VERSION "HNNBNNNYNNNNNNNNNNNNNNNNNNNNNNNNNNNNNNNNNN/4/%%%/4/'%**4NNN///"

NS_ :

BS_:

BU_: Aero_LB AFS_MLB Airbag_B8 BCM1_B8 Gateway_B8 Getriebe_AL551_651_B8 Getriebe_AL551_Q5_Hybrid Getriebe_SL_LB Lift_MLB_LB LWR_MLB Magnetic_Ride_LB Motor_MLB_AU48_AU416_Diesel Motor_MLB_B8_Q5_Otto Motor_MLB_Q5_Hybrid Niveau_LB Airbag_D4 BMS_Hybrid Daempfer_MLB EPB_MLB ESP Gateway Getriebe_AL551_951_D4_C7 Getriebe_AL551_Hybrid_D4_C7 Getriebe_DL382_MLB Getriebe_DL501_MLB Getriebe_VL381_MLB LEH_Hybrid LWS_D4 Motor2_MLB_D4_C7 Motor_MLB_AU64_AU57_Diesel Motor_MLB_BY_Otto Motor_MLB_C7_PHEV Motor_MLB_D4_C7_Hybrid Motor_MLB_D4_C7_Otto QSP SAK SAK2 SCR_MLB SCU

BO_ 2617042433 CCP_Soundaktor_DTO_01: 8 SAK
 SG_ CCP_Soundaktor_DTO_01_Data : 0|64@1+ (1,0) [0|1.84467440737096E+019] "" Vector__XXX

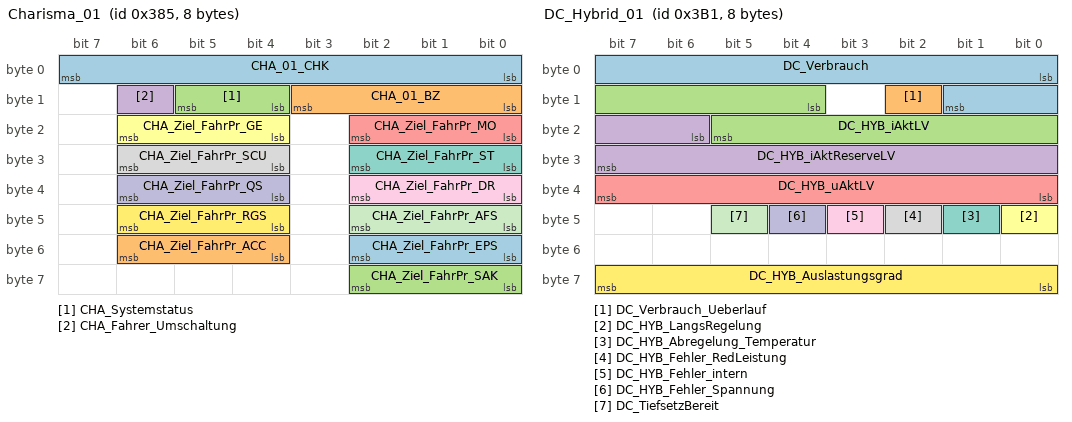
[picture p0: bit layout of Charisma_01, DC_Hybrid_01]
BO_ 901 Charisma_01: 8 Gateway
 SG_ CHA_01_CHK : 0|8@1+ (1,0) [0|255] ""  Daempfer_MLB,Getriebe_AL551_951_D4_C7,Getriebe_AL551_Hybrid_D4_C7,Getriebe_DL382_MLB,Getriebe_DL501_MLB,Getriebe_VL381_MLB,Motor_MLB_AU64_AU57_Diesel,Motor_MLB_BY_Otto,Motor_MLB_C7_PHEV,Motor_MLB_D4_C7_Hybrid,Motor_MLB_D4_C7_Otto,SCU
 SG_ CHA_01_BZ : 8|4@1+ (1,0) [0|15] "" Vector__XXX
 SG_ CHA_Systemstatus : 12|2@1+ (1,0) [0|3] ""  Daempfer_MLB,Getriebe_AL551_951_D4_C7,Getriebe_AL551_Hybrid_D4_C7,Getriebe_DL382_MLB,Getriebe_DL501_MLB,Getriebe_VL381_MLB,Motor_MLB_AU64_AU57_Diesel,Motor_MLB_BY_Otto,Motor_MLB_C7_PHEV,Motor_MLB_D4_C7_Hybrid,Motor_MLB_D4_C7_Otto,SAK,SAK2,SCU
 SG_ CHA_Fahrer_Umschaltung : 14|1@1+ (1,0) [0|1] "" Vector__XXX
 SG_ CHA_Ziel_FahrPr_MO : 16|3@1+ (1,0) [0|7] ""  Motor_MLB_AU64_AU57_Diesel,Motor_MLB_BY_Otto,Motor_MLB_C7_PHEV,Motor_MLB_D4_C7_Hybrid,Motor_MLB_D4_C7_Otto
 SG_ CHA_Ziel_FahrPr_GE : 20|3@1+ (1,0) [0|7] ""  Getriebe_AL551_951_D4_C7,Getriebe_AL551_Hybrid_D4_C7,Getriebe_DL382_MLB,Getriebe_DL501_MLB,Getriebe_VL381_MLB
 SG_ CHA_Ziel_FahrPr_ST : 24|3@1+ (1,0) [0|7] "" Vector__XXX
 SG_ CHA_Ziel_FahrPr_SCU : 28|3@1+ (1,0) [0|7] ""  SCU
 SG_ CHA_Ziel_FahrPr_DR : 32|3@1+ (1,0) [0|7] ""  Daempfer_MLB
 SG_ CHA_Ziel_FahrPr_QS : 36|3@1+ (1,0) [0|7] "" Vector__XXX
 SG_ CHA_Ziel_FahrPr_AFS : 40|3@1+ (1,0) [0|7] "" Vector__XXX
 SG_ CHA_Ziel_FahrPr_RGS : 44|3@1+ (1,0) [0|7] "" Vector__XXX
 SG_ CHA_Ziel_FahrPr_EPS : 48|3@1+ (1,0) [0|7] "" Vector__XXX
 SG_ CHA_Ziel_FahrPr_ACC : 52|3@1+ (1,0) [0|7] "" Vector__XXX
 SG_ CHA_Ziel_FahrPr_SAK : 56|3@1+ (1,0) [0|7] ""  Motor_MLB_AU64_AU57_Diesel,Motor_MLB_BY_Otto,Motor_MLB_C7_PHEV,Motor_MLB_D4_C7_Hybrid,Motor_MLB_D4_C7_Otto,SAK,SAK2

BO_ 918 Daempfer_01_FR: 8 Daempfer_MLB
 SG_ Daempfer_01_CHK : 0|8@1+ (1,0) [0|255] ""  Gateway
 SG_ Daempfer_01_BZ : 8|4@1+ (1,0) [0|15] ""  Gateway
 SG_ DR_Systemstatus : 12|3@1+ (1,0) [0|7] ""  Gateway
 SG_ LF_Texte : 15|2@1+ (1,0) [0|3] ""  Gateway
 SG_ DR_Taster : 17|1@1+ (1,0) [0|1] ""  Gateway
 SG_ DR_Gelbe_Warnlampe : 18|2@1+ (1,0) [0|3] ""  Gateway
 SG_ DR_Daempferreg_Texte : 20|4@1+ (1,0) [0|15] ""  Gateway
 SG_ DR_Charisma_FahrPr : 24|3@1+ (1,0) [0|7] ""  Gateway
 SG_ DR_Charisma_Status : 27|2@1+ (1,0) [0|3] ""  Gateway
 SG_ DR_Charisma_Umschaltung : 29|2@1+ (1,0) [0|3] ""  Gateway
 SG_ DR_Fahrzeugart : 32|4@1+ (1,0) [0|15] ""  Gateway
 SG_ LF_Warnung_Prio1 : 36|2@1+ (1,0) [0|3] ""  Gateway
 SG_ LF_Warnung_Prio2 : 38|2@1+ (1,0) [0|3] ""  Gateway
 SG_ DR_DynAGL_Warnlampe : 40|1@1+ (1,0) [0|1] ""  Gateway
 SG_ DR_Rote_Warnlampe : 41|2@1+ (1,0) [0|3] ""  Gateway
 SG_ NI_Status : 43|3@1+ (1,0) [0|7] ""  Gateway
 SG_ NR_Niveaufunktion_aktiv : 46|2@1+ (1,0) [0|3] ""  Gateway
 SG_ DR_KD_Fehler : 63|1@1+ (1,0) [0|1] ""  Gateway

BO_ 945 DC_Hybrid_01: 8 LEH_Hybrid
 SG_ DC_Verbrauch : 0|10@1+ (1,0) [0|1023] "Unit_WattSecond" Vector__XXX
 SG_ DC_Verbrauch_Ueberlauf : 10|1@1+ (1,0) [0|1] "" Vector__XXX
 SG_ DC_HYB_iAktLV : 12|10@1+ (1,-511) [-511|510] "Unit_Amper"  Gateway
 SG_ DC_HYB_iAktReserveLV : 22|10@1+ (1,-511) [-511|510] "Unit_Amper"  Gateway
 SG_ DC_HYB_uAktLV : 32|8@1+ (0.1,0) [0|25.3] "Unit_Volt"  Gateway
 SG_ DC_HYB_LangsRegelung : 40|1@1+ (1,0) [0|1] ""  Gateway
 SG_ DC_HYB_Abregelung_Temperatur : 41|1@1+ (1,0) [0|1] ""  Gateway
 SG_ DC_HYB_Fehler_RedLeistung : 42|1@1+ (1,0) [0|1] ""  Gateway
 SG_ DC_HYB_Fehler_intern : 43|1@1+ (1,0) [0|1] ""  Gateway
 SG_ DC_HYB_Fehler_Spannung : 44|1@1+ (1,0) [0|1] ""  Gateway
 SG_ DC_TiefsetzBereit : 45|1@1+ (1,0) [0|1] "" Vector__XXX
 SG_ DC_HYB_Auslastungsgrad : 56|8@1+ (0.4,0) [0|100] "Unit_PerCent" Vector__XXX

BO_ 2617027072 DEV_Airbag_01: 4 Airbag_D4
 SG_ DEV_Airbag_01 : 0|32@1+ (1,0) [0|4294967295] "" Vector__XXX

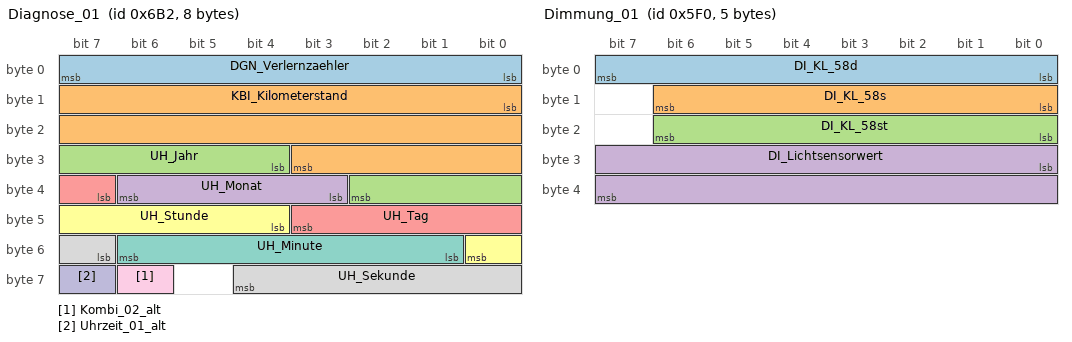
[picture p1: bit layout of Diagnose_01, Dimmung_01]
BO_ 1714 Diagnose_01: 8 Gateway
 SG_ DGN_Verlernzaehler : 0|8@1+ (1,0) [0|254] ""  Airbag_D4,BMS_Hybrid,Daempfer_MLB,EPB_MLB,Getriebe_AL551_951_D4_C7,Getriebe_AL551_Hybrid_D4_C7,LEH_Hybrid,SAK,SAK2,SCR_MLB,SCU
 SG_ KBI_Kilometerstand : 8|20@1+ (1,0) [0|1048573] "Unit_KiloMeter"  Airbag_D4,BMS_Hybrid,Daempfer_MLB,EPB_MLB,Getriebe_AL551_951_D4_C7,Getriebe_AL551_Hybrid_D4_C7,Getriebe_DL382_MLB,Getriebe_DL501_MLB,Getriebe_VL381_MLB,LEH_Hybrid,Motor_MLB_AU64_AU57_Diesel,Motor_MLB_BY_Otto,Motor_MLB_C7_PHEV,Motor_MLB_D4_C7_Hybrid,Motor_MLB_D4_C7_Otto,SAK,SAK2,SCR_MLB,SCU
 SG_ UH_Jahr : 28|7@1+ (1,2000) [2000|2127] "Unit_Year"  Airbag_D4,BMS_Hybrid,Daempfer_MLB,EPB_MLB,Getriebe_AL551_951_D4_C7,Getriebe_AL551_Hybrid_D4_C7,Getriebe_DL382_MLB,Getriebe_DL501_MLB,Getriebe_VL381_MLB,LEH_Hybrid,Motor_MLB_AU64_AU57_Diesel,Motor_MLB_BY_Otto,Motor_MLB_C7_PHEV,Motor_MLB_D4_C7_Hybrid,Motor_MLB_D4_C7_Otto,SAK,SAK2,SCR_MLB,SCU
 SG_ UH_Monat : 35|4@1+ (1,0) [1|12] "Unit_Month"  Airbag_D4,BMS_Hybrid,Daempfer_MLB,EPB_MLB,Getriebe_AL551_951_D4_C7,Getriebe_AL551_Hybrid_D4_C7,Getriebe_DL382_MLB,Getriebe_DL501_MLB,Getriebe_VL381_MLB,LEH_Hybrid,Motor_MLB_AU64_AU57_Diesel,Motor_MLB_BY_Otto,Motor_MLB_C7_PHEV,Motor_MLB_D4_C7_Hybrid,Motor_MLB_D4_C7_Otto,SAK,SAK2,SCR_MLB,SCU
 SG_ UH_Tag : 39|5@1+ (1,0) [1|31] "Unit_Day"  Airbag_D4,BMS_Hybrid,Daempfer_MLB,EPB_MLB,Getriebe_AL551_951_D4_C7,Getriebe_AL551_Hybrid_D4_C7,Getriebe_DL382_MLB,Getriebe_DL501_MLB,Getriebe_VL381_MLB,LEH_Hybrid,Motor_MLB_AU64_AU57_Diesel,Motor_MLB_BY_Otto,Motor_MLB_C7_PHEV,Motor_MLB_D4_C7_Hybrid,Motor_MLB_D4_C7_Otto,SAK,SAK2,SCR_MLB,SCU
 SG_ UH_Stunde : 44|5@1+ (1,0) [0|23] "Unit_Hours"  Airbag_D4,BMS_Hybrid,Daempfer_MLB,EPB_MLB,Getriebe_AL551_951_D4_C7,Getriebe_AL551_Hybrid_D4_C7,Getriebe_DL382_MLB,Getriebe_DL501_MLB,Getriebe_VL381_MLB,LEH_Hybrid,Motor_MLB_AU64_AU57_Diesel,Motor_MLB_BY_Otto,Motor_MLB_C7_PHEV,Motor_MLB_D4_C7_Hybrid,Motor_MLB_D4_C7_Otto,SAK,SAK2,SCR_MLB,SCU
 SG_ UH_Minute : 49|6@1+ (1,0) [0|59] "Unit_Minut"  Airbag_D4,BMS_Hybrid,Daempfer_MLB,EPB_MLB,Getriebe_AL551_951_D4_C7,Getriebe_AL551_Hybrid_D4_C7,Getriebe_DL382_MLB,Getriebe_DL501_MLB,Getriebe_VL381_MLB,LEH_Hybrid,Motor_MLB_AU64_AU57_Diesel,Motor_MLB_BY_Otto,Motor_MLB_C7_PHEV,Motor_MLB_D4_C7_Hybrid,Motor_MLB_D4_C7_Otto,SAK,SAK2,SCR_MLB,SCU
 SG_ UH_Sekunde : 55|6@1+ (1,0) [0|59] "Unit_Secon"  Airbag_D4,BMS_Hybrid,Daempfer_MLB,EPB_MLB,Getriebe_AL551_951_D4_C7,Getriebe_AL551_Hybrid_D4_C7,Getriebe_DL382_MLB,Getriebe_DL501_MLB,Getriebe_VL381_MLB,LEH_Hybrid,Motor_MLB_AU64_AU57_Diesel,Motor_MLB_BY_Otto,Motor_MLB_C7_PHEV,Motor_MLB_D4_C7_Hybrid,Motor_MLB_D4_C7_Otto,SAK,SAK2,SCR_MLB,SCU
 SG_ Kombi_02_alt : 62|1@1+ (1,0) [0|1] ""  Airbag_D4,BMS_Hybrid,EPB_MLB,Getriebe_AL551_951_D4_C7,Getriebe_AL551_Hybrid_D4_C7,Getriebe_DL382_MLB,Getriebe_DL501_MLB,Getriebe_VL381_MLB,LEH_Hybrid,SCR_MLB
 SG_ Uhrzeit_01_alt : 63|1@1+ (1,0) [0|1] ""  Airbag_D4,BMS_Hybrid,EPB_MLB,Getriebe_AL551_951_D4_C7,Getriebe_AL551_Hybrid_D4_C7,Getriebe_DL382_MLB,Getriebe_DL501_MLB,Getriebe_VL381_MLB,LEH_Hybrid,SCR_MLB

BO_ 1520 Dimmung_01: 5 Gateway
 SG_ DI_KL_58d : 0|8@1+ (1,0) [0|253] ""  Airbag_D4,EPB_MLB,Getriebe_AL551_951_D4_C7,Getriebe_AL551_Hybrid_D4_C7
 SG_ DI_KL_58s : 8|7@1+ (1,0) [0|100] "Unit_PerCent"  Getriebe_AL551_951_D4_C7,Getriebe_AL551_Hybrid_D4_C7
 SG_ DI_KL_58st : 16|7@1+ (1,0) [0|100] "Unit_PerCent"  Getriebe_AL551_951_D4_C7,Getriebe_AL551_Hybrid_D4_C7
 SG_ DI_Lichtsensorwert : 24|16@1+ (1,0) [0|65535] ""  Airbag_D4,Getriebe_AL551_951_D4_C7,Getriebe_AL551_Hybrid_D4_C7

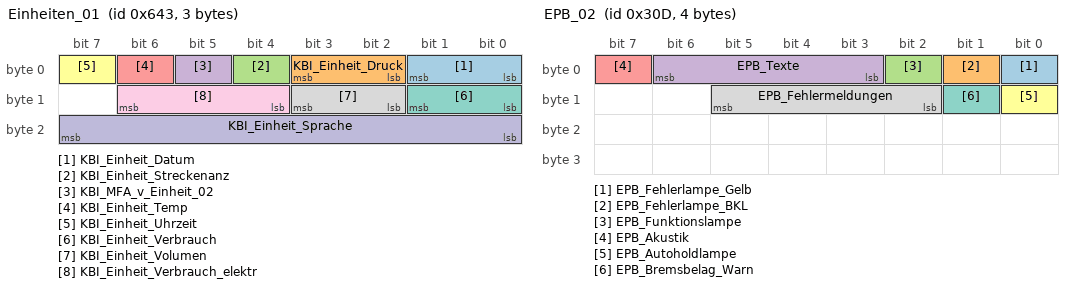
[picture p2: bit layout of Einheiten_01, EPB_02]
BO_ 1603 Einheiten_01: 3 Gateway
 SG_ KBI_Einheit_Datum : 0|2@1+ (1,0) [0|3] "" Vector__XXX
 SG_ KBI_Einheit_Druck : 2|2@1+ (1,0) [0|3] "" Vector__XXX
 SG_ KBI_Einheit_Streckenanz : 4|1@1+ (1,0) [0|1] ""  Motor_MLB_AU64_AU57_Diesel
 SG_ KBI_MFA_v_Einheit_02 : 5|1@1+ (1,0) [0|1] "" Vector__XXX
 SG_ KBI_Einheit_Temp : 6|1@1+ (1,0) [0|1] "" Vector__XXX
 SG_ KBI_Einheit_Uhrzeit : 7|1@1+ (1,0) [0|1] "" Vector__XXX
 SG_ KBI_Einheit_Verbrauch : 8|2@1+ (1,0) [0|3] "" Vector__XXX
 SG_ KBI_Einheit_Volumen : 10|2@1+ (1,0) [0|3] "" Vector__XXX
 SG_ KBI_Einheit_Verbrauch_elektr : 12|3@1+ (1,0) [0|7] "" Vector__XXX
 SG_ KBI_Einheit_Sprache : 16|8@1+ (1,0) [0|255] "" Vector__XXX

BO_ 1627 EM_Hybrid_01: 8 LEH_Hybrid
 SG_ EM_HYB_KD_Fehler : 15|1@1+ (1,0) [0|1] ""  Gateway

BO_ 260 EPB_01: 8 EPB_MLB
 SG_ EPB_01_CHK : 0|8@1+ (1,0) [0|255] ""  Gateway,Motor_MLB_AU64_AU57_Diesel,Motor_MLB_BY_Otto,Motor_MLB_C7_PHEV,Motor_MLB_D4_C7_Hybrid,Motor_MLB_D4_C7_Otto
 SG_ EPB_01_BZ : 8|4@1+ (1,0) [0|15] ""  Gateway,Motor_MLB_AU64_AU57_Diesel,Motor_MLB_BY_Otto,Motor_MLB_C7_PHEV,Motor_MLB_D4_C7_Hybrid,Motor_MLB_D4_C7_Otto
 SG_ EPB_QBit_Laengsbeschleunigung : 12|1@1+ (1,0) [0|1] ""  Gateway,Getriebe_AL551_951_D4_C7,Getriebe_AL551_Hybrid_D4_C7
 SG_ EPB_QBit_Pedalweg_Kuppl : 13|1@1+ (1,0) [0|1] ""  Gateway,Motor_MLB_AU64_AU57_Diesel,Motor_MLB_BY_Otto,Motor_MLB_C7_PHEV,Motor_MLB_D4_C7_Hybrid,Motor_MLB_D4_C7_Otto
 SG_ EPB_BCM2_Motor_Wakeup : 14|1@1+ (1,0) [0|1] ""  Gateway
 SG_ EPB_Freig_Verzoeg_Anf : 15|1@1+ (1,0) [0|1] ""  Gateway,Getriebe_AL551_951_D4_C7,Getriebe_AL551_Hybrid_D4_C7,Motor_MLB_AU64_AU57_Diesel,Motor_MLB_BY_Otto,Motor_MLB_C7_PHEV,Motor_MLB_D4_C7_Hybrid,Motor_MLB_D4_C7_Otto
 SG_ EPB_Verzoeg_Anf : 16|8@1+ (0.048,-7.968) [-7.968|4.224] "Unit_MeterPerSeconSquar"  Gateway
 SG_ EPB_Laengsbeschleunigung : 24|8@1+ (1,-128) [-128|126] "Unit_PerCentOfForceOfGravi"  Gateway,Getriebe_AL551_951_D4_C7,Getriebe_AL551_Hybrid_D4_C7
 SG_ EPB_Pedalweg_Kuppl : 32|8@1+ (0.4,0) [8|92] "Unit_PerCent"  Gateway,Motor_MLB_AU64_AU57_Diesel,Motor_MLB_BY_Otto,Motor_MLB_C7_PHEV,Motor_MLB_D4_C7_Hybrid,Motor_MLB_D4_C7_Otto
 SG_ HMS_Konsistenz_HVLM : 40|1@1+ (1,0) [0|1] ""  Gateway
 SG_ HMS_Systemstatus : 41|4@1+ (1,0) [0|15] ""  Gateway
 SG_ EPB_Anfahrwunsch_erkannt : 48|1@1+ (1,0) [0|1] ""  Gateway
 SG_ EPB_DAA_Randbed_erf : 49|1@1+ (1,0) [0|1] ""  Gateway
 SG_ EPB_Fehlerstatus : 50|2@1+ (1,0) [0|3] ""  Gateway
 SG_ EPB_Schalterposition : 52|2@1+ (1,0) [0|3] ""  Gateway,Getriebe_AL551_951_D4_C7,Getriebe_AL551_Hybrid_D4_C7,Motor_MLB_AU64_AU57_Diesel,Motor_MLB_BY_Otto,Motor_MLB_C7_PHEV,Motor_MLB_D4_C7_Hybrid,Motor_MLB_D4_C7_Otto
 SG_ EPB_QBit_Schalterpos : 54|1@1+ (1,0) [0|1] ""  Gateway,Getriebe_AL551_951_D4_C7,Getriebe_AL551_Hybrid_D4_C7,Motor_MLB_AU64_AU57_Diesel,Motor_MLB_BY_Otto,Motor_MLB_C7_PHEV,Motor_MLB_D4_C7_Hybrid,Motor_MLB_D4_C7_Otto
 SG_ EPB_Konsistenz_ACC : 55|1@1+ (1,0) [0|1] ""  Gateway
 SG_ EPB_Spannkraft : 56|5@1+ (1,0) [0|29] "Unit_KiloNewto"  Gateway,Getriebe_AL551_951_D4_C7,Getriebe_AL551_Hybrid_D4_C7,Getriebe_DL382_MLB,Getriebe_DL501_MLB,Getriebe_VL381_MLB
 SG_ EPB_Status : 61|2@1+ (1,0) [0|3] ""  Gateway,Getriebe_AL551_951_D4_C7,Getriebe_AL551_Hybrid_D4_C7,Getriebe_DL382_MLB,Getriebe_DL501_MLB,Motor_MLB_AU64_AU57_Diesel,Motor_MLB_BY_Otto,Motor_MLB_C7_PHEV,Motor_MLB_D4_C7_Hybrid,Motor_MLB_D4_C7_Otto
 SG_ EPB_KD_Fehler : 63|1@1+ (1,0) [0|1] ""  Gateway

BO_ 781 EPB_02: 4 EPB_MLB
 SG_ EPB_Fehlerlampe_Gelb : 0|1@1+ (1,0) [0|1] ""  Gateway
 SG_ EPB_Fehlerlampe_BKL : 1|1@1+ (1,0) [0|1] ""  Gateway
 SG_ EPB_Funktionslampe : 2|1@1+ (1,0) [0|1] ""  Gateway
 SG_ EPB_Texte : 3|4@1+ (1,0) [0|15] ""  Gateway
 SG_ EPB_Akustik : 7|1@1+ (1,0) [0|1] ""  Gateway
 SG_ EPB_Autoholdlampe : 8|1@1+ (1,0) [0|1] ""  Gateway
 SG_ EPB_Bremsbelag_Warn : 9|1@1+ (1,0) [0|1] ""  Gateway
 SG_ EPB_Fehlermeldungen : 10|4@1+ (1,0) [0|15] ""  Gateway

BO_ 256 ESP_01: 8 Gateway
 SG_ ESP_01_CHK : 0|8@1+ (1,0) [0|255] ""  Airbag_D4,BMS_Hybrid,EPB_MLB,Getriebe_AL551_951_D4_C7,Getriebe_AL551_Hybrid_D4_C7,Getriebe_DL382_MLB,Getriebe_DL501_MLB,Getriebe_VL381_MLB,LEH_Hybrid,Motor_MLB_AU64_AU57_Diesel,Motor_MLB_BY_Otto,Motor_MLB_C7_PHEV,Motor_MLB_D4_C7_Hybrid,Motor_MLB_D4_C7_Otto
 SG_ ESP_01_BZ : 8|4@1+ (1,0) [0|15] ""  Airbag_D4,BMS_Hybrid,EPB_MLB,Getriebe_AL551_951_D4_C7,Getriebe_AL551_Hybrid_D4_C7,Getriebe_DL382_MLB,Getriebe_DL501_MLB,Getriebe_VL381_MLB,LEH_Hybrid,Motor_MLB_AU64_AU57_Diesel,Motor_MLB_BY_Otto,Motor_MLB_C7_PHEV,Motor_MLB_D4_C7_Hybrid,Motor_MLB_D4_C7_Otto
 SG_ ASR_Moment_langsam : 12|10@1+ (1,0) [0|1021] ""  Airbag_D4,Getriebe_AL551_951_D4_C7,Getriebe_AL551_Hybrid_D4_C7,Getriebe_DL382_MLB,Getriebe_DL501_MLB,Motor_MLB_AU64_AU57_Diesel,Motor_MLB_BY_Otto,Motor_MLB_C7_PHEV,Motor_MLB_D4_C7_Hybrid,Motor_MLB_D4_C7_Otto
 SG_ ASR_MSR_Moment_schnell : 22|10@1+ (1,0) [0|1021] ""  Airbag_D4,Getriebe_AL551_951_D4_C7,Getriebe_AL551_Hybrid_D4_C7,Getriebe_DL382_MLB,Getriebe_DL501_MLB,Motor_MLB_AU64_AU57_Diesel,Motor_MLB_BY_Otto,Motor_MLB_C7_PHEV,Motor_MLB_D4_C7_Hybrid,Motor_MLB_D4_C7_Otto
 SG_ ESP_v_Signal : 32|16@1+ (0.01,0) [0|655.32] "Unit_KiloMeterPerHour"  Airbag_D4,BMS_Hybrid,Getriebe_AL551_951_D4_C7,Getriebe_AL551_Hybrid_D4_C7,Getriebe_DL382_MLB,Getriebe_DL501_MLB,Getriebe_VL381_MLB,LEH_Hybrid,Motor_MLB_AU64_AU57_Diesel,Motor_MLB_BY_Otto,Motor_MLB_C7_PHEV,Motor_MLB_D4_C7_Hybrid,Motor_MLB_D4_C7_Otto,SAK,SAK2,SCR_MLB
 SG_ ASR_Tastung_passiv : 48|1@1+ (1,0) [0|1] ""  Airbag_D4,Getriebe_AL551_951_D4_C7,Getriebe_AL551_Hybrid_D4_C7,Getriebe_DL382_MLB,Getriebe_DL501_MLB,Getriebe_VL381_MLB,Motor_MLB_AU64_AU57_Diesel,Motor_MLB_BY_Otto,Motor_MLB_C7_PHEV,Motor_MLB_D4_C7_Hybrid,Motor_MLB_D4_C7_Otto
 SG_ ESP_Tastung_passiv : 49|1@1+ (1,0) [0|1] ""  Airbag_D4,Getriebe_AL551_951_D4_C7,Getriebe_AL551_Hybrid_D4_C7,Getriebe_DL382_MLB,Getriebe_DL501_MLB,Getriebe_VL381_MLB,Motor_MLB_AU64_AU57_Diesel,Motor_MLB_BY_Otto,Motor_MLB_C7_PHEV,Motor_MLB_D4_C7_Hybrid,Motor_MLB_D4_C7_Otto
 SG_ ESP_Systemstatus : 50|1@1+ (1,0) [0|1] ""  Airbag_D4,Getriebe_DL382_MLB,Getriebe_DL501_MLB,Motor_MLB_AU64_AU57_Diesel,Motor_MLB_BY_Otto,Motor_MLB_C7_PHEV,Motor_MLB_D4_C7_Hybrid,Motor_MLB_D4_C7_Otto
 SG_ ASR_Schalteingriff : 51|2@1+ (1,0) [0|3] ""  Airbag_D4,Getriebe_AL551_951_D4_C7,Getriebe_AL551_Hybrid_D4_C7,Getriebe_DL382_MLB,Getriebe_DL501_MLB,Getriebe_VL381_MLB
 SG_ OBD_Schlechtweg : 53|1@1+ (1,0) [0|1] ""  Motor_MLB_BY_Otto,Motor_MLB_C7_PHEV,Motor_MLB_D4_C7_Hybrid,Motor_MLB_D4_C7_Otto
 SG_ OBD_QBit_Schlechtweg : 54|1@1+ (1,0) [0|1] ""  Motor_MLB_BY_Otto,Motor_MLB_C7_PHEV,Motor_MLB_D4_C7_Hybrid,Motor_MLB_D4_C7_Otto
 SG_ ESP_QBit_v_Signal : 55|1@1+ (1,0) [0|1] ""  Airbag_D4,Getriebe_AL551_951_D4_C7,Getriebe_AL551_Hybrid_D4_C7,Getriebe_DL382_MLB,Getriebe_DL501_MLB,Getriebe_VL381_MLB,LEH_Hybrid,Motor_MLB_AU64_AU57_Diesel,Motor_MLB_BY_Otto,Motor_MLB_C7_PHEV,Motor_MLB_D4_C7_Hybrid,Motor_MLB_D4_C7_Otto
 SG_ ABS_Bremsung : 56|1@1+ (1,0) [0|1] ""  Airbag_D4,EPB_MLB,Getriebe_AL551_951_D4_C7,Getriebe_AL551_Hybrid_D4_C7,Getriebe_DL382_MLB,Getriebe_DL501_MLB,Getriebe_VL381_MLB,Motor_MLB_AU64_AU57_Diesel,Motor_MLB_BY_Otto,Motor_MLB_C7_PHEV,Motor_MLB_D4_C7_Hybrid,Motor_MLB_D4_C7_Otto
 SG_ ASR_Anf : 57|1@1+ (1,0) [0|1] ""  Airbag_D4,Getriebe_AL551_951_D4_C7,Getriebe_AL551_Hybrid_D4_C7,Getriebe_DL382_MLB,Getriebe_DL501_MLB,Getriebe_VL381_MLB,Motor_MLB_AU64_AU57_Diesel,Motor_MLB_BY_Otto,Motor_MLB_C7_PHEV,Motor_MLB_D4_C7_Hybrid,Motor_MLB_D4_C7_Otto
 SG_ MSR_Anf : 58|1@1+ (1,0) [0|1] ""  Airbag_D4,Getriebe_DL382_MLB,Getriebe_DL501_MLB,Getriebe_VL381_MLB,Motor_MLB_AU64_AU57_Diesel,Motor_MLB_BY_Otto,Motor_MLB_C7_PHEV,Motor_MLB_D4_C7_Hybrid,Motor_MLB_D4_C7_Otto
 SG_ EBV_Eingriff : 59|1@1+ (1,0) [0|1] ""  Airbag_D4,Getriebe_AL551_951_D4_C7,Getriebe_AL551_Hybrid_D4_C7,Getriebe_DL382_MLB,Getriebe_DL501_MLB,Motor_MLB_AU64_AU57_Diesel,Motor_MLB_BY_Otto,Motor_MLB_C7_PHEV,Motor_MLB_D4_C7_Hybrid,Motor_MLB_D4_C7_Otto
 SG_ EDS_Eingriff : 60|1@1+ (1,0) [0|1] ""  Airbag_D4,Getriebe_AL551_951_D4_C7,Getriebe_AL551_Hybrid_D4_C7,Getriebe_DL382_MLB,Getriebe_DL501_MLB,Getriebe_VL381_MLB,Motor_MLB_AU64_AU57_Diesel,Motor_MLB_BY_Otto,Motor_MLB_C7_PHEV,Motor_MLB_D4_C7_Hybrid,Motor_MLB_D4_C7_Otto
 SG_ ESP_Eingriff : 61|1@1+ (1,0) [0|1] ""  Airbag_D4,Getriebe_AL551_951_D4_C7,Getriebe_AL551_Hybrid_D4_C7,Getriebe_DL382_MLB,Getriebe_DL501_MLB,Getriebe_VL381_MLB,Motor_MLB_AU64_AU57_Diesel,Motor_MLB_BY_Otto,Motor_MLB_C7_PHEV,Motor_MLB_D4_C7_Hybrid,Motor_MLB_D4_C7_Otto
 SG_ ESP_ASP : 62|1@1+ (1,0) [0|1] ""  Motor_MLB_AU64_AU57_Diesel,Motor_MLB_BY_Otto,Motor_MLB_C7_PHEV,Motor_MLB_D4_C7_Hybrid,Motor_MLB_D4_C7_Otto
 SG_ ESP_KD_Fehler : 63|1@1+ (1,0) [0|1] "" Vector__XXX

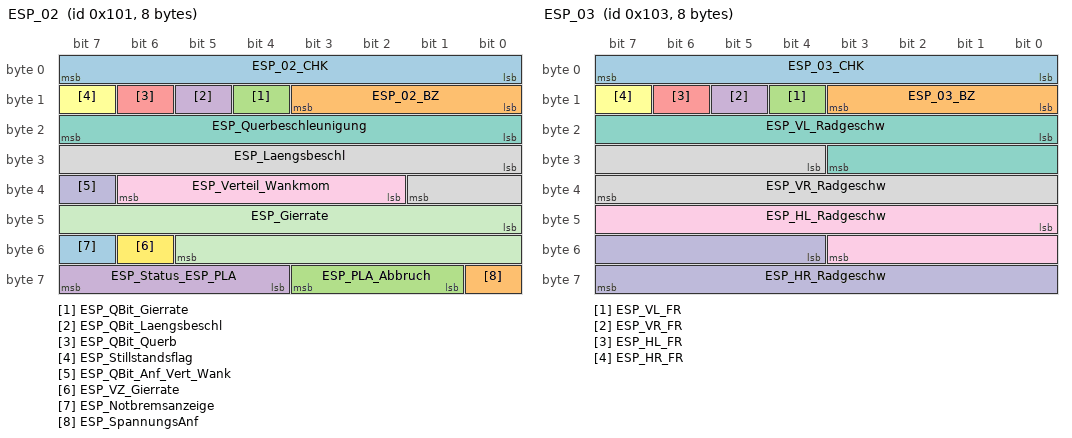
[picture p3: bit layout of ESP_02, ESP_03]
BO_ 257 ESP_02: 8 Gateway
 SG_ ESP_02_CHK : 0|8@1+ (1,0) [0|255] ""  Airbag_D4,EPB_MLB,Getriebe_AL551_951_D4_C7,Getriebe_AL551_Hybrid_D4_C7,Getriebe_DL382_MLB,Getriebe_DL501_MLB,Getriebe_VL381_MLB,Motor_MLB_AU64_AU57_Diesel,Motor_MLB_BY_Otto,Motor_MLB_C7_PHEV,Motor_MLB_D4_C7_Hybrid,Motor_MLB_D4_C7_Otto
 SG_ ESP_02_BZ : 8|4@1+ (1,0) [0|15] ""  Airbag_D4,EPB_MLB,Getriebe_AL551_951_D4_C7,Getriebe_AL551_Hybrid_D4_C7,Getriebe_DL382_MLB,Getriebe_DL501_MLB,Getriebe_VL381_MLB,Motor_MLB_AU64_AU57_Diesel,Motor_MLB_BY_Otto,Motor_MLB_C7_PHEV,Motor_MLB_D4_C7_Hybrid,Motor_MLB_D4_C7_Otto
 SG_ ESP_QBit_Gierrate : 12|1@1+ (1,0) [0|1] ""  Airbag_D4
 SG_ ESP_QBit_Laengsbeschl : 13|1@1+ (1,0) [0|1] ""  Airbag_D4,EPB_MLB,Getriebe_AL551_951_D4_C7,Getriebe_AL551_Hybrid_D4_C7,Getriebe_DL382_MLB,Getriebe_DL501_MLB,Getriebe_VL381_MLB,Motor_MLB_AU64_AU57_Diesel,Motor_MLB_BY_Otto,Motor_MLB_C7_PHEV,Motor_MLB_D4_C7_Hybrid,Motor_MLB_D4_C7_Otto
 SG_ ESP_QBit_Querb : 14|1@1+ (1,0) [0|1] ""  Airbag_D4,Getriebe_AL551_951_D4_C7,Getriebe_AL551_Hybrid_D4_C7,Getriebe_DL382_MLB,Getriebe_DL501_MLB,Motor_MLB_AU64_AU57_Diesel,Motor_MLB_BY_Otto,Motor_MLB_C7_PHEV,Motor_MLB_D4_C7_Hybrid,Motor_MLB_D4_C7_Otto
 SG_ ESP_Stillstandsflag : 15|1@1+ (1,0) [0|1] ""  Getriebe_DL382_MLB,Getriebe_DL501_MLB,Motor_MLB_AU64_AU57_Diesel,Motor_MLB_BY_Otto,Motor_MLB_C7_PHEV,Motor_MLB_D4_C7_Hybrid,Motor_MLB_D4_C7_Otto
 SG_ ESP_Querbeschleunigung : 16|8@1+ (0.01,-1.27) [-1.27|1.27] "Unit_ForceOfGravi"  Airbag_D4,Getriebe_AL551_951_D4_C7,Getriebe_AL551_Hybrid_D4_C7,Getriebe_DL382_MLB,Getriebe_DL501_MLB,Motor_MLB_AU64_AU57_Diesel,Motor_MLB_BY_Otto,Motor_MLB_C7_PHEV,Motor_MLB_D4_C7_Hybrid,Motor_MLB_D4_C7_Otto
 SG_ ESP_Laengsbeschl : 24|10@1+ (0.03125,-16) [-16|15.90625] "Unit_MeterPerSeconSquar"  Airbag_D4,EPB_MLB,Getriebe_AL551_951_D4_C7,Getriebe_AL551_Hybrid_D4_C7,Getriebe_DL382_MLB,Getriebe_DL501_MLB,Getriebe_VL381_MLB,Motor_MLB_AU64_AU57_Diesel,Motor_MLB_BY_Otto,Motor_MLB_C7_PHEV,Motor_MLB_D4_C7_Hybrid,Motor_MLB_D4_C7_Otto
 SG_ ESP_Verteil_Wankmom : 34|5@1+ (0.1,-1) [-1|1] "" Vector__XXX
 SG_ ESP_QBit_Anf_Vert_Wank : 39|1@1+ (1,0) [0|1] "" Vector__XXX
 SG_ ESP_Gierrate : 40|14@1+ (0.01,0) [0|163.82] "Unit_DegreOfArcPerSecon"  Airbag_D4
 SG_ ESP_VZ_Gierrate : 54|1@1+ (1,0) [0|1] ""  Airbag_D4
 SG_ ESP_Notbremsanzeige : 55|1@1+ (1,0) [0|1] "" Vector__XXX
 SG_ ESP_SpannungsAnf : 56|1@1+ (1,0) [0|1] "" Vector__XXX
 SG_ ESP_PLA_Abbruch : 57|3@1+ (1,0) [0|7] "" Vector__XXX
 SG_ ESP_Status_ESP_PLA : 60|4@1+ (1,0) [0|15] "" Vector__XXX

BO_ 259 ESP_03: 8 Gateway
 SG_ ESP_03_CHK : 0|8@1+ (1,0) [0|255] ""  Airbag_D4,EPB_MLB,Getriebe_AL551_951_D4_C7,Getriebe_AL551_Hybrid_D4_C7,Getriebe_DL382_MLB,Getriebe_DL501_MLB,Getriebe_VL381_MLB,LWS_D4,Motor_MLB_AU64_AU57_Diesel,Motor_MLB_BY_Otto,Motor_MLB_C7_PHEV,Motor_MLB_D4_C7_Hybrid,Motor_MLB_D4_C7_Otto,SCU
 SG_ ESP_03_BZ : 8|4@1+ (1,0) [0|15] ""  Airbag_D4,EPB_MLB,Getriebe_AL551_951_D4_C7,Getriebe_AL551_Hybrid_D4_C7,Getriebe_DL382_MLB,Getriebe_DL501_MLB,Getriebe_VL381_MLB,LWS_D4,Motor_MLB_AU64_AU57_Diesel,Motor_MLB_BY_Otto,Motor_MLB_C7_PHEV,Motor_MLB_D4_C7_Hybrid,Motor_MLB_D4_C7_Otto,SCU
 SG_ ESP_VL_FR : 12|1@1+ (1,0) [0|1] ""  Airbag_D4,EPB_MLB,Getriebe_AL551_951_D4_C7,Getriebe_AL551_Hybrid_D4_C7,Getriebe_DL382_MLB,Getriebe_DL501_MLB,Motor_MLB_AU64_AU57_Diesel,Motor_MLB_BY_Otto,Motor_MLB_C7_PHEV,Motor_MLB_D4_C7_Hybrid,Motor_MLB_D4_C7_Otto,SCU
 SG_ ESP_VR_FR : 13|1@1+ (1,0) [0|1] ""  Airbag_D4,EPB_MLB,Getriebe_AL551_951_D4_C7,Getriebe_AL551_Hybrid_D4_C7,Getriebe_DL382_MLB,Getriebe_DL501_MLB,Motor_MLB_AU64_AU57_Diesel,Motor_MLB_BY_Otto,Motor_MLB_C7_PHEV,Motor_MLB_D4_C7_Hybrid,Motor_MLB_D4_C7_Otto,SCU
 SG_ ESP_HL_FR : 14|1@1+ (1,0) [0|1] ""  Airbag_D4,EPB_MLB,Getriebe_AL551_951_D4_C7,Getriebe_AL551_Hybrid_D4_C7,Getriebe_DL382_MLB,Getriebe_DL501_MLB,Motor_MLB_AU64_AU57_Diesel,Motor_MLB_BY_Otto,Motor_MLB_C7_PHEV,Motor_MLB_D4_C7_Hybrid,Motor_MLB_D4_C7_Otto,SCU
 SG_ ESP_HR_FR : 15|1@1+ (1,0) [0|1] ""  Airbag_D4,EPB_MLB,Getriebe_AL551_951_D4_C7,Getriebe_AL551_Hybrid_D4_C7,Getriebe_DL382_MLB,Getriebe_DL501_MLB,Motor_MLB_AU64_AU57_Diesel,Motor_MLB_BY_Otto,Motor_MLB_C7_PHEV,Motor_MLB_D4_C7_Hybrid,Motor_MLB_D4_C7_Otto,SCU
 SG_ ESP_VL_Radgeschw : 16|12@1+ (0.1,0) [0|409.2] "Unit_KiloMeterPerHour"  Airbag_D4,EPB_MLB,Getriebe_AL551_951_D4_C7,Getriebe_AL551_Hybrid_D4_C7,Getriebe_DL382_MLB,Getriebe_DL501_MLB,Getriebe_VL381_MLB,LWS_D4,Motor_MLB_AU64_AU57_Diesel,Motor_MLB_BY_Otto,Motor_MLB_C7_PHEV,Motor_MLB_D4_C7_Hybrid,Motor_MLB_D4_C7_Otto,SCU
 SG_ ESP_VR_Radgeschw : 28|12@1+ (0.1,0) [0|409.2] "Unit_KiloMeterPerHour"  Airbag_D4,EPB_MLB,Getriebe_AL551_951_D4_C7,Getriebe_AL551_Hybrid_D4_C7,Getriebe_DL382_MLB,Getriebe_DL501_MLB,Getriebe_VL381_MLB,LWS_D4,Motor_MLB_AU64_AU57_Diesel,Motor_MLB_BY_Otto,Motor_MLB_C7_PHEV,Motor_MLB_D4_C7_Hybrid,Motor_MLB_D4_C7_Otto,SCU
 SG_ ESP_HL_Radgeschw : 40|12@1+ (0.1,0) [0|409.2] "Unit_KiloMeterPerHour"  Airbag_D4,EPB_MLB,Getriebe_AL551_951_D4_C7,Getriebe_AL551_Hybrid_D4_C7,Getriebe_DL382_MLB,Getriebe_DL501_MLB,Getriebe_VL381_MLB,LWS_D4,Motor_MLB_AU64_AU57_Diesel,Motor_MLB_BY_Otto,Motor_MLB_C7_PHEV,Motor_MLB_D4_C7_Hybrid,Motor_MLB_D4_C7_Otto,SCU
 SG_ ESP_HR_Radgeschw : 52|12@1+ (0.1,0) [0|409.2] "Unit_KiloMeterPerHour"  Airbag_D4,EPB_MLB,Getriebe_AL551_951_D4_C7,Getriebe_AL551_Hybrid_D4_C7,Getriebe_DL382_MLB,Getriebe_DL501_MLB,Getriebe_VL381_MLB,LWS_D4,Motor_MLB_AU64_AU57_Diesel,Motor_MLB_BY_Otto,Motor_MLB_C7_PHEV,Motor_MLB_D4_C7_Hybrid,Motor_MLB_D4_C7_Otto,SCU

BO_ 776 ESP_04: 8 Gateway
 SG_ ESP_Meldungen : 0|3@1+ (1,0) [0|7] "" Vector__XXX
 SG_ ESP_HDC_FktLampe : 3|1@1+ (1,0) [0|1] "" Vector__XXX
 SG_ ESP_Lampe : 4|1@1+ (1,0) [0|1] "" Vector__XXX
 SG_ ABS_Lampe : 5|1@1+ (1,0) [0|1] "" Vector__XXX
 SG_ BK_Lampe : 6|1@1+ (1,0) [0|1] "" Vector__XXX
 SG_ ESP_Akustik : 7|2@1+ (1,0) [0|3] "" Vector__XXX
 SG_ ESP_Diagnose : 9|1@1+ (1,0) [0|1] ""  SCU
 SG_ ESP_Textanzeigen_02 : 10|5@1+ (1,0) [0|31] "" Vector__XXX
 SG_ ESP_Off_Lampe : 15|1@1+ (1,0) [0|1] "" Vector__XXX
 SG_ ESP_m_Raddrehz : 16|15@1+ (0.002,0) [0|65.278] "Unit_Hertz" Vector__XXX
 SG_ ESP_ASR_Lampe : 31|1@1+ (1,0) [0|1] "" Vector__XXX
 SG_ ESP_Wegimp_VA : 32|11@1+ (1,0) [0|2047] "" Vector__XXX
 SG_ ESP_Fehlerstatus_Wegimp : 43|1@1+ (1,0) [0|1] "" Vector__XXX
 SG_ ESP_Wegimp_Ueberlauf : 44|1@1+ (1,0) [0|1] "" Vector__XXX
 SG_ ESP_QBit_Wegimp_VA : 45|1@1+ (1,0) [0|1] "" Vector__XXX
 SG_ ESP_Displaywarnungen : 46|2@1+ (1,0) [0|3] "" Vector__XXX
 SG_ ESP_HDC_Regelgeschw : 48|7@1+ (0.32,0) [0.32|39.68] "Unit_KiloMeterPerHour" Vector__XXX
 SG_ ESP_BKV_Warnung : 55|1@1+ (1,0) [0|1] "" Vector__XXX
 SG_ ESP_Zaehnezahl : 56|8@1+ (1,0) [0|255] "" Vector__XXX

BO_ 262 ESP_05: 8 Gateway
 SG_ ESP_05_CHK : 0|8@1+ (1,0) [0|255] ""  EPB_MLB,Getriebe_AL551_951_D4_C7,Getriebe_AL551_Hybrid_D4_C7,Getriebe_DL382_MLB,Getriebe_DL501_MLB,Getriebe_VL381_MLB,Motor_MLB_AU64_AU57_Diesel,Motor_MLB_BY_Otto,Motor_MLB_C7_PHEV,Motor_MLB_D4_C7_Hybrid,Motor_MLB_D4_C7_Otto,SCU
 SG_ ESP_05_BZ : 8|4@1+ (1,0) [0|15] ""  EPB_MLB,Getriebe_AL551_951_D4_C7,Getriebe_AL551_Hybrid_D4_C7,Getriebe_DL382_MLB,Getriebe_DL501_MLB,Getriebe_VL381_MLB,Motor_MLB_AU64_AU57_Diesel,Motor_MLB_BY_Otto,Motor_MLB_C7_PHEV,Motor_MLB_D4_C7_Hybrid,Motor_MLB_D4_C7_Otto,SCU
 SG_ ESP_QBit_Bremsdruck : 12|1@1+ (1,0) [0|1] ""  EPB_MLB,Getriebe_AL551_951_D4_C7,Getriebe_AL551_Hybrid_D4_C7,Getriebe_DL382_MLB,Getriebe_DL501_MLB,Motor_MLB_AU64_AU57_Diesel,Motor_MLB_BY_Otto,Motor_MLB_C7_PHEV,Motor_MLB_D4_C7_Hybrid,Motor_MLB_D4_C7_Otto
 SG_ ESP_QBit_Fahrer_bremst : 13|1@1+ (1,0) [0|1] ""  Motor_MLB_AU64_AU57_Diesel,Motor_MLB_BY_Otto,Motor_MLB_C7_PHEV,Motor_MLB_D4_C7_Hybrid,Motor_MLB_D4_C7_Otto
 SG_ ESP_Schwelle_Unterdruck : 14|2@1+ (1,0) [0|3] "" Vector__XXX
 SG_ ESP_Bremsdruck : 16|10@1+ (0.3,-30) [-30|276.6] "Unit_Bar"  EPB_MLB,Getriebe_AL551_951_D4_C7,Getriebe_AL551_Hybrid_D4_C7,Getriebe_DL382_MLB,Getriebe_DL501_MLB,Motor_MLB_AU64_AU57_Diesel,Motor_MLB_BY_Otto,Motor_MLB_C7_PHEV,Motor_MLB_D4_C7_Hybrid,Motor_MLB_D4_C7_Otto
 SG_ ESP_Fahrer_bremst : 26|1@1+ (1,0) [0|1] ""  Motor_MLB_AU64_AU57_Diesel,Motor_MLB_BY_Otto,Motor_MLB_C7_PHEV,Motor_MLB_D4_C7_Hybrid,Motor_MLB_D4_C7_Otto
 SG_ ESP_Verz_TSK_aktiv : 27|1@1+ (1,0) [0|1] ""  Getriebe_AL551_951_D4_C7,Getriebe_AL551_Hybrid_D4_C7,Motor_MLB_AU64_AU57_Diesel,Motor_MLB_BY_Otto,Motor_MLB_C7_PHEV,Motor_MLB_D4_C7_Hybrid,Motor_MLB_D4_C7_Otto
 SG_ ESP_Lenkeingriff_ADS : 28|1@1+ (1,0) [0|1] ""  Motor_MLB_AU64_AU57_Diesel,Motor_MLB_BY_Otto,Motor_MLB_C7_PHEV,Motor_MLB_D4_C7_Hybrid,Motor_MLB_D4_C7_Otto,SCU
 SG_ ESP_Konsistenz_TSK : 29|1@1+ (1,0) [0|1] ""  Motor_MLB_AU64_AU57_Diesel,Motor_MLB_BY_Otto,Motor_MLB_C7_PHEV,Motor_MLB_D4_C7_Hybrid,Motor_MLB_D4_C7_Otto
 SG_ ESP_Bremsruck_AWV2 : 30|1@1+ (1,0) [0|1] "" Vector__XXX
 SG_ ESP_Konsistenz_AWV2 : 31|1@1+ (1,0) [0|1] "" Vector__XXX
 SG_ ECD_Fehler : 32|1@1+ (1,0) [0|1] ""  Motor_MLB_AU64_AU57_Diesel,Motor_MLB_BY_Otto,Motor_MLB_C7_PHEV,Motor_MLB_D4_C7_Hybrid,Motor_MLB_D4_C7_Otto
 SG_ ECD_nicht_verfuegbar : 33|1@1+ (1,0) [0|1] ""  Motor_MLB_AU64_AU57_Diesel,Motor_MLB_BY_Otto,Motor_MLB_C7_PHEV,Motor_MLB_D4_C7_Hybrid,Motor_MLB_D4_C7_Otto
 SG_ ESP_Status_Bremsentemp : 34|1@1+ (1,0) [0|1] ""  Motor_MLB_AU64_AU57_Diesel,Motor_MLB_BY_Otto,Motor_MLB_C7_PHEV,Motor_MLB_D4_C7_Hybrid,Motor_MLB_D4_C7_Otto
 SG_ ESP_Autohold_Standby : 35|1@1+ (1,0) [0|1] ""  EPB_MLB,Getriebe_AL551_951_D4_C7,Getriebe_AL551_Hybrid_D4_C7,Motor_MLB_AU64_AU57_Diesel,Motor_MLB_BY_Otto,Motor_MLB_C7_PHEV,Motor_MLB_D4_C7_Hybrid,Motor_MLB_D4_C7_Otto
 SG_ ESP_HDC_Standby : 36|1@1+ (1,0) [0|1] "" Vector__XXX
 SG_ ESP_HBA_aktiv : 37|1@1+ (1,0) [0|1] "" Vector__XXX
 SG_ ESP_Prefill_ausgeloest : 38|1@1+ (1,0) [0|1] "" Vector__XXX
 SG_ ESP_Rueckwaertsfahrt_erkannt : 39|1@1+ (1,0) [0|1] ""  Motor_MLB_AU64_AU57_Diesel,Motor_MLB_BY_Otto,Motor_MLB_C7_PHEV,Motor_MLB_D4_C7_Hybrid,Motor_MLB_D4_C7_Otto
 SG_ ESP_Status_Anfahrhilfe : 40|1@1+ (1,0) [0|1] ""  Motor_MLB_AU64_AU57_Diesel,Motor_MLB_C7_PHEV,Motor_MLB_D4_C7_Hybrid,Motor_MLB_D4_C7_Otto
 SG_ ESP_HDC_aktiv : 41|1@1+ (1,0) [0|1] "" Vector__XXX
 SG_ ESP_StartStopp_Info : 42|2@1+ (1,0) [0|3] ""  Motor_MLB_AU64_AU57_Diesel,Motor_MLB_BY_Otto,Motor_MLB_C7_PHEV,Motor_MLB_D4_C7_Hybrid,Motor_MLB_D4_C7_Otto
 SG_ ESP_Eingr_HL : 44|1@1+ (1,0) [0|1] "" Vector__XXX
 SG_ ESP_Eingr_HR : 45|1@1+ (1,0) [0|1] "" Vector__XXX
 SG_ ESP_Eingr_VL : 46|1@1+ (1,0) [0|1] "" Vector__XXX
 SG_ ESP_Eingr_VR : 47|1@1+ (1,0) [0|1] "" Vector__XXX
 SG_ ESP_BKV_Unterdruck : 48|8@1+ (4,0) [4|1012] "Unit_MilliBar"  Motor_MLB_AU64_AU57_Diesel,Motor_MLB_BY_Otto,Motor_MLB_C7_PHEV,Motor_MLB_D4_C7_Hybrid,Motor_MLB_D4_C7_Otto
 SG_ ESP_Autohold_aktiv : 56|1@1+ (1,0) [0|1] ""  EPB_MLB,Getriebe_AL551_951_D4_C7,Getriebe_AL551_Hybrid_D4_C7,Getriebe_DL382_MLB,Getriebe_DL501_MLB,Getriebe_VL381_MLB,Motor_MLB_AU64_AU57_Diesel,Motor_MLB_BY_Otto,Motor_MLB_C7_PHEV,Motor_MLB_D4_C7_Hybrid,Motor_MLB_D4_C7_Otto
 SG_ ESP_FStatus_Anfahrhilfe : 57|1@1+ (1,0) [0|1] "" Vector__XXX
 SG_ ESP_Verz_EPB_aktiv : 58|1@1+ (1,0) [0|1] ""  EPB_MLB,Getriebe_AL551_951_D4_C7,Getriebe_AL551_Hybrid_D4_C7
 SG_ ECD_Bremslicht : 59|1@1+ (1,0) [0|1] ""  Motor_MLB_AU64_AU57_Diesel,Motor_MLB_BY_Otto,Motor_MLB_C7_PHEV,Motor_MLB_D4_C7_Hybrid,Motor_MLB_D4_C7_Otto
 SG_ ESP_Verzoeg_EPB_verf : 60|1@1+ (1,0) [0|1] ""  EPB_MLB
 SG_ ESP_Status_Bremsdruck : 61|1@1+ (1,0) [0|1] ""  EPB_MLB,Getriebe_DL382_MLB,Getriebe_DL501_MLB,Motor_MLB_AU64_AU57_Diesel,Motor_MLB_BY_Otto,Motor_MLB_C7_PHEV,Motor_MLB_D4_C7_Hybrid,Motor_MLB_D4_C7_Otto
 SG_ ESP_Anforderung_EPB : 62|2@1+ (1,0) [0|3] ""  EPB_MLB

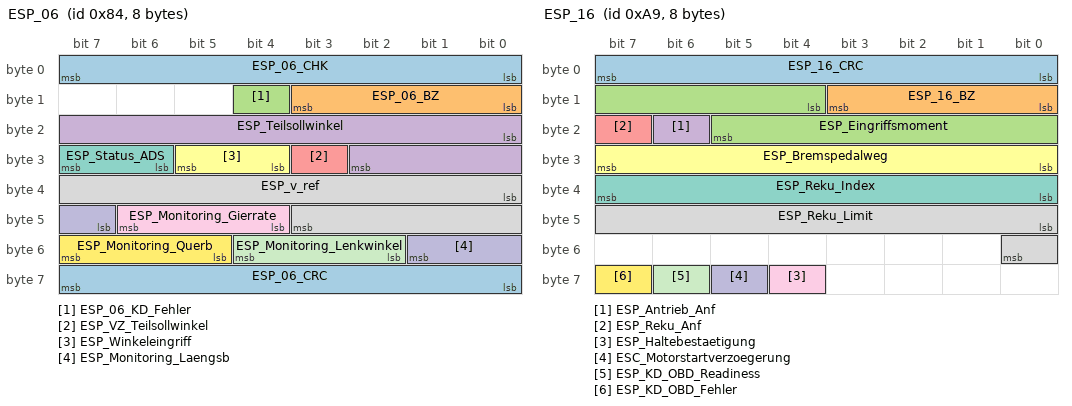
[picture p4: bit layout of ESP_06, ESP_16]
BO_ 132 ESP_06: 8 ESP
 SG_ ESP_06_CHK : 0|8@1+ (1,0) [0|255] ""  SCU
 SG_ ESP_06_BZ : 8|4@1+ (1,0) [0|15] ""  Airbag_D4,SCU
 SG_ ESP_06_KD_Fehler : 12|1@1+ (1,0) [0|1] ""  Gateway
 SG_ ESP_Teilsollwinkel : 16|11@1+ (0.1,0) [0|204.7] "Unit_DegreOfArc"  SCU
 SG_ ESP_VZ_Teilsollwinkel : 27|1@1+ (1,0) [0|1] ""  SCU
 SG_ ESP_Winkeleingriff : 28|2@1+ (1,0) [0|3] ""  SCU
 SG_ ESP_Status_ADS : 30|2@1+ (1,0) [0|3] ""  SCU
 SG_ ESP_v_ref : 32|12@1+ (0.125,0) [0|511.5] "Unit_KiloMeterPerHour"  Airbag_D4
 SG_ ESP_Monitoring_Gierrate : 44|3@1+ (1,0) [0|7] "" Vector__XXX
 SG_ ESP_Monitoring_Laengsb : 47|3@1+ (1,0) [0|7] "" Vector__XXX
 SG_ ESP_Monitoring_Lenkwinkel : 50|3@1+ (1,0) [0|7] "" Vector__XXX
 SG_ ESP_Monitoring_Querb : 53|3@1+ (1,0) [0|7] "" Vector__XXX
 SG_ ESP_06_CRC : 56|8@1+ (1,0) [0|255] ""  Airbag_D4,SCU

BO_ 914 ESP_07_FR: 8 Gateway
 SG_ ESP_07_CHK : 0|8@1+ (1,0) [0|255] ""  Airbag_D4,LWS_D4,Motor_MLB_AU64_AU57_Diesel,Motor_MLB_BY_Otto,Motor_MLB_C7_PHEV,Motor_MLB_D4_C7_Hybrid,Motor_MLB_D4_C7_Otto
 SG_ ESP_07_BZ : 8|4@1+ (1,0) [0|15] ""  Airbag_D4,LWS_D4,Motor_MLB_AU64_AU57_Diesel,Motor_MLB_BY_Otto,Motor_MLB_C7_PHEV,Motor_MLB_D4_C7_Hybrid,Motor_MLB_D4_C7_Otto
 SG_ ESP_ACC_LDE : 12|1@1+ (1,0) [0|1] "" Vector__XXX
 SG_ ESP_Quattro_Antrieb : 13|1@1+ (1,0) [0|1] "" Vector__XXX
 SG_ ESP_Codierung_ADS : 14|2@1+ (1,0) [0|3] ""  LWS_D4,Motor_MLB_AU64_AU57_Diesel,Motor_MLB_BY_Otto,Motor_MLB_C7_PHEV,Motor_MLB_D4_C7_Hybrid,Motor_MLB_D4_C7_Otto
 SG_ ESP_RTA_HL : 16|8@1+ (0.048828125,-6.20117) [-6.20117|6.152345625] "Unit_PerCent" Vector__XXX
 SG_ ESP_RTA_HR : 24|8@1+ (0.048828125,-6.20117) [-6.20117|6.152345625] "Unit_PerCent" Vector__XXX
 SG_ ESP_RTA_VR : 32|8@1+ (0.048828125,-6.20117) [-6.20117|6.152345625] "Unit_PerCent" Vector__XXX
 SG_ OBD_Fehler_Radsensor_HL : 40|4@1+ (1,0) [0|15] ""  Motor_MLB_AU64_AU57_Diesel,Motor_MLB_BY_Otto,Motor_MLB_C7_PHEV,Motor_MLB_D4_C7_Hybrid,Motor_MLB_D4_C7_Otto
 SG_ OBD_Fehler_Radsensor_HR : 44|4@1+ (1,0) [0|15] ""  Motor_MLB_AU64_AU57_Diesel,Motor_MLB_BY_Otto,Motor_MLB_C7_PHEV,Motor_MLB_D4_C7_Hybrid,Motor_MLB_D4_C7_Otto
 SG_ OBD_Fehler_Radsensor_VL : 48|4@1+ (1,0) [0|15] ""  Motor_MLB_AU64_AU57_Diesel,Motor_MLB_BY_Otto,Motor_MLB_C7_PHEV,Motor_MLB_D4_C7_Hybrid,Motor_MLB_D4_C7_Otto
 SG_ OBD_Fehler_Radsensor_VR : 52|4@1+ (1,0) [0|15] ""  Motor_MLB_AU64_AU57_Diesel,Motor_MLB_BY_Otto,Motor_MLB_C7_PHEV,Motor_MLB_D4_C7_Hybrid,Motor_MLB_D4_C7_Otto
 SG_ ESP_Qualifizierung_Antriebsart : 56|1@1+ (1,0) [0|1] "" Vector__XXX
 SG_ ESP_Offroad_Modus : 57|1@1+ (1,0) [0|1] "" Vector__XXX
 SG_ ESP_MKB_ausloesbar : 58|1@1+ (1,0) [0|1] ""  Airbag_D4
 SG_ ESP_Stat_FallBack_eBKV : 59|1@1+ (1,0) [0|1] "" Vector__XXX
 SG_ ESP_CM_Variante : 60|1@1+ (1,0) [0|1] "" Vector__XXX
 SG_ ESP_OBD_Status : 61|1@1+ (1,0) [0|1] ""  Motor_MLB_C7_PHEV,Motor_MLB_D4_C7_Hybrid
 SG_ ESP_Rollenmodus_Deaktivieren : 62|1@1+ (1,0) [0|1] ""  EPB_MLB,Motor_MLB_AU64_AU57_Diesel,Motor_MLB_BY_Otto,Motor_MLB_C7_PHEV,Motor_MLB_D4_C7_Hybrid,Motor_MLB_D4_C7_Otto
 SG_ ESP_nachtr_Stopp_Anf : 63|1@1+ (1,0) [0|1] ""  Motor_MLB_AU64_AU57_Diesel,Motor_MLB_BY_Otto,Motor_MLB_C7_PHEV,Motor_MLB_D4_C7_Hybrid,Motor_MLB_D4_C7_Otto

BO_ 169 ESP_16: 8 Gateway
 SG_ ESP_16_CRC : 0|8@1+ (1,0) [0|255] ""  Motor_MLB_C7_PHEV,Motor_MLB_D4_C7_Hybrid
 SG_ ESP_16_BZ : 8|4@1+ (1,0) [0|15] ""  Motor_MLB_C7_PHEV,Motor_MLB_D4_C7_Hybrid
 SG_ ESP_Eingriffsmoment : 12|10@1+ (1,-509) [-509|509] ""  Motor_MLB_C7_PHEV,Motor_MLB_D4_C7_Hybrid
 SG_ ESP_Antrieb_Anf : 22|1@1+ (1,0) [0|1] "" Vector__XXX
 SG_ ESP_Reku_Anf : 23|1@1+ (1,0) [0|1] "" Vector__XXX
 SG_ ESP_Bremspedalweg : 24|8@1+ (0.4,-0.4) [0|100] "Unit_PerCent" Vector__XXX
 SG_ ESP_Reku_Index : 32|8@1+ (1,0) [0|255] ""  Motor_MLB_C7_PHEV,Motor_MLB_D4_C7_Hybrid
 SG_ ESP_Reku_Limit : 40|9@1+ (1,-509) [-509|0] "Unit_NewtoMeter" Vector__XXX
 SG_ ESP_Haltebestaetigung : 60|1@1+ (1,0) [0|1] ""  Motor_MLB_AU64_AU57_Diesel,Motor_MLB_BY_Otto,Motor_MLB_C7_PHEV,Motor_MLB_D4_C7_Hybrid,Motor_MLB_D4_C7_Otto
 SG_ ESC_Motorstartverzoegerung : 61|1@1+ (1,0) [0|1] ""  Motor_MLB_AU64_AU57_Diesel,Motor_MLB_BY_Otto,Motor_MLB_C7_PHEV,Motor_MLB_D4_C7_Hybrid,Motor_MLB_D4_C7_Otto
 SG_ ESP_KD_OBD_Readiness : 62|1@1+ (1,0) [0|1] ""  Motor_MLB_C7_PHEV,Motor_MLB_D4_C7_Hybrid
 SG_ ESP_KD_OBD_Fehler : 63|1@1+ (1,0) [0|1] ""  Motor_MLB_C7_PHEV,Motor_MLB_D4_C7_Hybrid

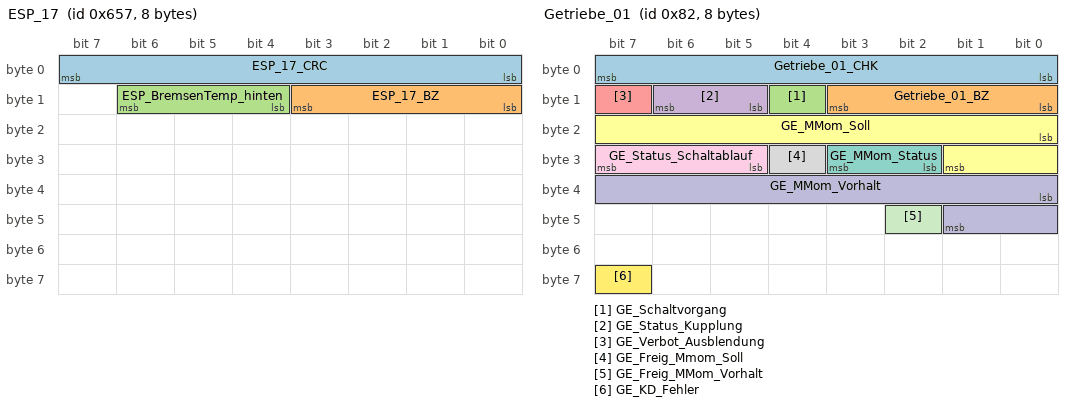
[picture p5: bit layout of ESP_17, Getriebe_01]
BO_ 1623 ESP_17: 8 ESP
 SG_ ESP_17_CRC : 0|8@1+ (1,0) [0|255] ""  EPB_MLB
 SG_ ESP_17_BZ : 8|4@1+ (1,0) [0|15] ""  EPB_MLB
 SG_ ESP_BremsenTemp_hinten : 12|3@1+ (1,0) [0|7] ""  EPB_MLB

BO_ 924 Gateway_05: 8 Gateway
 SG_ BCM1_02_alt : 0|1@1+ (1,0) [0|1] ""  Motor_MLB_AU64_AU57_Diesel,Motor_MLB_BY_Otto,Motor_MLB_C7_PHEV,Motor_MLB_D4_C7_Hybrid,Motor_MLB_D4_C7_Otto
 SG_ Wischer_01_alt : 1|1@1+ (1,0) [0|1] ""  Motor_MLB_AU64_AU57_Diesel,Motor_MLB_BY_Otto,Motor_MLB_C7_PHEV,Motor_MLB_D4_C7_Hybrid,Motor_MLB_D4_C7_Otto
 SG_ Klima_02_alt : 2|1@1+ (1,0) [0|1] ""  Motor_MLB_BY_Otto,Motor_MLB_C7_PHEV,Motor_MLB_D4_C7_Hybrid,Motor_MLB_D4_C7_Otto
 SG_ BCM1_01_alt : 3|1@1+ (1,0) [0|1] ""  EPB_MLB,Motor_MLB_AU64_AU57_Diesel,Motor_MLB_BY_Otto,Motor_MLB_C7_PHEV,Motor_MLB_D4_C7_Hybrid,Motor_MLB_D4_C7_Otto
 SG_ ESP_07_alt : 4|1@1+ (1,0) [0|1] ""  Airbag_D4
 SG_ TSG_BT_1_alt : 5|1@1+ (1,0) [0|1] ""  Motor_MLB_AU64_AU57_Diesel,Motor_MLB_BY_Otto,Motor_MLB_C7_PHEV,Motor_MLB_D4_C7_Hybrid,Motor_MLB_D4_C7_Otto
 SG_ TSG_HL_1_alt : 6|1@1+ (1,0) [0|1] ""  Motor_MLB_AU64_AU57_Diesel,Motor_MLB_BY_Otto,Motor_MLB_C7_PHEV,Motor_MLB_D4_C7_Hybrid,Motor_MLB_D4_C7_Otto
 SG_ TSG_HR_1_alt : 7|1@1+ (1,0) [0|1] ""  Motor_MLB_AU64_AU57_Diesel,Motor_MLB_BY_Otto,Motor_MLB_C7_PHEV,Motor_MLB_D4_C7_Hybrid,Motor_MLB_D4_C7_Otto
 SG_ Motor_02_alt : 8|1@1+ (1,0) [0|1] "" Vector__XXX
 SG_ Klima_Sensor_02_alt : 9|1@1+ (1,0) [0|1] ""  LEH_Hybrid,Motor_MLB_AU64_AU57_Diesel,Motor_MLB_BY_Otto,Motor_MLB_C7_PHEV,Motor_MLB_D4_C7_Hybrid,Motor_MLB_D4_C7_Otto
 SG_ TSG_FT_1_alt : 10|1@1+ (1,0) [0|1] ""  EPB_MLB,Getriebe_AL551_951_D4_C7,Getriebe_AL551_Hybrid_D4_C7,Motor_MLB_AU64_AU57_Diesel,Motor_MLB_BY_Otto,Motor_MLB_C7_PHEV,Motor_MLB_D4_C7_Hybrid,Motor_MLB_D4_C7_Otto
 SG_ Motor_05_alt : 11|1@1+ (1,0) [0|1] "" Vector__XXX
 SG_ QSP_01_alt : 12|1@1+ (1,0) [0|1] ""  Motor_MLB_AU64_AU57_Diesel,Motor_MLB_BY_Otto,Motor_MLB_C7_PHEV,Motor_MLB_D4_C7_Hybrid,Motor_MLB_D4_C7_Otto
 SG_ Parkhilfe_01_alt : 13|1@1+ (1,0) [0|1] ""  Motor_MLB_AU64_AU57_Diesel,Motor_MLB_BY_Otto,Motor_MLB_C7_PHEV,Motor_MLB_D4_C7_Hybrid,Motor_MLB_D4_C7_Otto
 SG_ Fahrwerk_02_alt : 14|1@1+ (1,0) [0|1] "" Vector__XXX
 SG_ GW_05_va_27 : 15|1@1+ (1,0) [0|1] "" Vector__XXX
 SG_ BCM1_MH_WIV_Schalter : 16|1@1+ (1,0) [0|1] ""  Motor_MLB_AU64_AU57_Diesel,Motor_MLB_BY_Otto,Motor_MLB_C7_PHEV,Motor_MLB_D4_C7_Hybrid,Motor_MLB_D4_C7_Otto
 SG_ Wischer_vorne_aktiv : 17|1@1+ (1,0) [0|1] ""  Motor_MLB_AU64_AU57_Diesel,Motor_MLB_BY_Otto,Motor_MLB_C7_PHEV,Motor_MLB_D4_C7_Hybrid,Motor_MLB_D4_C7_Otto
 SG_ BCM1_Rueckfahrlicht_Schalter : 18|1@1+ (1,0) [0|1] ""  EPB_MLB,Motor_MLB_AU64_AU57_Diesel,Motor_MLB_BY_Otto,Motor_MLB_C7_PHEV,Motor_MLB_D4_C7_Hybrid,Motor_MLB_D4_C7_Otto
 SG_ MO_Status_Normalbetrieb_01 : 19|1@1+ (1,0) [0|1] "" Vector__XXX
 SG_ KL_Zuheizer_Freigabe : 20|1@1+ (1,0) [0|1] "" Vector__XXX
 SG_ BCM1_Vorwaertsgang_eingelegt : 21|1@1+ (1,0) [0|1] ""  EPB_MLB
 SG_ ESP_Codierung_ADS : 22|2@1+ (1,0) [0|3] ""  Airbag_D4
 SG_ QSP_StartStopp_Info : 24|2@1+ (1,0) [0|3] ""  Motor_MLB_AU64_AU57_Diesel,Motor_MLB_BY_Otto,Motor_MLB_C7_PHEV,Motor_MLB_D4_C7_Hybrid,Motor_MLB_D4_C7_Otto
 SG_ FA_StartStopp_Info : 26|2@1+ (1,0) [0|3] "" Vector__XXX
 SG_ PH_StartStopp_Info : 28|2@1+ (1,0) [0|3] ""  Motor_MLB_AU64_AU57_Diesel,Motor_MLB_BY_Otto,Motor_MLB_C7_PHEV,Motor_MLB_D4_C7_Hybrid,Motor_MLB_D4_C7_Otto
 SG_ KL_Beschlagsgefahr : 30|1@1+ (1,0) [0|1] "" Vector__XXX
 SG_ BCM1_GLW_Fernlicht_Anf : 31|1@1+ (1,0) [0|1] "" Vector__XXX
 SG_ BCM1_RFahrlicht_Fzg_Anf : 32|1@1+ (1,0) [0|1] "" Vector__XXX
 SG_ FT_Tuer_geoeffnet : 33|1@1+ (1,0) [0|1] ""  EPB_MLB,Getriebe_AL551_951_D4_C7,Getriebe_AL551_Hybrid_D4_C7,Motor_MLB_AU64_AU57_Diesel,Motor_MLB_BY_Otto,Motor_MLB_C7_PHEV,Motor_MLB_D4_C7_Hybrid,Motor_MLB_D4_C7_Otto
 SG_ MO_Handshake_STH : 34|1@1+ (1,0) [0|1] "" Vector__XXX
 SG_ FT_Sperrklinke : 35|1@1+ (1,0) [0|1] ""  EPB_MLB,Motor_MLB_AU64_AU57_Diesel,Motor_MLB_BY_Otto,Motor_MLB_C7_PHEV,Motor_MLB_D4_C7_Hybrid,Motor_MLB_D4_C7_Otto
 SG_ BCM1_OBD_FStatus_ATemp : 36|4@1+ (1,0) [0|15] ""  Airbag_D4,Motor_MLB_AU64_AU57_Diesel,Motor_MLB_BY_Otto,Motor_MLB_C7_PHEV,Motor_MLB_D4_C7_Hybrid,Motor_MLB_D4_C7_Otto
 SG_ BCM1_Aussen_Temp_ungef : 40|8@1+ (0.5,-50) [-50|76] "Unit_DegreCelsi"  Airbag_D4,LEH_Hybrid,Motor_MLB_AU64_AU57_Diesel,Motor_MLB_BY_Otto,Motor_MLB_C7_PHEV,Motor_MLB_D4_C7_Hybrid,Motor_MLB_D4_C7_Otto
 SG_ BCM1_Oeldruck_Schalter : 48|1@1+ (1,0) [0|1] "" Vector__XXX
 SG_ BCM1_Oeldruck_Schalter_2 : 49|1@1+ (1,0) [0|1] "" Vector__XXX
 SG_ BT_Tuer_geoeffnet : 50|1@1+ (1,0) [0|1] ""  Motor_MLB_AU64_AU57_Diesel,Motor_MLB_BY_Otto,Motor_MLB_C7_PHEV,Motor_MLB_D4_C7_Hybrid,Motor_MLB_D4_C7_Otto
 SG_ HL_Tuer_geoeffnet : 51|1@1+ (1,0) [0|1] ""  Motor_MLB_AU64_AU57_Diesel,Motor_MLB_BY_Otto,Motor_MLB_C7_PHEV,Motor_MLB_D4_C7_Hybrid,Motor_MLB_D4_C7_Otto
 SG_ HR_Tuer_geoeffnet : 52|1@1+ (1,0) [0|1] ""  Motor_MLB_AU64_AU57_Diesel,Motor_MLB_BY_Otto,Motor_MLB_C7_PHEV,Motor_MLB_D4_C7_Hybrid,Motor_MLB_D4_C7_Otto
 SG_ BCM1_Adaptive_Lichtvert_Anf : 53|1@1+ (1,0) [0|1] "" Vector__XXX
 SG_ BCM1_Gleitende_Leuchtw_Anf : 54|1@1+ (1,0) [0|1] "" Vector__XXX
 SG_ BCM1_Schalter_StartStopp : 55|1@1+ (1,0) [0|1] ""  Getriebe_AL551_951_D4_C7,Getriebe_AL551_Hybrid_D4_C7,Getriebe_DL382_MLB,Getriebe_DL501_MLB,Getriebe_VL381_MLB,Motor_MLB_AU64_AU57_Diesel,Motor_MLB_BY_Otto,Motor_MLB_C7_PHEV,Motor_MLB_D4_C7_Hybrid,Motor_MLB_D4_C7_Otto
 SG_ ESP_Offroad_Modus : 56|1@1+ (1,0) [0|1] "" Vector__XXX
 SG_ MO_Freig_Reku : 57|2@1+ (1,0) [0|3] "" Vector__XXX
 SG_ KL_HSH_ein_Soll : 59|1@1+ (1,0) [0|1] ""  Motor_MLB_BY_Otto,Motor_MLB_C7_PHEV,Motor_MLB_D4_C7_Hybrid,Motor_MLB_D4_C7_Otto
 SG_ FT_Tuerkontakt_Rohsignal : 60|1@1+ (1,0) [0|1] ""  EPB_MLB
 SG_ FT_TD_Taste : 61|1@1+ (1,0) [0|1] ""  Motor_MLB_C7_PHEV
 SG_ FT_TD_Taste_Fehler : 62|1@1+ (1,0) [0|1] ""  Motor_MLB_C7_PHEV
 SG_ PH_nachtr_Stopp_Anf : 63|1@1+ (1,0) [0|1] ""  Motor_MLB_AU64_AU57_Diesel,Motor_MLB_BY_Otto,Motor_MLB_C7_PHEV,Motor_MLB_D4_C7_Hybrid,Motor_MLB_D4_C7_Otto

BO_ 1604 Gateway_11: 8 Gateway
 SG_ SMLS_01_alt : 0|1@1+ (1,0) [0|1] ""  Motor_MLB_AU64_AU57_Diesel,Motor_MLB_BY_Otto,Motor_MLB_C7_PHEV,Motor_MLB_D4_C7_Hybrid,Motor_MLB_D4_C7_Otto
 SG_ HUD_01_alt : 1|1@1+ (1,0) [0|1] "" Vector__XXX
 SG_ BCM1_01_alt : 2|1@1+ (1,0) [0|1] "" Vector__XXX
 SG_ BCM1_02_alt : 3|1@1+ (1,0) [0|1] ""  Motor_MLB_AU64_AU57_Diesel,Motor_MLB_BY_Otto,Motor_MLB_C7_PHEV,Motor_MLB_D4_C7_Hybrid,Motor_MLB_D4_C7_Otto
 SG_ BCM2_02_alt : 4|1@1+ (1,0) [0|1] ""  Getriebe_VL381_MLB
 SG_ HYB_Anf_E_Mode_alt : 5|1@1+ (1,0) [0|1] ""  Motor_MLB_C7_PHEV,Motor_MLB_D4_C7_Hybrid
 SG_ BCM1_04_alt : 6|1@1+ (1,0) [0|1] "" Vector__XXX
 SG_ ESP_04_alt : 7|1@1+ (1,0) [0|1] "" Vector__XXX
 SG_ Kessy_01_alt : 8|1@1+ (1,0) [0|1] "" Vector__XXX
 SG_ Lift_01_alt : 9|1@1+ (1,0) [0|1] "" Vector__XXX
 SG_ GW_11_va_22 : 10|1@1+ (1,0) [0|1] "" Vector__XXX
 SG_ GW_11_va_23 : 11|1@1+ (1,0) [0|1] "" Vector__XXX
 SG_ GW_11_va_24 : 12|1@1+ (1,0) [0|1] "" Vector__XXX
 SG_ GW_11_va_25 : 13|1@1+ (1,0) [0|1] "" Vector__XXX
 SG_ GW_11_va_26 : 14|1@1+ (1,0) [0|1] "" Vector__XXX
 SG_ GW_11_va_27 : 15|1@1+ (1,0) [0|1] "" Vector__XXX
 SG_ BH_Blinker_li : 16|1@1+ (1,0) [0|1] ""  Motor_MLB_AU64_AU57_Diesel,Motor_MLB_BY_Otto,Motor_MLB_C7_PHEV,Motor_MLB_D4_C7_Hybrid,Motor_MLB_D4_C7_Otto
 SG_ BH_Blinker_re : 17|1@1+ (1,0) [0|1] ""  Motor_MLB_AU64_AU57_Diesel,Motor_MLB_BY_Otto,Motor_MLB_C7_PHEV,Motor_MLB_D4_C7_Hybrid,Motor_MLB_D4_C7_Otto
 SG_ BM_Autobahn : 18|1@1+ (1,0) [0|1] "" Vector__XXX
 SG_ BH_Fernlicht : 19|1@1+ (1,0) [0|1] "" Vector__XXX
 SG_ BH_Lichthupe : 20|1@1+ (1,0) [0|1] "" Vector__XXX
 SG_ BCM1_MH_Schalter : 21|1@1+ (1,0) [0|1] ""  Motor_MLB_AU64_AU57_Diesel,Motor_MLB_BY_Otto,Motor_MLB_C7_PHEV,Motor_MLB_D4_C7_Hybrid,Motor_MLB_D4_C7_Otto
 SG_ HYB_Anf_E_Mode : 22|1@1+ (1,0) [0|1] ""  Motor_MLB_C7_PHEV,Motor_MLB_D4_C7_Hybrid
 SG_ HUD_NV_in_Anzeige : 23|1@1+ (1,0) [0|1] "" Vector__XXX
 SG_ BCM1_Touristen_Licht_Anf : 24|1@1+ (1,0) [0|1] "" Vector__XXX
 SG_ LV_Abblendlicht_li_def : 25|1@1+ (1,0) [0|1] "" Vector__XXX
 SG_ LV_Abblendlicht_re_def : 26|1@1+ (1,0) [0|1] "" Vector__XXX
 SG_ LV_Abblendlicht_Anzeige : 27|1@1+ (1,0) [0|1] "" Vector__XXX
 SG_ LV_AFL_aktiv_Anzeige : 28|1@1+ (1,0) [0|1] "" Vector__XXX
 SG_ BCM1_Licht_Dunkelheit_aktiv : 29|1@1+ (1,0) [0|1] "" Vector__XXX
 SG_ LV_Nebelschlusslicht_Anzeige : 30|1@1+ (1,0) [0|1] "" Vector__XXX
 SG_ BCM1_Linksverkehr : 31|1@1+ (1,0) [0|1] "" Vector__XXX
 SG_ BCM2_P_verriegelt : 32|1@1+ (1,0) [0|1] ""  Getriebe_VL381_MLB
 SG_ BCM1_LDS_Stellung : 33|3@1+ (1,0) [0|7] "" Vector__XXX
 SG_ BCM1_Allwetterlicht_Anf : 36|1@1+ (1,0) [0|1] "" Vector__XXX
 SG_ HUD_Anzeigefehler_NV : 37|1@1+ (1,0) [0|1] "" Vector__XXX
 SG_ ESP_Diagnose : 38|1@1+ (1,0) [0|1] ""  SCU
 SG_ BCM1_SRA_aktiv : 39|1@1+ (1,0) [0|1] "" Vector__XXX
 SG_ FFB_Auf_Taste : 40|1@1+ (1,0) [0|1] "" Vector__XXX
 SG_ FFB_CarFinder : 41|1@1+ (1,0) [0|1] "" Vector__XXX
 SG_ ZV_verriegelt_extern_ist : 42|1@1+ (1,0) [0|1] "" Vector__XXX
 SG_ BCM_Tankwunsch : 43|2@1+ (1,0) [0|3] "" Vector__XXX
 SG_ ZV_Tankklappe_offen : 45|1@1+ (1,0) [0|1] "" Vector__XXX

BO_ 130 Getriebe_01: 8 Getriebe_AL551_951_D4_C7
 SG_ Getriebe_01_CHK : 0|8@1+ (1,0) [0|255] ""  Gateway,Motor_MLB_AU64_AU57_Diesel,Motor_MLB_BY_Otto,Motor_MLB_C7_PHEV,Motor_MLB_D4_C7_Hybrid,Motor_MLB_D4_C7_Otto
 SG_ Getriebe_01_BZ : 8|4@1+ (1,0) [0|15] ""  Gateway,Motor_MLB_AU64_AU57_Diesel,Motor_MLB_BY_Otto,Motor_MLB_C7_PHEV,Motor_MLB_D4_C7_Hybrid,Motor_MLB_D4_C7_Otto
 SG_ GE_Schaltvorgang : 12|1@1+ (1,0) [0|1] ""  Gateway,Motor_MLB_AU64_AU57_Diesel,Motor_MLB_BY_Otto,Motor_MLB_C7_PHEV,Motor_MLB_D4_C7_Hybrid,Motor_MLB_D4_C7_Otto
 SG_ GE_Status_Kupplung : 13|2@1+ (1,0) [0|3] ""  Gateway,Motor_MLB_AU64_AU57_Diesel,Motor_MLB_BY_Otto,Motor_MLB_C7_PHEV,Motor_MLB_D4_C7_Hybrid,Motor_MLB_D4_C7_Otto
 SG_ GE_Verbot_Ausblendung : 15|1@1+ (1,0) [0|1] ""  Gateway,Motor_MLB_AU64_AU57_Diesel,Motor_MLB_BY_Otto,Motor_MLB_C7_PHEV,Motor_MLB_D4_C7_Hybrid,Motor_MLB_D4_C7_Otto
 SG_ GE_MMom_Soll : 16|10@1+ (1,0) [0|1021] ""  Gateway,Motor_MLB_AU64_AU57_Diesel,Motor_MLB_BY_Otto,Motor_MLB_C7_PHEV,Motor_MLB_D4_C7_Hybrid,Motor_MLB_D4_C7_Otto
 SG_ GE_MMom_Status : 26|2@1+ (1,0) [0|3] ""  Gateway,Motor_MLB_AU64_AU57_Diesel,Motor_MLB_BY_Otto,Motor_MLB_C7_PHEV,Motor_MLB_D4_C7_Hybrid,Motor_MLB_D4_C7_Otto
 SG_ GE_Freig_Mmom_Soll : 28|1@1+ (1,0) [0|1] ""  Gateway
 SG_ GE_Status_Schaltablauf : 29|3@1+ (1,0) [0|7] ""  Gateway
 SG_ GE_MMom_Vorhalt : 32|10@1+ (1,0) [0|1021] ""  Gateway,Motor_MLB_AU64_AU57_Diesel,Motor_MLB_BY_Otto,Motor_MLB_C7_PHEV,Motor_MLB_D4_C7_Hybrid,Motor_MLB_D4_C7_Otto
 SG_ GE_Freig_MMom_Vorhalt : 42|1@1+ (1,0) [0|1] ""  Gateway,Motor_MLB_AU64_AU57_Diesel,Motor_MLB_BY_Otto,Motor_MLB_C7_PHEV,Motor_MLB_D4_C7_Hybrid,Motor_MLB_D4_C7_Otto
 SG_ GE_KD_Fehler : 63|1@1+ (1,0) [0|1] ""  Gateway

BO_TX_BU_ 130 : Getriebe_AL551_951_D4_C7,Getriebe_AL551_Hybrid_D4_C7,Getriebe_DL382_MLB,Getriebe_DL501_MLB,Getriebe_VL381_MLB;
CM_ BO_ 901 "Die Botschaft wird bei aktiver Funktion (Betaetigung Charisma-Schalter) sowie bei Kl.15 EIN 5mal gesendet (kein Abmelden)";
CM_ SG_ 901 CHA_01_CHK "Berechnung siehe Lastenheft 'Kommunikationsabsicherung für FlexRay und CAN'
Endwerte siehe 'Kommunikationsabsicherung für FlexRay und CAN / Anhang C: Tabelle S-PDU Kennungen'";
CM_ SG_ 901 CHA_01_BZ "Botschaftszaehler, wird aktuell noch nicht vom BCM1 bedient
(Vorhalt, falls Botschaft zyklisch wird)
";
CM_ SG_ 901 CHA_Systemstatus "Systemstatus Charisma Koordinator
";
CM_ SG_ 901 CHA_Fahrer_Umschaltung "Die manuelle Umschaltung durch den Fahrer soll signalisiert werden, um zu automatischen Umschaltungen (z.B. Retries) differenzieren zu können.";
CM_ SG_ 901 CHA_Ziel_FahrPr_MO "Anforderung Ziel-Fahrprogramm Motor";
CM_ SG_ 901 CHA_Ziel_FahrPr_GE "Anforderung Ziel-Fahrprogramm Getriebe";
CM_ SG_ 901 CHA_Ziel_FahrPr_ST "Anforderung Ziel-Fahrprogramm";
CM_ SG_ 901 CHA_Ziel_FahrPr_SCU "Anforderung Ziel-Fahrprogramm SCU";
CM_ SG_ 901 CHA_Ziel_FahrPr_DR "Anforderung Ziel-Fahrprogramm Dämpfer";
CM_ SG_ 901 CHA_Ziel_FahrPr_QS "Anforderung Ziel-Fahrprogramm Quattro Sport";
CM_ SG_ 901 CHA_Ziel_FahrPr_AFS "Anforderung Ziel-Fahrprogramm AFS";
CM_ SG_ 901 CHA_Ziel_FahrPr_RGS "Anforderung Ziel-Fahrprogramm Reversibler Gurtstraffer";
CM_ SG_ 901 CHA_Ziel_FahrPr_EPS "Anforderung Ziel-Fahrprogramm Elekronische Lenkung";
CM_ SG_ 901 CHA_Ziel_FahrPr_ACC "MLB
Anforderung Ziel-Fahrprogramm ACC";
CM_ SG_ 901 CHA_Ziel_FahrPr_SAK "Anforderung Ziel-Fahrprogramm-Soundaktuator

für D4";
CM_ SG_ 918 Daempfer_01_CHK "Berechnung siehe Lastenheft 'Kommunikationsabsicherung für FlexRay und CAN'
Endwerte siehe 'Kommunikationsabsicherung für FlexRay und CAN / Anhang C: Tabelle S-PDU Kennungen'";
CM_ SG_ 918 DR_Systemstatus "Bei Statusänderung wird der Soll-Zustand ausgegeben. Der Status beschreibt einen Parametersatz: Temporäre Änderung der Dämpfereinstellungen werden hier nicht abgebildet. 
";
CM_ SG_ 918 LF_Texte "Signal zur Ansteuerung von Fahrerhinweisen im Kombi";
CM_ SG_ 918 DR_Taster "Ausgabe der Position des Tasters der Dämpferregelung";
CM_ SG_ 918 DR_Gelbe_Warnlampe "Bit wird gesetzt, wenn während des Betriebes ein Fehler erkannt wird.";
CM_ SG_ 918 DR_Daempferreg_Texte "Die Textbits werden verwendet, um im Kombi Texte oder Bilder für die Dämpferregelung darzustellen

0x4 - 0xE tbd.

";
CM_ SG_ 918 DR_Charisma_FahrPr "Aktuelles Fahrprogramm des Charisma-Teilnehmers

Achtung neue Modusnamen (wie im MMI):

0x1 = Komfort = Comfort
0x2 = Dynamik = Auto
0x3 = Sport = Dynamic";
CM_ SG_ 918 DR_Charisma_Status "Charisma Systemstatus des Charisma-Teilnehmers

Wert 0x3 ist nur für Fahrzeuge ab MQB relevant";
CM_ SG_ 918 DR_Charisma_Umschaltung "Erkennung  Umschaltaufforderung des Charisma-Teilnehmers";
CM_ SG_ 918 DR_Fahrzeugart "Für automatische Fahrzeugerkennung zur Absicherung der Einschränkungen

Wird im D4 nicht bedient
Darf im VW526 nicht verwendet werden";
CM_ SG_ 918 LF_Warnung_Prio1 "Signal zur Ansteuerung von Prio1-Warnungen im Kombi";
CM_ SG_ 918 LF_Warnung_Prio2 "Signal zur Ansteuerung von Prio2-Warnungen im Kombi";
CM_ SG_ 918 DR_DynAGL_Warnlampe "Warnlampe für dynamische Aggregate-Lagerung
Darf im VW526 und PAG E2 nicht verwendet werden";
CM_ SG_ 918 DR_Rote_Warnlampe "Bit wird gesetzt, wenn während des Betriebes ein schwerwiegender Fehler erkannt wird.
Darf im VW526 nicht verwendet werden";
CM_ SG_ 918 NI_Status "Status des Niveau Systems LB83x";
CM_ SG_ 918 NR_Niveaufunktion_aktiv "AU57x:
Signal meldet DriveSelect, wann die lift-Funktion aktiv ist damit das Fahrprogramm auf allroad gewechselt werden kann.

MLBevo:
Das Signal wird benötigt um eine gezielte Sonderreaktion bei Verlassen des Liftmodus einzuleiten.";
CM_ SG_ 945 DC_Verbrauch "Energieverbrauch vom DCDC für Versorgung 12V-Bordnetz inkl. seines eigenen Wirkungsgrads (bspw.: HV_Strom*HV_Spannung*t)";
CM_ SG_ 945 DC_Verbrauch_Ueberlauf "Überlauf-Bit für das Signal DC_Verbrauch";
CM_ SG_ 945 DC_HYB_iAktLV "Momentanwert: Strom vom DC/DC-Wandler in das Bordnetz";
CM_ SG_ 945 DC_HYB_iAktReserveLV "Momentanwert: Stromreserve vom DC/DC-Wandler in Richtung 12V-Bordnetz
Im MLBevo nur positiver Bereich genutzt

Tiefsetzen - positiv
Hochsetzen - negativ";
CM_ SG_ 945 DC_HYB_uAktLV "Momentanwert: NV-Bordnetzspannung am DC/DC-Wandler";
CM_ SG_ 945 DC_HYB_LangsRegelung "aktueller Regelmode des DC/DC-Wandlers.
0: normale Regelung
1: langsame Regelung";
CM_ SG_ 945 DC_HYB_Abregelung_Temperatur "Abregelung aufgrund Übertemperatur im Leistungsteil (Hochtemperatur-Abregelung)";
CM_ SG_ 945 DC_HYB_Fehler_RedLeistung "Fehler: eingeschränkte Leistungsfähigkeit des DC/DC-Wandlers aufgrund eines internen Fehlers";
CM_ SG_ 945 DC_HYB_Fehler_intern "Fehler: DC/DC-Wandler ist aufgrund eines internen Hardware-Fehlers abgeschaltet";
CM_ SG_ 945 DC_HYB_Fehler_Spannung "Abschaltung aufgrund Unter-/Überspannung auf der Ein-/Ausgangsseite";
CM_ SG_ 945 DC_TiefsetzBereit "Kennzeichnung, dass der DC/DC-Wandler im Sollmodus Tiefsetzbetrieb ist und auf Spannungsvorgabe wartet. Fehler werden über das Signal DC_HYB_Fehler_intern signalisiert.";
CM_ SG_ 945 DC_HYB_Auslastungsgrad "Momentanwert: Auslastung DC/DC (DFM Signal), entspricht I_akt / I_max
(Vorhalt für MQB)";
CM_ SG_ 1714 DGN_Verlernzaehler "wrap around 254 --> 0";
CM_ SG_ 1714 KBI_Kilometerstand "Fehler wird ausgegeben, falls Kilometerstand nicht restaurierbar
";
CM_ SG_ 1714 UH_Monat "0x0D, 0xF =  Werte ungültig
0x0E = reserviert (nur VW)";
CM_ SG_ 1714 UH_Tag "0x0: reserviert bei VW";
CM_ SG_ 1714 UH_Stunde "0x18 - 0x1F = Werte ungültig";
CM_ SG_ 1714 UH_Minute "0x3C- 0x3f = Werte ungültig";
CM_ SG_ 1714 UH_Sekunde "0x3C- 0x3f = Werte ungültig";
CM_ SG_ 1714 Uhrzeit_01_alt "
";
CM_ SG_ 1520 DI_KL_58d "Dimmwert für Funktionsbeleuchtung(u.a. Displays)
Um den hohen Dynamikbereich ohne sichtbare Sprungänderungen abzudecken, wird das Signal logarithmisch übertragen (Auflösung im unteren Dimmbereich höher). Im Detail gilt das Bauteil-Lastenheft LAH 8D0 900 ";
CM_ SG_ 1520 DI_KL_58s "Dimmwert für Suchbeleuchtung (z.B. Schaltersymbole, etc., nur bei Licht an)
0x7F = Fehlerwert, 0x7E = Init bzw. nicht verfuegbar;  gueltiger Wertebereich 0x0 - 0x64; ungueltiger Wertebereich 0x65 - 0x7D; Audi Sende Mindestabstand 50 ms, Hysterese +/- 3 D";
CM_ SG_ 1520 DI_KL_58st "Dimmwert für Suchbeleuchtung Tasten (immer beleuchtet)
0x7F = Fehlerwert, 0x7E = Init bzw. nicht verfuegbar;  gueltiger Wertebereich 0x0 - 0x64; ungueltiger Wertebereich 0x65 - 0x7D; Audi Sende Mindestabstand 50 ms, Hysterese +/- 3 Digits, Abtastung im E";
CM_ BO_ 1603 "MLB 3Byte";
CM_ SG_ 1603 KBI_Einheit_Datum "Anzeigevariante des Datums";
CM_ SG_ 1603 KBI_Einheit_Druck "Einheit des Druckes";
CM_ SG_ 1603 KBI_Einheit_Streckenanz "Einheit der Streckenanzeige";
CM_ SG_ 1603 KBI_MFA_v_Einheit_02 "Einheit der Geschwindigkeit, die vom Fahrer im Car-Menü gewählt wurde. Veränderliche Grösse, im Gegensatz zur Einheit des Tachokranzes.

Redundant in der Einheiten_01 Botschaft definiert, um Konsistenz zur BAP-Festlegung zu haben.";
CM_ SG_ 1603 KBI_Einheit_Temp "Einheit der Temperatur";
CM_ SG_ 1603 KBI_Einheit_Uhrzeit "Anzeigevariante der Uhrzeit";
CM_ SG_ 1603 KBI_Einheit_Verbrauch "Einheit der Verbrauchs";
CM_ SG_ 1603 KBI_Einheit_Volumen "Einheit des Volumens";
CM_ SG_ 1603 KBI_Einheit_Verbrauch_elektr "Einheit elektrischer Verbrauch";
CM_ SG_ 1603 KBI_Einheit_Sprache "Siehe BAP-Datenfestlegung UnitMaster";
CM_ SG_ 1627 EM_HYB_KD_Fehler "Bei gesetztem Bit ist mindestens ein Kundendienstfehler eingetragen";
CM_ SG_ 260 EPB_01_CHK "Berechnung siehe Lastenheft 'Kommunikationsabsicherung für FlexRay und CAN'
Endwerte siehe 'Kommunikationsabsicherung für FlexRay und CAN / Anhang C: Tabelle S-PDU Kennungen'";
CM_ SG_ 260 EPB_QBit_Laengsbeschleunigung "Mitteilung z.Zt. für ACC, um unter bestimmten Zuständen mitzuteilen, daß Längsbeschleunigung temporär ungültig ist. Bsp.: Selbsttest Längsbeschleunigungssensor.";
CM_ SG_ 260 EPB_BCM2_Motor_Wakeup "EPB setzt dieses Bit, wenn EPB ein Nachwecken des ACAN fordert. Die Wakeup-Ursache des Car-Wakeup wird im NM high von den SG nicht ausgewertet, weswegen die Car-Wakeup-Information in einer konventionellen Applikationsbotschaft zum BCM2 gesendet werden. Da";
CM_ SG_ 260 EPB_Freig_Verzoeg_Anf "Verzögerungsanforderung	";
CM_ SG_ 260 EPB_Verzoeg_Anf "Steuerungsanforderung an andere Systeme (z.B. ESP), um während der Fahrt, durch den Handbremsschalter ausgelöst, zu bremsen (ECD-Funktion)";
CM_ SG_ 260 EPB_Laengsbeschleunigung "Längsbeschleunigungssignal (Sensor im AUDI D4 entfallen)
Achtung misst auch die Erdebeschleuinigung (stehend am Hang Wert !=0)

Entspricht bei kleinen Winkel dem Neigungswinkelsignal (<30%).

";
CM_ SG_ 260 EPB_Pedalweg_Kuppl "Signal entspricht Tastverhältnis des PWM. Gesamtweg Kupplungspedal 10% bis 90%, damit zu erwartende Werte 25 bis 225. 25 bei Kupplungspedal nicht getreten, 225 bei Kupplungspedal voll durchgetreten.
2% Toleranz wird im Wertebereich ermöglicht (8%-92%).
";
CM_ SG_ 260 HMS_Konsistenz_HVLM "Zeigt an, ob die Kommunikation und die Anforderungen plausibel sind.";
CM_ SG_ 260 HMS_Systemstatus "Zeigt den aktuellen Systemstatus des HMS an.";
CM_ SG_ 260 EPB_Anfahrwunsch_erkannt "Nur im Colorado_NF zu verwenden: Die EPB zeigt mit diesem Signal einen erkannten Anfahrwunsch an. Das Signal kann genutzt werden um einem SG, welches ein Spannen über CAN anfordert (z.B. ESP-SG), mitzuteilen, dass ein Anfahrwunsch besteht und die EPB löse";
CM_ SG_ 260 EPB_DAA_Randbed_erf "Die Randbedingungen zum automatischen Öffnen der EPB (Funktion DAA) sind erfüllt und ein Betätigen des Fahrpedals führt zum Öffnen der EPB.";
CM_ SG_ 260 EPB_Fehlerstatus "PAG/VW526: Werte 1 und 2 werden nur bei PAG und VW526 verwendet. Genauere Informationen bitte in den Fachabteilungen erfragen!";
CM_ SG_ 260 EPB_Schalterposition "Spiegelt die Schalterstellung wieder.

0x3 = Schalterfehler ";
CM_ SG_ 260 EPB_Konsistenz_ACC "EPB hat einen Fehler erkannt bzgl. der ACC-Botschaften (Timeout, BZ, CHK, DLC)";
CM_ SG_ 260 EPB_Spannkraft "Erzeugte Spannkraft. Bezieht sich auf die Aktuatoren.

MQB: Spannkraftwerte entsprechen nicht den tatsächlichen Spannkräften. Genauere Informationen bitte in der Fachabteilung erfragen! ";
CM_ SG_ 260 EPB_Status "Gibt den Zustand der EPB-Aktuatoren an.

Nur VW526/PAG E2: Wert 0x3 bedeutet 'unbekannt'

";
CM_ SG_ 781 EPB_Fehlerlampe_Gelb "Fehlerlampe für nicht liegenbleiberreleavante Fehler";
CM_ SG_ 781 EPB_Fehlerlampe_BKL "Die BKL dient als rote Fehlerlampe für die EPB. Sie wird vom EPB-SG aktiv ausgeschaltet.";
CM_ SG_ 781 EPB_Funktionslampe "Bit wird nur gesetzt, wenn volle Spannkraft auf beiden Seiten erreicht. PQ46: Bit wird gesetzt, wenn BKL direkt vom EPB-SG als Funktionslampe angesteuert wird.

Bei Audi: Rote Lampe (rotes P) im Kombiinstrument
";
CM_ SG_ 781 EPB_Texte "EPB-Texte für Kombi
9 bei Audi aktuell nicht bedient.
10 bei Audi hinzugefügt für RSe
";
CM_ SG_ 781 EPB_Akustik "Bit wird gesetzt, wenn bei v > 0 eine Fahreran-forderung schließen vorhanden ist (ECD angefordert). PQ46-Kombi sendet Warnton (600Hz) solange dieses Bit gesetzt ist.
Anzeige eines Warntextes
";
CM_ SG_ 781 EPB_Autoholdlampe "Autoholdlampe im Kombi, grünes P
";
CM_ SG_ 781 EPB_Bremsbelag_Warn "Mindestens ein Bremsbelag an der Hinterachse am Fahrzeug ist unter Minimum";
CM_ SG_ 781 EPB_Fehlermeldungen "Über das Signal werden bestimmteFehlertexte und -lampen im Kombi angefordert.";
CM_ SG_ 256 ESP_01_CHK "Berechnung siehe Lastenheft 'Kommunikationsabsicherung für FlexRay und CAN'
Endwerte siehe 'Kommunikationsabsicherung für FlexRay und CAN / Anhang C: Tabelle S-PDU Kennungen'";
CM_ SG_ 256 ASR_Moment_langsam "Achtung:
Einheitenloser CAN-Wert.
Faktor in MO_Faktor_Momente in Motor_Code_01 beachten!

Langsame reduzierende (ASR) Momentenanforderung an der Motor";
CM_ SG_ 256 ASR_MSR_Moment_schnell "Achtung:
Einheitenloser CAN-Wert.
Faktor in MO_Faktor_Momente in Motor_Code_01 beachten!

Schnelle reduzierende (ASR) oder erhöhende (MSR) Momentanforderung an den Motor, Eingriffsart wird über das Signal 'ASR_MSR_Eingriffsart' qualifiziert";
CM_ SG_ 256 ESP_v_Signal "Geschwindigkeitssignal vom ABS/ASR oder ESP. Mittelwert der angetriebenen Räder.
Bei MSR oder ABS Eingriffen wird die ABS-Referenzgeschwindigkeit für >= 200ms eingespiegelt (Zeit wird mit Aktiv-Flanke der Funktionsbits getriggert)

MQB: Bei Frontantrie";
CM_ SG_ 256 ASR_Tastung_passiv "ASR deaktiviert oder Schwellen geändert (projektabhängig)
Weiterführende Informationen im Lastenheft spezifiziert und in der entsprechenden Fachabteilung zu erfragen.
";
CM_ SG_ 256 ESP_Tastung_passiv "ESP deaktiviert oder Schwellen geändert (projektabhängig)
Weiterführende Informationen im Lastenheft spezifiziert und in der entsprechenden Fachabteilung zu erfragen.";
CM_ SG_ 256 ESP_Systemstatus "Fehler steht für Stillegung ESP mit Fehlereintrag.

MLB: Flag wird bei Unterspannung im Stand bis einmalig 6km/h (AU48x) oder 10 km/h (AU641, AU57x) überschritten nicht gesetzt (Ausblendung Startvorgang)
Im AU64x, AU57x gilt ESP D4 Funktionsanforderung";
CM_ SG_ 256 ASR_Schalteingriff "Wunsch an das Getriebe während einer ASR Regelung

MLB: Es wird nur 0x0 und 0x1 genutzt

";
CM_ SG_ 256 OBD_Schlechtweg "Für Ausblendung der Zündaussetzererkennung im Motorsteuergerät (Otto). Bit wird gesetzt, wenn Rad-Drehbeschleunigung im ESP > Grenzwert ist. Vorteil gegenüber Radgeschwindigkeiten, dass ESP alle 2 ms dynamisch die Rad-Drehbeschleunigung errechnet und dem ";
CM_ SG_ 256 ESP_QBit_v_Signal "Geschwindigkeit wird vom ABS/ASR oder ESP aus Ersatzwerten errechnet, wenn Bit gesetzt ist. Güte des Signals ist verändert.";
CM_ SG_ 256 ABS_Bremsung "Antiblockiersystem, Bit zeigt auch Druckabbau an (z.B. ESP hat zuviel Druck aufgebaut oder ungebremste Regelung auf Bahnübergang)
Weiterführende Informationen im Lastenheft spezifiziert und in der entsprechenden Fachabteilung zu erfragen.";
CM_ SG_ 256 ASR_Anf "MLB: Die Momentenanforderung 'ASR_MSR_Moment_schnell' und 'ASR_Moment_langsam' sind auszuführen
MQB: Die Momentenanforderung 'BR_Eingriffsmoment' ist auszuführen";
CM_ SG_ 256 MSR_Anf "MLB: Die Momentenanforderung 'ASR_MSR_Moment_schnell' ist auszuführen.
MQB: Die Momentenanforderung 'BR_Eingriffsmoment' ist auszuführen";
CM_ SG_ 256 EBV_Eingriff "Elektronische Bremskraftverteilung, aktueller Eingriff (Druckhalten, Druckabbau)

Im MLB: kein ABS / ESP-Eingriff ???";
CM_ SG_ 256 EDS_Eingriff "Elektronische Differentialsperre";
CM_ SG_ 256 ESP_Eingriff "Eingriff des Fahrdynamikreglers";
CM_ SG_ 256 ESP_ASP "MLB: Anhaenger-Stabilisierungs-Programm
MQB: Gespannstabilisierung";
CM_ SG_ 257 ESP_02_CHK "Berechnung siehe Lastenheft 'Kommunikationsabsicherung für FlexRay und CAN'
Endwerte siehe 'Kommunikationsabsicherung für FlexRay und CAN / Anhang C: Tabelle S-PDU Kennungen'";
CM_ SG_ 257 ESP_QBit_Gierrate "QBit der Gierrate. Gesetzt bei Ersatzwert, Init oder Fehler. 
";
CM_ SG_ 257 ESP_QBit_Laengsbeschl "QBit der Längsbeschleunigung. Gesetzt bei Ersatzwert, Init oder Fehler. 
";
CM_ SG_ 257 ESP_QBit_Querb "QBit der Querbeschleunigung. Gesetzt bei Ersatzwert, Init oder Fehler. ";
CM_ SG_ 257 ESP_Stillstandsflag "Bei RB-Projekten wird das Stillstandsflag gesetzt, wenn der absolute Stillstand der Raddrehzahlsensoren erkannt wurde, d.h. kein Zahn bewegt sich mehr. Dieses Bit wird bspw. im MOST für TV-Tuner-Abschaltung Australien verwendet, d.h. leichte Erschütterung";
CM_ SG_ 257 ESP_Querbeschleunigung "Beschleunigungswert in y-Achse

MLB: Gemessener Wert
0xFF = Fehler (wie bereits im Wertebereich spezifizert)
Bei ESP-Abschaltung durch modellgestützte Überwachung wird das Signal weiterhin ausgegeben.
Im AU64x und AU57x erfolgt die Bereitstellung der";
CM_ SG_ 257 ESP_Laengsbeschl "Beschleunigungswert in x-Achse

MLB: Im AU64x und AU57x erfolgt die Bereitstellung der Sensorwerte durch SARA-SG! Im AU64x und AU57x wird bei ESP-Abschaltung durch modellgestützte Überwachung das Signal weiterhin ausgegeben.

MQB: Sensorrohwert Längsb";
CM_ SG_ 257 ESP_Verteil_Wankmom "Anforderung einer Wankmomentenverteilung an CDC (Exklusivnutzung!)

-1...-0,1 = Fahrzeug untersteuernd (Anforderung Dämpfer vorne weich / hinten hart)
0 = Fahrzeug neutral, keine Dämpferansteuerung erforderlich
+0,1...+1 = Fahrzeug übersteuernd: Anfor";
CM_ SG_ 257 ESP_QBit_Anf_Vert_Wank "QBit der Wankmomentenverteilung. Gesetzt bei Ersatzwert, Init oder Fehler.";
CM_ SG_ 257 ESP_Gierrate "Winkelgeschwindigkeit um die z-Achse, ESP_VZ_Gierrate & ESP_QBit_Gierrate beachten !!!

MLB: gemessener Wert
tatsächliche Auflösung Bosch ESP: 0,27 Grad/s

Ab AU64x Auflösung wie die tatsächliche Skalierung 0,01. Im AU64x und AU57x wird bei ESP-Absch";
CM_ SG_ 257 ESP_VZ_Gierrate "Vorzeichen der Gierrate";
CM_ SG_ 257 ESP_Notbremsanzeige "ABS/ASR oder ESP hat Notbremssituation erkannt.
Weiterführende Informationen im Lastenheft spezifiziert und in der entsprechenden Fachabteilung zu erfragen.

";
CM_ SG_ 257 ESP_SpannungsAnf "Die Rekuperation kann mit der Anforderung einer höheren Spannung eingeschränkt werden.";
CM_ SG_ 257 ESP_PLA_Abbruch "Wenn der Bremseingriff abgebrochen wurde, wird in diesem Signal der Grund des Abbruchs dargestellt.
Dies ist nur gültig, wenn der Status ESP_Status_ESP_PLA = '0xA' ist.";
CM_ SG_ 257 ESP_Status_ESP_PLA "Zustand der Statusmaschine der Bremse für die korrespondierende Statusmaschine in dem PLA-SG";
CM_ SG_ 259 ESP_03_CHK "Berechnung siehe Lastenheft 'Kommunikationsabsicherung für FlexRay und CAN'
Endwerte siehe 'Kommunikationsabsicherung für FlexRay und CAN / Anhang C: Tabelle S-PDU Kennungen'";
CM_ SG_ 259 ESP_VL_FR "Fahrtrichtungserkennung Rad Vorne Links
";
CM_ SG_ 259 ESP_VR_FR "Fahrtrichtungserkennung Rad Vorne Rechts

";
CM_ SG_ 259 ESP_HL_FR "Fahrtrichtungserkennung Rad Hinten Links
";
CM_ SG_ 259 ESP_HR_FR "Fahrtrichtungserkennung Rad Hinten Rechts
";
CM_ SG_ 259 ESP_VL_Radgeschw "Radgeschwindigkeit vorne links";
CM_ SG_ 259 ESP_VR_Radgeschw "Radgeschwindigkeit vorne rechts";
CM_ SG_ 259 ESP_HL_Radgeschw "Radgeschwindigkeit hinten links";
CM_ SG_ 259 ESP_HR_Radgeschw "Radgeschwindigkeit hinten rechts";
CM_ BO_ 776 "im D4 mit 40ms (FR)";
CM_ SG_ 776 ESP_Meldungen "Verwendung/Bedienung ab D4
ESP sendet im Hinweis- /Störungsfall an das Kombi Informationen zum Anzeigen (Text + Akustik)

- die Signalinhalte wurden aus dem Signal ESP_Textanzeigen_02 (Wert 0x10, 0xE, 0x9) extrahiert 
und werden zukünftig über dieses ";
CM_ SG_ 776 ESP_HDC_FktLampe "Funktionslampe Bergabfahrassistent.
(Sender blinkt mit dem Bit 3,3Hz)";
CM_ SG_ 776 ESP_Lampe "Zustand der Fahrdynamikregelungslampe (MLB: ASR und/oder ESP, MQB: nur ESP)

Weiterführende Informationen im Lastenheft spezifiziert und in der entsprechenden Fachabteilung zu erfragen.";
CM_ SG_ 776 ABS_Lampe "Sicherheitswarnlampe

Weiterführende Informationen im Lastenheft spezifiziert und in der entsprechenden Fachabteilung zu erfragen.";
CM_ SG_ 776 BK_Lampe "Sicherheitswarnlampe signalisiert EBV-Ausfall

MLB: 
Blinktakt wird vom Kombi generiert. Separate Bremskontroll-Lampe wird als Sicherheitswarnlampe aufgeprüft.

MQB: wird auch bei HBV-Ausfall verwendet

Weiterführende Informationen im Lastenheft sp";
CM_ SG_ 776 ESP_Akustik "Akustik der Fahrdynamikregelung im Kombiinstrument

Im B8 gilt LAH 8T0.907.B.pdf - Warn-Anzeigekonzept Bremssysteme

Im D4 gilt die Spezifikation Warn-Anzeige-LH D4

Im MQB wird dieses Signal nicht unterstützt!
";
CM_ SG_ 776 ESP_Diagnose "MLB: Nach Diagnoseende wird ein SW-Reset ausgelöst welcher einen Kommunikatiosausfall für max. 150ms verursacht. Dies ist bei SG mit verschärfter Timeoutüberwachung (nicht nach Konzern-LH) zu beachten.

MQB: Weiterführende Informationen im Lastenheft sp";
CM_ SG_ 776 ESP_Textanzeigen_02 "Textanzeigen der Fahrdynamikregelung im Kombiinstrument

Weiterführende Informationen im Lastenheft spezifiziert und in der entsprechenden Fachabteilung zu erfragen.

Nur im VW526 werden die Werte 0x15 und 0x17 für die Verlassenswarnung (1. Anlauf) ge";
CM_ SG_ 776 ESP_Off_Lampe "Bit zur Ansteuerung der separaten ESP-off-Lampe im Kombi (Gesetzesforderung USA)

MLB:
Verwendung/Bedienung ab D4";
CM_ SG_ 776 ESP_m_Raddrehz "Radumdrehungen pro Sekunde sind Eingangsgröße für die Geschwindigkeitsberechnung im Kombi. Aus dieser Raddrehzahl und dem Radumfang wird die Fahrzeuggeschwindigkeit errechnet.

MLB: Exklusiver Empfänger ist das Kombiinstrument!
MQB: Bei Frontantrieb un";
CM_ SG_ 776 ESP_ASR_Lampe "Signal wir nur im B8/Q5 verwendet um den Fehlerzustand des ESPs darzustellen.
In allen nachfolge Projekten werden für diese Funktion die alten Signale verwendet und dieses Signal ist ungültig. 

ESP_ASR_Lampe == 0
kein Stabilisierungseingriff, kein Fe";
CM_ SG_ 776 ESP_Wegimp_VA "Weiterführende Informationen im Lastenheft spezifiziert und in der entsprechenden Fachabteilung zu erfragen.

MLB: Die Wegimpulse Vorderachse sind die gemittelten Werte (reine mathematische Operation: Addition und Division durch zwei, keine Filterung) d";
CM_ SG_ 776 ESP_Fehlerstatus_Wegimp "Weiterführende Informationen im Lastenheft spezifiziert und in der entsprechenden Fachabteilung zu erfragen.

MLB: Fehler wird gesetzt, wenn beide ESP-Drehzahlfühler an der Vorderachse defekt sind.

MQB: Fehler wird gesetzt, wenn beide Raddrehzahlfühl";
CM_ SG_ 776 ESP_Wegimp_Ueberlauf "Der Wegimpulszähler ist pro Zündungslauf mindestens einmal übergelaufen

Weiterführende Informationen im Lastenheft spezifiziert und in der entsprechenden Fachabteilung zu erfragen.";
CM_ SG_ 776 ESP_QBit_Wegimp_VA "Gesetzt bei Ersatzwert, Init oder Fehler.";
CM_ SG_ 776 ESP_Displaywarnungen "Prio1-Warnungen
Automatisch gekoppelt an diese Bremsenwarnung ist ein dreimaliger Warnton, der durch das Kombi selbstständig angesteuert wird, sobald eines der belegten Bits gesetzt ist (nicht VW526!).

Im B8 gilt LAH 8T0.907.B.pdf - Warn-Anzeigekonzep";
CM_ SG_ 776 ESP_HDC_Regelgeschw "Verwendung/Bedienung nur im AU57x Allroad:
HDC-Geschwindigkeit
Dient der Anzeige der HDC-Geschwindigkeit und eines Bergabfahrsymbols im Kombi.
HDC-Standby wird gesetzt sobald der Fahrer den HDC-Taster aktiviert hat.
Bei HDC-Off oder während der Initia";
CM_ SG_ 776 ESP_BKV_Warnung "ESP sendet im Hinweis- /Störungsfall an das Kombi Informationen zum Anzeigen (Text + Akustik)

Im MQB wird dieses Signal nicht unterstützt!
";
CM_ SG_ 776 ESP_Zaehnezahl "Konstanter Wert der Zähnezahl des verwendeten Impulsrades wird ausgegeben, jeder Empfänger der Wegimpulse muss die Zähnezahl einlesen, um eine volle Umdrehung des Rades zu erkennen. 

Weiterführende Informationen im Lastenheft spezifiziert und in der en";
CM_ SG_ 262 ESP_05_CHK "Berechnung siehe Lastenheft 'Kommunikationsabsicherung für FlexRay und CAN'
Endwerte siehe 'Kommunikationsabsicherung für FlexRay und CAN / Anhang C: Tabelle S-PDU Kennungen'";
CM_ SG_ 262 ESP_QBit_Bremsdruck "QBit des Bremsdrucks. Gesetzt bei Ersatzwert, Init oder Fehler.";
CM_ SG_ 262 ESP_QBit_Fahrer_bremst "Gültigkeit der Bremsdruckschwelleninformation des Signals ESP_Fahrer_bremst vom ESP SG
0x1 = Druckschwelleninformation kann noch nicht oder aufgrund eines Fehlers nicht ausgegeben werden
";
CM_ SG_ 262 ESP_Schwelle_Unterdruck "Verwendung im MQB für HBV-Projekte";
CM_ SG_ 262 ESP_Bremsdruck "Rohwert des Bremsdrucks [Vordruck durch Fahrervorgabe (Pvor). Bei aktivem Druckaufbau (Stabilisierungseingriffe) kein Pvor]
";
CM_ SG_ 262 ESP_Fahrer_bremst "Bit wird gesetzt beim Überschreiten der Bremsdruckschwelle

Weiterführende Informationen im Lastenheft spezifiziert und in der entsprechenden Fachabteilung zu erfragen.
";
CM_ SG_ 262 ESP_Verz_TSK_aktiv "Rückmeldeinformation an den Triebsstrangkoordinator/ACC, dass die ECD-Verzögerungsanforderung aktuell umgesetzt wird";
CM_ SG_ 262 ESP_Lenkeingriff_ADS "Im Falle eines fahrzeugstabilisierenden Lenkeingriffs des ADS-Systems soll ACC/GRA deaktiviert werden.

Im MQB wird dieses Signal nicht unterstützt!";
CM_ SG_ 262 ESP_Konsistenz_TSK "Rückmeldung zum Sender einer Verzögerungsanforderung (Triebstrangskoordinator) bezüglich Prüfung der Checksumme, des Botschaftszählers, des langen Timeout und DLC. Wird auch gesetzt bei Verzögerungsanforderung größer einer applizierbaren Schwelle.
";
CM_ SG_ 262 ESP_Bremsruck_AWV2 "Das Signal dient als Rückmeldung zum ACC, dass ein angeforderter AWV2-Bremsruck durchgeführt wird. Die positive Rückmeldung löst u.a. eine entsprechende Fahrerinformation im Kombiinstrument aus";
CM_ SG_ 262 ESP_Konsistenz_AWV2 "Rückmeldung zum Sender einer AWV-Anforderung (ACC-Steuergerät) bezüglich Prüfung der Checksumme, des Botschaftszählers, des langen Timeout und DLC.
";
CM_ SG_ 262 ECD_Fehler "ESP kann die Verzögerungsregelung/Bremsenregelung aufgrund eines internen Fehlers nicht ausführen, mit Fehlereintrag im ESP.
";
CM_ SG_ 262 ECD_nicht_verfuegbar "ESP kann die Verzögerungsregelung/Bremsenregelung temporär nicht ausführen (z.B. Netzwerkmanagement-Betriebe - KL15 Aus; v<18km/h; ESP in Diagnose, ...), ohne Fehlereintrag im ESP.

";
CM_ SG_ 262 ESP_Status_Bremsentemp "ECD-Bremsscheibentemperaturmodell. Rückmeldung für Sender einer ECD Verzögerungsanforderung, ohne Fehlereintrag im ESP";
CM_ SG_ 262 ESP_Autohold_Standby "Rückmeldung an EPB, dass der Fahrer die Funktion Autohold mindestens einmal angefordert hat. Im Fall eines ESP-Ausfalles oder einer Übernahmeaufforderung erfolgt die EPB-Zuschaltung nur nach Setzen dieses Bits. Bit wird gesetzt nach Betätigung des Autohol";
CM_ SG_ 262 ESP_HDC_Standby "Verwendung/Bedienung im MQB und AU57x Allroad:
Flag wird vom ESP gesetzt, wenn über den HDC-Taster die HDC-Funktion eingeschalten wurde";
CM_ SG_ 262 ESP_HBA_aktiv "Verwendung/Bedienung ab D4
Signal gibt an, ob der hydraulische Bremsassistent im Regler aktiviert wurde

Im MQB wird das Signal nicht unterstützt!

";
CM_ SG_ 262 ESP_Prefill_ausgeloest "MLB: Verwendung/Bedienung ab D4
zeigt, ob die Funktion Prefill (aufgrund Fahrpedalgradient) ausgelöst wird; zeigt keinen Funktionszustand bezüglich Fehlerstilllegung

MQB: Wird gesetzt bei jeder Art von aktivem Prefill";
CM_ SG_ 262 ESP_Rueckwaertsfahrt_erkannt "nur bei AU57x und AU416 sowie Audi B8PA
Info, ob Rückwärtsfahrt über internen Algorithmus sicher erkannt

Im MQB wird das Signal nicht unterstützt!";
CM_ SG_ 262 ESP_Status_Anfahrhilfe "Funktionsstatus des Berganfahrassistenten
MQB: Auswertung im Getriebe zwecks Standabkopplung";
CM_ SG_ 262 ESP_HDC_aktiv "MQB und AU57x Allroad: Mit diesem Statusbit wird eine gerade aktive Regelung des Bergabfahrassistenten (Hill Descent Control) signalisiert.";
CM_ SG_ 262 ESP_StartStopp_Info "Stopp-Freigabe und Start-Anforderung an den Start-Stopp-Koordinator";
CM_ SG_ 262 ESP_Eingr_HL "wird von QSP und Neigungsanzeige verwendet

Flag wird vom ESP gesetzt, sobald aufgrund eines ESP-Eingriffs am Rad aktiv Druck aufgebaut wird.
Frühestens mit öffnen des Ventils und spätestens bei einem Bremsmoment von 100Nm. Flag bleibt solange gesetzt ";
CM_ SG_ 262 ESP_Eingr_HR "wird von QSP und Neigungsanzeige verwendet

Flag wird vom ESP gesetzt, sobald aufgrund eines ESP-Eingriffs am Rad aktiv Druck aufgebaut wird.
Frühestens mit öffnen des Ventils und spätestens bei einem Bremsmoment von 100Nm. Flag bleibt solange gesetzt ";
CM_ SG_ 262 ESP_Eingr_VL "wird von QSP und Neigungsanzeige verwendet

Flag wird vom ESP gesetzt, sobald aufgrund eines ESP-Eingriffs am Rad aktiv Druck aufgebaut wird.
Frühestens mit öffnen des Ventils und spätestens bei einem Bremsmoment von 100Nm. Flag bleibt solange gesetzt ";
CM_ SG_ 262 ESP_Eingr_VR "wird von QSP und Neigungsanzeige verwendet

Flag wird vom ESP gesetzt, sobald aufgrund eines ESP-Eingriffs am Rad aktiv Druck aufgebaut wird.
Frühestens mit öffnen des Ventils und spätestens bei einem Bremsmoment von 100Nm. Flag bleibt solange gesetzt ";
CM_ SG_ 262 ESP_BKV_Unterdruck "Der maximale Wert wird auf 1012 mbar begrenzt.
Dieses Signal wird im AU64x nicht unterstützt.

Hinweis: Auch bei nicht verbautem BKV-Unterdrucksensor könnte während der Initialisierung der Initialisierungswert gesendet werden.";
CM_ SG_ 262 ESP_Autohold_aktiv "Rückmeldung an EPB, dass Autohold aktiv ist.";
CM_ SG_ 262 ESP_FStatus_Anfahrhilfe "Bei gesetztem Bit steht die Funktion Berganfahrassistent (Hillhold) nicht zur Verfügung";
CM_ SG_ 262 ESP_Verz_EPB_aktiv "Bei gesetztem Bit wird die Verzögerungsanforderung von EPB umgesetzt.";
CM_ SG_ 262 ECD_Bremslicht "Bremslichtansteuerung durch ECD-Funktion";
CM_ SG_ 262 ESP_Verzoeg_EPB_verf "Bei gesetztem Bit ist der Verzögerungsregeler für EPB verfügbar.";
CM_ SG_ 262 ESP_Status_Bremsdruck "MLB: Bei gesetztem Bit liegt p > ca. 2 bar an, hervorgerufen durch Fahrer, ASR, FZR, ECD, Bremsregler ... bei Abfall des Bits ist p < X bar, bei aktivem ECD-Eingriff Ende des Eingriffs 

Weiterführende Informationen im Lastenheft spezifiziert und in der";
CM_ SG_ 262 ESP_Anforderung_EPB "ESP fordert von der EPB Öffnen bzw. Schliessen an. Notwendig wegen Autohold-Funktion.";
CM_ SG_ 132 ESP_06_CHK "Berechnung siehe Lastenheft 'Kommunikationsabsicherung für FlexRay und CAN'
Endwerte siehe 'Kommunikationsabsicherung für FlexRay und CAN / Anhang C: Tabelle S-PDU Kennungen'";
CM_ SG_ 132 ESP_06_KD_Fehler "Verwendung nur im D4";
CM_ SG_ 132 ESP_Teilsollwinkel "Externe Winkelanforderung des ESP an SCU";
CM_ SG_ 132 ESP_VZ_Teilsollwinkel "Vorzeichen der externen Winkelanforderung";
CM_ SG_ 132 ESP_Winkeleingriff "Eingriffsbestätigung der externen Winkelanforderung inkl. Art des Eingriffs
";
CM_ SG_ 132 ESP_Status_ADS "Interner Fehlerstatus der Funktion ADS (integriert im ESP)";
CM_ SG_ 132 ESP_v_ref "MLB: Exklusives Signal vom BOSCH ESP zum BOSCH Airbag für ROSEII Funktion, nicht für andere Empfänger!

MQB: Zusätzliches v-Signal als Referenzgeschwindigkeit für die Funktion Fußgängerschutz. Ausgabe der berechneten Geschwindigkeit 'über Grund', d. h. ";
CM_ SG_ 132 ESP_Monitoring_Gierrate "Monitoring-Signal zur Darstellung der Signalgüte des übermittelten Gierratenrohwertes.";
CM_ SG_ 132 ESP_Monitoring_Laengsb "Monitoring-Signal zur Darstellung der Signalgüte des übermittelten Längsbeschleunigungsrohwertes.";
CM_ SG_ 132 ESP_Monitoring_Lenkwinkel "Monitoring-Signal zur Darstellung der Signalgüte des übermittelten Lenkwinkelrohwertes.";
CM_ SG_ 132 ESP_Monitoring_Querb "Monitoring-Signal zur Darstellung der Signalgüte des übermittelten Querbeschleunigungsrohwertes. ";
CM_ SG_ 132 ESP_06_CRC "Für MLB:
'Berechnung siehe Lastenheft 'Kommunikationsabsicherung für FlexRay und CAN'

Ab MQB und MLBevo:
'Berechnung siehe Lastenheft 'End-to-End Kommunikationsabsicherung''

Endwerte siehe Begleitdokument 'S-PDU Kennungsfolgen'";
CM_ BO_ 914 "MLB (80ms)";
CM_ SG_ 914 ESP_07_CHK "Berechnung siehe Lastenheft 'Kommunikationsabsicherung für FlexRay und CAN'
Endwerte siehe 'Kommunikationsabsicherung für FlexRay und CAN / Anhang C: Tabelle S-PDU Kennungen'";
CM_ SG_ 914 ESP_ACC_LDE "Verwendung/Bedienung ab Folgeprojekte D4, aber nicht im D4 selbst
Lebensdauerende für ACC-Bremsung erreicht";
CM_ SG_ 914 ESP_Quattro_Antrieb "Im MQB wird das Signal nicht unterstützt!";
CM_ SG_ 914 ESP_Codierung_ADS "ESP gibt für Empfänger im Fahrzeug aus, ob ADS verbaut/nicht verbaut ist.

Im MQB wird das Signal nicht unterstützt!
";
CM_ SG_ 914 ESP_RTA_HL "Physikalischer Wertebereich +/-5%. Der Reifentoleranzabgleich bezieht sich auf das linke Vorderrad.

physikalischer Wert = ( (Hex-Wert - 0x7F) / 2048 )*100%

Im MQB wird das Signal nicht unterstützt!";
CM_ SG_ 914 ESP_RTA_HR "Physikalischer Wertebereich +/-5%. Der Reifentoleranzabgleich bezieht sich auf das linke Vorderrad.

physikalischer Wert = ( (Hex-Wert - 0x7F) / 2048 )*100%

Im MQB wird das Signal nicht unterstützt!";
CM_ SG_ 914 ESP_RTA_VR "Physikalischer Wertebereich +/-5%. Der Reifentoleranzabgleich bezieht sich auf das linke Vorderrad.

physikalischer Wert = ( (Hex-Wert - 0x7F) / 2048 )*100%

Im MQB wird das Signal nicht unterstützt!";
CM_ SG_ 914 OBD_Fehler_Radsensor_HL "Für Motor-SG (gesetzliche Vorgabe)";
CM_ SG_ 914 OBD_Fehler_Radsensor_HR "Für Motor-SG (gesetzliche Vorgabe)";
CM_ SG_ 914 OBD_Fehler_Radsensor_VL "Für Motor-SG (gesetzliche Vorgabe)";
CM_ SG_ 914 OBD_Fehler_Radsensor_VR "Für Motor-SG (gesetzliche Vorgabe)";
CM_ SG_ 914 ESP_Qualifizierung_Antriebsart "Signal for Bentley BY83x: ESP_wheel_drive_selector

Bit qualifiziert für neue Projekte (ab D4 ff.) das Signal 'ESP_Quattro_Antrieb', d.h. ist 'ESP_Qualifizierung_Antriebsart'
auf 0x1 gesetzt, ändert sich die bisherige Bedeutung des Signals 'ESP_Quattro";
CM_ SG_ 914 ESP_Offroad_Modus "Nur VW526: Bei Offroad-Fahrzeugen kann über einen Schalter ein Offroadmodus gewählt werden, dieser wird hier angezeigt. Bei Offroad Plus- Fahrzeugen wird hier der Offroadmodus indirekt durch das Verteilergetriebe vorgegeben (ALR_Offroad = 1) und eingespie";
CM_ SG_ 914 ESP_MKB_ausloesbar "ESP hat Funktion Multi-Kollisions-Bremsung freigeschaltet";
CM_ SG_ 914 ESP_Stat_FallBack_eBKV "Das Signal zeigt dem eBKV an, ob seine Rückfallebene im ESP verfügbar ist.";
CM_ SG_ 914 ESP_CM_Variante "Signal gibt an welche CM-Variante unterstuetzt wird. 
";
CM_ SG_ 914 ESP_OBD_Status "Dieses Bit steuert die MIL-Lampe an (Motorsteuergerät reicht diese Info an Kombi weiter).";
CM_ SG_ 914 ESP_Rollenmodus_Deaktivieren "Zwang zum Abbruch des Rollenmodus mit anschließender ESP-Vollfunktion.
MQB: Zwang zum Abbruch des Rollenmodus in allen Funktionsteilnehmern (Empfänger) mit anschließender ESP-Vollfunktion (Sender).
Signal wird vom ESP dauerhaft mit gültigen Werten bedat";
CM_ SG_ 914 ESP_nachtr_Stopp_Anf "Dieses Signal dient dem Motor als Trigger, dass ein nachträglicher Motorstopp eingeleitet werden kann, wenn es die Bedingungen des StSt Koordinators dies zulassen. ";
CM_ SG_ 169 ESP_16_CRC "Für MLB:
'Berechnung siehe Lastenheft 'Kommunikationsabsicherung für FlexRay und CAN''

Ab MQB und MLBevo:
'Berechnung siehe Lastenheft 'End-to-End Kommunikationsabsicherung''

Endwerte siehe Begleitdokument 'S-PDU Kennungsfolgen'";
CM_ SG_ 169 ESP_Eingriffsmoment "Zu stellendes negatives Moment durch die E-Maschine des Hybridantriebs zur rekuperativen Verzögerung, angefordert durch das ESP

Achtung:
Einheitenloser CAN-Wert.
Faktor in MO_Faktor_Momente in Motor_Code_01 beachten!";
CM_ SG_ 169 ESP_Antrieb_Anf "Beenden hybridspezifischer Funktionalitäten in einer zu definierenden Zeit t.
Nachbildung eines konventionell angetriebenen Fahrzeuges (z.B. K0 geschlossen, Nachbildung Generator, serienmäßige Antriebs- u. Schubmomente, Anfahrvorgang)";
CM_ SG_ 169 ESP_Reku_Anf "Anforderung an den Motor ein negatives E-Maschinen Moment zu stellen (Freigabe-Bit)";
CM_ SG_ 169 ESP_Bremspedalweg "Bremspedalweg in Prozent. Der Wert ist Nullpunkt-abgeglichen.";
CM_ SG_ 169 ESP_Reku_Index "Der Rekuperationsindex dient zur Einschränkung bzw. Verbot von der Rekuperation des Motorsteuergerätes";
CM_ SG_ 169 ESP_Reku_Limit "Maximales Rekuperationsmoment welches vom Motor gestellt werden darf

Achtung Einheitenloser Wert
Faktor in MO_Faktor_Momente in Motor_Code_01 beachten";
CM_ SG_ 169 ESP_Haltebestaetigung "Rückmeldung vom ESP-SG, dass das Fahrzeug aufgrund einer externen Bremsanforderung (z. B. ACC, PLA, ANB, o. ä.) abgebremst wurde und im Stillstand gehalten wird.";
CM_ SG_ 169 ESC_Motorstartverzoegerung "Mit dem Signal 'Motorstartverzögerung' wird den aktiven Teilnehmern ermöglicht, einen Motorstart durch die Start-Stop-Funktion zu verzögern.";
CM_ SG_ 169 ESP_KD_OBD_Readiness "Übertragung der Information vom Bremsensteuergerät an das Motorsteuergerät, ob die Diagnose zum EHC-Systemfehler im aktuellen Driving Cycle bereits durchgeführt wurde.";
CM_ SG_ 169 ESP_KD_OBD_Fehler "Übertragung des letzten Diagnoseergebnis zum EHC-Systemfehler vom Bremsensteuergerät an das Motorsteuergerät.";
CM_ BO_ 1623 "Bentley Hut-Botschaft";
CM_ SG_ 1623 ESP_17_CRC "Für MLB:
'Berechnung siehe Lastenheft 'Kommunikationsabsicherung für FlexRay und CAN''

Ab MQB und MLBevo:
'Berechnung siehe Lastenheft 'End-to-End Kommunikationsabsicherung''

Endwerte siehe Begleitdokument 'S-PDU Kennungsfolgen'";
CM_ SG_ 1623 ESP_BremsenTemp_hinten "Modellbasierte Bremsentemperatur hinten";
CM_ BO_ 924 "
Botschaft für Antriebs- und Fahrwerks-/Kombi-CAN";
CM_ SG_ 924 GW_05_va_27 "
Platzhalter für veraltet Bit in Gatewaybotschaften

GWxx_va_yz

xx: Index der Gatewaybotschaft
y: Byteposition des veraltet Bits
z: Bitposition des veraltet Bits";
CM_ SG_ 924 BCM1_MH_WIV_Schalter "Bewerteter Motorhaubenkontakt fuer WIV";
CM_ SG_ 924 Wischer_vorne_aktiv "Status: Wischer vorne ";
CM_ SG_ 924 BCM1_Rueckfahrlicht_Schalter "Rückfahrlichtschalter
ab MQB/ MLBevo: Die Ganginformation wird unentprellt übertragen, im AT-Getriebe wird evtl. kurzzeitig der R-Gang angezeigt. Eine Entprellung muß im Empfänger erfolgen (typisch 400ms).";
CM_ SG_ 924 MO_Status_Normalbetrieb_01 "Das Motorsteuergerät sendet das Informationsbit, wenn die Initialisierungsphase des Steuergerätes abgeschlossen ist. Zusätzlich muss die Klemme 15 eingeschalten sein und eine applizierbare Mindestdrehzahlschwelle (Kennlinie in Abh. von der Kühlwassertempe";
CM_ SG_ 924 KL_Zuheizer_Freigabe "Freigabe Zuheizer
";
CM_ SG_ 924 BCM1_Vorwaertsgang_eingelegt "Erkennung Vorwärtsgang eingelegt (1. / 2. Gang)";
CM_ SG_ 924 ESP_Codierung_ADS "ESP gibt für Empfänger im Fahrzeug aus, ob ADS verbaut/nicht verbaut ist.

Im MQB wird das Signal nicht unterstützt!
";
CM_ SG_ 924 QSP_StartStopp_Info "Stopp-Freigabe und Start-Anforderung an den Start-Stopp-Koordinator";
CM_ SG_ 924 FA_StartStopp_Info "Stopp-Freigabe und Start-Anforderung an den Start-Stopp-Koordinator";
CM_ SG_ 924 PH_StartStopp_Info "Stopp-Freigabe und Start-Anforderung an den Start-Stopp-Koordinator";
CM_ SG_ 924 KL_Beschlagsgefahr "Beschlagsgefahr auf der Frontscheibe im Bereich des Spiegelfusses. Dient zur präventiven Ansteuerung der  Kamera-Scheibenheizung, um Kamera-Blindheit zu vermeiden
PHEV: volle Leistungsfreigabe 
HV Heizer und HV EKK bei Scheibenbeschlag ";
CM_ SG_ 924 BCM1_GLW_Fernlicht_Anf "Harte Fernlichtanforderung von BCM1 an die Funktion 'gleitende Leuchtweite' im AFS-SG";
CM_ SG_ 924 BCM1_RFahrlicht_Fzg_Anf "Anforderung: Rückfahrlicht Fahrzeug (Sollzustand)";
CM_ SG_ 924 MO_Handshake_STH "Es gilt: Signalspec MO_Handshake v1.0

Handshake zwischen MSG und STH. Wenn das MSG die EKP aufgrund einer STH-Anforderung ansteuert und kein Fehlereintrag bzgl. EKP/KPE/NDR vorliegt, wird das Bit gesetzt.";
CM_ SG_ 924 FT_Sperrklinke "Vorraste für Schloß

zwischen Vor- und Hauptraste Signal kurz auf 1, danach wieder auf 0 wenn Tür in Hauptraste (Tür ist sicher zu wenn Sperrklinke und Türkontakt auf 0 sind)";
CM_ SG_ 924 BCM1_OBD_FStatus_ATemp "Fehlerstatus Umgebungstemperatursensor (OBD relevanter Sensor)
";
CM_ SG_ 924 BCM1_Aussen_Temp_ungef "ungefilterter Wert des Aussentemperatursensors
";
CM_ SG_ 924 BCM1_Oeldruck_Schalter "Schalter Oeldruck vorhanden --> nur im B8, nicht im D4 verwendet


";
CM_ SG_ 924 BCM1_Oeldruck_Schalter_2 "Vorhalt Schalter Oeldruck 

nicht im B8 und D4 verwendet

";
CM_ SG_ 924 BT_Tuer_geoeffnet "
";
CM_ SG_ 924 BCM1_Adaptive_Lichtvert_Anf "Funktion 'Adaptive Lichtverteilung' im AFS-SG  Ein- und Ausschalten";
CM_ SG_ 924 BCM1_Gleitende_Leuchtw_Anf "Funktion 'Gleitende Leuchtweite' im AFS-SG  freischalten";
CM_ SG_ 924 BCM1_Schalter_StartStopp "Deaktivierung Start/Stopp über Fahrer";
CM_ SG_ 924 ESP_Offroad_Modus "Nur VW526: Bei Offroad-Fahrzeugen kann über einen Schalter ein Offroadmodus gewählt werden, dieser wird hier angezeigt. Bei Offroad Plus- Fahrzeugen wird hier der Offroadmodus indirekt durch das Verteilergetriebe vorgegeben (ALR_Offroad = 1) und eingespie";
CM_ SG_ 924 MO_Freig_Reku "Empfehlung des Motor-SG's zur Spannungsabsenkung/-anhebung für den Rekuperationsbetrieb";
CM_ SG_ 924 KL_HSH_ein_Soll "Fahrerwunsch (Anforderung) Heckscheibenheizung
";
CM_ SG_ 924 FT_Tuerkontakt_Rohsignal "Logischer Pegel der HW-Leitung des Türkontaktes, welche vom TSG eingelesen wird.
0 > Schalter geschlossen (Tür  auf) 
1 > Schalter offen (Tür zu)

Ungefilterter und unplausibilisierter Status der HW-Leitung vom Türkontakt Fahrertür.";
CM_ SG_ 924 FT_TD_Taste_Fehler "Fehlerstatus des Tankdeckelentriegelungstasters. Wird bei Drucktankkonzepten vom MSG zusammen mit dem Signal FT_TD_Taste ausgewertet, um Tankbereitschaft herzustellen.
Der Fehler beschreibt einen hängenden TD_Taster. Ein Kurzschluss oder Leitungsunterbre";
CM_ SG_ 924 PH_nachtr_Stopp_Anf "Dieses Signal dient dem Motor als Trigger, dass ein nachträglicher Motorstopp eingeleitet werden kann, wenn es die Bedingungen des StSt Koordinators dies zulassen. ";
CM_ BO_ 1604 "
langsame Gatewaybotschaft für den ACAN";
CM_ SG_ 1604 Lift_01_alt "Veraltet-Bit für die Signale:

Botschaft Charisma_06_PAG:
Lift_Charisma_FahrPr
Lift_Charisma_Status
Lift_Charisma_Umschaltung

Botschaft GW_Fwk_01_Ant_PAG:
Lift_Status

";
CM_ SG_ 1604 GW_11_va_22 "
Platzhalter für veraltet Bit in Gatewaybotschaften

GWxx_va_yz

xx: Index der Gatewaybotschaft
y: Byteposition des veraltet Bits
z: Bitposition des veraltet Bits";
CM_ SG_ 1604 GW_11_va_23 "
Platzhalter für veraltet Bit in Gatewaybotschaften

GWxx_va_yz

xx: Index der Gatewaybotschaft
y: Byteposition des veraltet Bits
z: Bitposition des veraltet Bits";
CM_ SG_ 1604 GW_11_va_24 "
Platzhalter für veraltet Bit in Gatewaybotschaften

GWxx_va_yz

xx: Index der Gatewaybotschaft
y: Byteposition des veraltet Bits
z: Bitposition des veraltet Bits";
CM_ SG_ 1604 GW_11_va_25 "
Platzhalter für veraltet Bit in Gatewaybotschaften

GWxx_va_yz

xx: Index der Gatewaybotschaft
y: Byteposition des veraltet Bits
z: Bitposition des veraltet Bits";
CM_ SG_ 1604 GW_11_va_26 "
Platzhalter für veraltet Bit in Gatewaybotschaften

GWxx_va_yz

xx: Index der Gatewaybotschaft
y: Byteposition des veraltet Bits
z: Bitposition des veraltet Bits";
CM_ SG_ 1604 GW_11_va_27 "
Platzhalter für veraltet Bit in Gatewaybotschaften

GWxx_va_yz

xx: Index der Gatewaybotschaft
y: Byteposition des veraltet Bits
z: Bitposition des veraltet Bits";
CM_ SG_ 1604 BH_Blinker_li "Blinkerhebel Richtung links
";
CM_ SG_ 1604 BH_Blinker_re "Blinkerhebel Richtung rechts
";
CM_ SG_ 1604 BM_Autobahn "Status Autobahnblinken
";
CM_ SG_ 1604 BH_Fernlicht "Betaetigung Fernlicht
";
CM_ SG_ 1604 BH_Lichthupe "Betaetigung Lichthupe
";
CM_ SG_ 1604 BCM1_MH_Schalter "Motorhaubenkontakt";
CM_ SG_ 1604 HYB_Anf_E_Mode "Zustand des E-Mode Tasters bei Hybrid-Fhz. Es wird der entprellte Betätigungszustand übertragen (betätigt/ nicht betätigt). Die Umwandlung des Tastersignals in ein statisches Schaltersignal erfolgt im MSG.";
CM_ SG_ 1604 HUD_NV_in_Anzeige "Rueckmeldung,ob NV-Inhalte im HUD angezeigt werden.";
CM_ SG_ 1604 BCM1_Touristen_Licht_Anf "Anforderung: Touristenlicht (Sollzustand)";
CM_ SG_ 1604 LV_Abblendlicht_li_def "Fehlerstatus Abblendlicht vorne links 
";
CM_ SG_ 1604 LV_Abblendlicht_re_def "Fehlerstatus Abblendlicht vorne rechts
";
CM_ SG_ 1604 LV_Abblendlicht_Anzeige "Abblendlicht aktiv";
CM_ SG_ 1604 LV_AFL_aktiv_Anzeige "Anzeige AFL-Funktion";
CM_ SG_ 1604 BCM1_Licht_Dunkelheit_aktiv "Licht aktiv aufgrund von Dunkelheit (nicht bei Autobahn-, Tagfahr- oder Regenlicht)
";
CM_ SG_ 1604 LV_Nebelschlusslicht_Anzeige "Nebelschlusslicht_aktiv
";
CM_ SG_ 1604 BCM1_Linksverkehr "Information über Aufbauzustand des Fzg:
0 = Scheinwerfer für Rechtsverkehr
1 = Scheinwerfer für Linksverkehr";
CM_ SG_ 1604 BCM2_P_verriegelt "Nicht plausibilisiertes Rohsignal des P-Verriegeltschalters vom Wählhebel zur exklusiven Nutzung für Getriebesteuergeräte:
";
CM_ SG_ 1604 BCM1_LDS_Stellung "Das Signal wird vom AFS / LWR Steuergerät empfangen und dient der Verifizierung der Lichtdrehschalterstellung. Intelligente Lichtfunktionen wie dyn. KL und gleitende Leuchtweite (GLW) nur bei LDS = 'AUTO'.";
CM_ SG_ 1604 BCM1_Allwetterlicht_Anf "Anforderung eines Allwetterlichts (über AFS-SG realisiert): Licht für schlechte Sichtverhältnisse";
CM_ SG_ 1604 HUD_Anzeigefehler_NV "Nightvisionbild kann im HUD aufgrund eines Fehlers nicht angezeigt werden";
CM_ SG_ 1604 ESP_Diagnose "MLB: Nach Diagnoseende wird ein SW-Reset ausgelöst welcher einen Kommunikatiosausfall für max. 150ms verursacht. Dies ist bei SG mit verschärfter Timeoutüberwachung (nicht nach Konzern-LH) zu beachten.

MQB: Weiterführende Informationen im Lastenheft sp";
CM_ SG_ 1604 BCM1_SRA_aktiv "Status Scheinwerferreinigungsanlage";
CM_ SG_ 1604 FFB_Auf_Taste "Auf-Taste Funkschluessel

";
CM_ SG_ 1604 FFB_CarFinder "Car Finder Funktion (Blinken ohne zu entriegeln)";
CM_ SG_ 1604 ZV_verriegelt_extern_ist "Istzustand: Verriegelung Fahrzeug aussen
";
CM_ SG_ 1604 BCM_Tankwunsch "Tankwunsch (Fahrer betätigt Tankdeckeltaster)";
CM_ SG_ 1604 ZV_Tankklappe_offen "Öffnungsstatus der Tankklappe";
CM_ SG_ 130 Getriebe_01_CHK "Berechnung siehe Lastenheft 'Kommunikationsabsicherung für FlexRay und CAN'
Endwerte siehe 'Kommunikationsabsicherung für FlexRay und CAN / Anhang C: Tabelle S-PDU Kennungen'";
CM_ SG_ 130 GE_Schaltvorgang "AL-Getriebe:
Signalisiert wenn ein Gangwechsel durch die jeweiligen Gangssteller durchgeführt wird. Gangwechsel in und aus R werden nicht als Schaltvorgang signalisiert.

DL-Getriebe:
Signalisiert wenn ein Gangwechsel durch die jeweiligen Gangssteller";
CM_ SG_ 130 GE_Status_Kupplung "Status Kupplung
VL: Statusausgabe der Vorwärtskupplung
DL: Statusausgabe der Kraftschluss führenden Kupplung
AL: Statusausgabe der Wandlerüberbrückungskupplung

Alle: Keine Statusausgabe bei Rückwärtsfahrt.";
CM_ SG_ 130 GE_Verbot_Ausblendung "Verbot Einspritzausblendung für komfortable Schaltungen";
CM_ SG_ 130 GE_MMom_Soll "Fordert vom MSG eine kurzfristige Reduzierung oder eine Anhebung des Motormoents

Achtung!
Einheitloser Wert. Faktor in MO_Faktor_Moment in Motor_Code_01 beachten!";
CM_ SG_ 130 GE_MMom_Status "Qualifiziert 
MLB: GE_MMom_Soll
MQB: GE_MMom_Soll_02";
CM_ SG_ 130 GE_Freig_Mmom_Soll "Dient als Freigabesignal für MLB: 'GE_MMom_Sol', MQB: 'GE_MMom_Soll_02' zum Getriebe-Momenteneingriff während eines Schaltvorganges und ist bei einer aktiven Momentenanforderung auf '1' gesetzt. Besteht keine Anforderung mehr wird der Signalwert auf '0' g";
CM_ SG_ 130 GE_Status_Schaltablauf "Signal dient zur Auswahl verschiedener Motorführungsvarianten durch das
Getriebe bei Schaltungen und in Situationen, wenn z.B. der Abtrieb an den
Motor geführt angekoppelt werden soll.

Signal wird nur von Porsche genutzt!";
CM_ SG_ 130 GE_MMom_Vorhalt "Anforderung einer Momentenreserve durch das Getriebe, inneres Moment, gilt nur mit Freigabe durch 
GE_Freig_MMom_Vorhalt

Achtung!
Einheitenloser CAN-Wert.
Faktor in MO_Faktor_Momente in Motor_Code_01 beachten!";
CM_ SG_ 130 GE_Freig_MMom_Vorhalt "Freigabe für die Anforderung einer Momentenreserve durch das Getriebe über das Signal
MLB: GE_MMom_Vorhalt
MQB: GE_MMom_Vorhalt_02";
CM_ SG_ 130 GE_KD_Fehler "Status Kundendienst-Fehlerspeicher";
BA_DEF_ BO_  "DiagRequest" ENUM  "No","Yes";
BA_DEF_ BO_  "DiagResponse" ENUM  "No","Yes";
BA_DEF_ BO_  "DiagState" ENUM  "No","Yes";
BA_DEF_ BO_  "GenMsgChkConstant" HEX 0 4095;
BA_DEF_ BO_  "GenMsgCycleTime" INT 0 65535;
BA_DEF_ BO_  "GenMsgCycleTimeFast" INT 0 65535;
BA_DEF_ BO_  "GenMsgDelayTime" INT 0 100000;
BA_DEF_ BO_  "GenMsgILSupport" ENUM  "No","Yes";
BA_DEF_ BO_  "GenMsgNrOfRepetition" INT 0 100;
BA_DEF_ BO_  "GenMsgPDUConstants" STRING ;
BA_DEF_ BO_  "GenMsgSendType" ENUM  "Cyclic","not_used","not_used","not_used","not_used","not_used","not_used","IfActive","NoMsgSendType";
BA_DEF_ BO_  "GenMsgStartDelayTime" INT 0 100000;
BA_DEF_ BO_  "NmMessage" ENUM  "No","Yes";
BA_DEF_ BO_  "NmhMessage" ENUM  "No","Yes";
BA_DEF_ BO_  "MsgType" ENUM  "Application","NM ","NMH","TP2.0","ISO-TP ","BAP","EID";
BA_DEF_ BO_  "VAGTP20_API" HEX 0 255;
BA_DEF_ BO_  "VAGTP20_DynConnection" ENUM  "No","Yes";
BA_DEF_ BO_  "VAGTP20_DynSetup" ENUM  "No","Yes";
BA_DEF_ BO_  "VAGTP20_StatConnection" ENUM  "No","Yes";
BA_DEF_ SG_  "GenSigActiveRepetitions" INT -2147483648 2147483647;
BA_DEF_ SG_  "GenSigInactiveValue" INT -2147483648 2147483647;
BA_DEF_ SG_  "GenSigSendType" ENUM  "Cyclic","OnWrite","OnWriteWithRepetition","OnChange","OnChangeWithRepetition","IfActive","IfActiveWithRepetition","NoSigSendType","OnChangeAndIfActive","OnChangeAndIfActiveWithRepetition";
BA_DEF_ SG_  "GenSigStartValue" INT -2147483648 2147483647;
BA_DEF_ SG_  "NWM-WakeupAllowed" ENUM  "No","Yes";
BA_DEF_ SG_  "GenSigFuncType" ENUM  "NoFunction","MsgCounter","CRC-8","XOR","XOR-2","DatedBit","SW-Kl15","CHK","Constant","Protocol","CRC-8-SAE_J1850";
BA_DEF_ SG_  "GenSigSwitchedByIgnition" ENUM  "No","Yes";
BA_DEF_ SG_  "Fehlerwert" HEX 0 2147483647;
BA_DEF_ SG_  "GenSigMissingSourceValue" HEX 0 2147483647;
BA_DEF_REL_ BU_SG_REL_  "GenSigTimeoutTime" INT 0 65535;
BA_DEF_DEF_REL_ "GenSigTimeoutTime" 0;
BA_DEF_DEF_  "DiagRequest" "No";
BA_DEF_DEF_  "DiagResponse" "No";
BA_DEF_DEF_  "DiagState" "No";
BA_DEF_DEF_  "GenMsgChkConstant" 0;
BA_DEF_DEF_  "GenMsgCycleTime" 0;
BA_DEF_DEF_  "GenMsgCycleTimeFast" 0;
BA_DEF_DEF_  "GenMsgDelayTime" 0;
BA_DEF_DEF_  "GenMsgILSupport" "No";
BA_DEF_DEF_  "GenMsgNrOfRepetition" 0;
BA_DEF_DEF_  "GenMsgPDUConstants" "";
BA_DEF_DEF_  "GenMsgSendType" "NoMsgSendType";
BA_DEF_DEF_  "GenMsgStartDelayTime" 0;
BA_DEF_DEF_  "NmMessage" "No";
BA_DEF_DEF_  "NmhMessage" "No";
BA_DEF_DEF_  "MsgType" "Application";
BA_DEF_DEF_  "VAGTP20_API" 0;
BA_DEF_DEF_  "VAGTP20_DynConnection" "No";
BA_DEF_DEF_  "VAGTP20_DynSetup" "No";
BA_DEF_DEF_  "VAGTP20_StatConnection" "No";
BA_DEF_DEF_  "GenSigActiveRepetitions" 0;
BA_DEF_DEF_  "GenSigInactiveValue" 0;
BA_DEF_DEF_  "GenSigSendType" "NoSigSendType";
BA_DEF_DEF_  "GenSigStartValue" 0;
BA_DEF_DEF_  "NWM-WakeupAllowed" "No";
BA_DEF_DEF_  "GenSigFuncType" "NoFunction";
BA_DEF_DEF_  "GenSigSwitchedByIgnition" "Yes";
BA_DEF_DEF_  "Fehlerwert" 0;
BA_DEF_DEF_  "GenSigMissingSourceValue" 0;
BA_ "MsgType" BO_ 2617042433 6;
BA_ "GenMsgPDUConstants" BO_ 901 "0x86,0x86,0x86,0x86,0x86,0x86,0x86,0x86,0x86,0x86,0x86,0x86,0x86,0x86,0x86,0x86";
BA_ "GenMsgNrOfRepetition" BO_ 901 5;
BA_ "GenMsgILSupport" BO_ 901 1;
BA_ "GenMsgDelayTime" BO_ 901 10;
BA_ "GenMsgCycleTimeFast" BO_ 901 100;
BA_ "GenMsgChkConstant" BO_ 901 134;
BA_ "GenMsgSendType" BO_ 918 0;
BA_ "GenMsgPDUConstants" BO_ 918 "0x95,0x95,0x95,0x95,0x95,0x95,0x95,0x95,0x95,0x95,0x95,0x95,0x95,0x95,0x95,0x95";
BA_ "GenMsgILSupport" BO_ 918 1;
BA_ "GenMsgCycleTime" BO_ 918 80;
BA_ "GenMsgChkConstant" BO_ 918 149;
BA_ "GenMsgSendType" BO_ 945 0;
BA_ "GenMsgILSupport" BO_ 945 1;
BA_ "GenMsgCycleTime" BO_ 945 100;
BA_ "GenMsgSendType" BO_ 1714 0;
BA_ "GenMsgILSupport" BO_ 1714 1;
BA_ "GenMsgCycleTime" BO_ 1714 1000;
BA_ "GenMsgSendType" BO_ 1520 0;
BA_ "GenMsgILSupport" BO_ 1520 1;
BA_ "GenMsgDelayTime" BO_ 1520 50;
BA_ "GenMsgCycleTime" BO_ 1520 200;
BA_ "GenMsgSendType" BO_ 1603 0;
BA_ "GenMsgILSupport" BO_ 1603 1;
BA_ "GenMsgCycleTime" BO_ 1603 1000;
BA_ "GenMsgSendType" BO_ 1627 0;
BA_ "GenMsgILSupport" BO_ 1627 1;
BA_ "GenMsgCycleTime" BO_ 1627 500;
BA_ "GenMsgSendType" BO_ 260 0;
BA_ "GenMsgPDUConstants" BO_ 260 "0x05,0x05,0x05,0x05,0x05,0x05,0x05,0x05,0x05,0x05,0x05,0x05,0x05,0x05,0x05,0x05";
BA_ "GenMsgILSupport" BO_ 260 1;
BA_ "GenMsgCycleTime" BO_ 260 20;
BA_ "GenMsgChkConstant" BO_ 260 5;
BA_ "GenMsgSendType" BO_ 781 0;
BA_ "GenMsgILSupport" BO_ 781 1;
BA_ "GenMsgDelayTime" BO_ 781 5;
BA_ "GenMsgCycleTime" BO_ 781 50;
BA_ "GenMsgSendType" BO_ 256 0;
BA_ "GenMsgPDUConstants" BO_ 256 "0xab,0xab,0xab,0xab,0xab,0xab,0xab,0xab,0xab,0xab,0xab,0xab,0xab,0xab,0xab,0xab";
BA_ "GenMsgILSupport" BO_ 256 1;
BA_ "GenMsgCycleTime" BO_ 256 20;
BA_ "GenMsgChkConstant" BO_ 256 171;
BA_ "GenMsgSendType" BO_ 257 0;
BA_ "GenMsgPDUConstants" BO_ 257 "0xaa,0xaa,0xaa,0xaa,0xaa,0xaa,0xaa,0xaa,0xaa,0xaa,0xaa,0xaa,0xaa,0xaa,0xaa,0xaa";
BA_ "GenMsgILSupport" BO_ 257 1;
BA_ "GenMsgCycleTime" BO_ 257 20;
BA_ "GenMsgChkConstant" BO_ 257 170;
BA_ "GenMsgSendType" BO_ 259 0;
BA_ "GenMsgPDUConstants" BO_ 259 "0x02,0x02,0x02,0x02,0x02,0x02,0x02,0x02,0x02,0x02,0x02,0x02,0x02,0x02,0x02,0x02";
BA_ "GenMsgILSupport" BO_ 259 1;
BA_ "GenMsgCycleTime" BO_ 259 20;
BA_ "GenMsgChkConstant" BO_ 259 2;
BA_ "GenMsgSendType" BO_ 776 0;
BA_ "GenMsgILSupport" BO_ 776 1;
BA_ "GenMsgCycleTime" BO_ 776 40;
BA_ "GenMsgSendType" BO_ 262 0;
BA_ "GenMsgPDUConstants" BO_ 262 "0x07,0x07,0x07,0x07,0x07,0x07,0x07,0x07,0x07,0x07,0x07,0x07,0x07,0x07,0x07,0x07";
BA_ "GenMsgILSupport" BO_ 262 1;
BA_ "GenMsgCycleTime" BO_ 262 20;
BA_ "GenMsgChkConstant" BO_ 262 7;
BA_ "GenMsgSendType" BO_ 132 0;
BA_ "GenMsgPDUConstants" BO_ 132 "0x84,0x84,0x84,0x84,0x84,0x84,0x84,0x84,0x84,0x84,0x84,0x84,0x84,0x84,0x84,0x84";
BA_ "GenMsgILSupport" BO_ 132 1;
BA_ "GenMsgCycleTime" BO_ 132 10;
BA_ "GenMsgChkConstant" BO_ 132 132;
BA_ "GenMsgSendType" BO_ 914 0;
BA_ "GenMsgPDUConstants" BO_ 914 "0x91,0x91,0x91,0x91,0x91,0x91,0x91,0x91,0x91,0x91,0x91,0x91,0x91,0x91,0x91,0x91";
BA_ "GenMsgILSupport" BO_ 914 1;
BA_ "GenMsgCycleTime" BO_ 914 80;
BA_ "GenMsgChkConstant" BO_ 914 145;
BA_ "GenMsgSendType" BO_ 169 0;
BA_ "GenMsgPDUConstants" BO_ 169 "0xa9,0xa9,0xa9,0xa9,0xa9,0xa9,0xa9,0xa9,0xa9,0xa9,0xa9,0xa9,0xa9,0xa9,0xa9,0xa9";
BA_ "GenMsgILSupport" BO_ 169 1;
BA_ "GenMsgCycleTime" BO_ 169 10;
BA_ "GenMsgChkConstant" BO_ 169 169;
BA_ "GenMsgSendType" BO_ 1623 0;
BA_ "GenMsgPDUConstants" BO_ 1623 "0x51,0x51,0x51,0x51,0x51,0x51,0x51,0x51,0x51,0x51,0x51,0x51,0x51,0x51,0x51,0x51";
BA_ "GenMsgILSupport" BO_ 1623 1;
BA_ "GenMsgCycleTime" BO_ 1623 1000;
BA_ "GenMsgChkConstant" BO_ 1623 81;
BA_ "GenMsgSendType" BO_ 924 0;
BA_ "GenMsgILSupport" BO_ 924 1;
BA_ "GenMsgDelayTime" BO_ 924 10;
BA_ "GenMsgCycleTime" BO_ 924 100;
BA_ "GenMsgSendType" BO_ 1604 0;
BA_ "GenMsgILSupport" BO_ 1604 1;
BA_ "GenMsgDelayTime" BO_ 1604 50;
BA_ "GenMsgCycleTime" BO_ 1604 500;
BA_ "GenMsgSendType" BO_ 130 0;
BA_ "GenMsgPDUConstants" BO_ 130 "0x82,0x82,0x82,0x82,0x82,0x82,0x82,0x82,0x82,0x82,0x82,0x82,0x82,0x82,0x82,0x82";
BA_ "GenMsgILSupport" BO_ 130 1;
BA_ "GenMsgCycleTime" BO_ 130 10;
BA_ "GenMsgChkConstant" BO_ 130 130;
BA_ "GenSigFuncType" SG_ 2617042433 CCP_Soundaktor_DTO_01_Data 9;
BA_ "GenSigSwitchedByIgnition" SG_ 901 CHA_01_CHK 0;
BA_ "GenSigFuncType" SG_ 901 CHA_01_CHK 3;
BA_ "GenSigSwitchedByIgnition" SG_ 901 CHA_01_BZ 0;
BA_ "GenSigSwitchedByIgnition" SG_ 901 CHA_Systemstatus 0;
BA_ "GenSigSendType" SG_ 901 CHA_Systemstatus 2;
BA_ "GenSigActiveRepetitions" SG_ 901 CHA_Systemstatus 5;
BA_ "GenSigSwitchedByIgnition" SG_ 901 CHA_Fahrer_Umschaltung 0;
BA_ "GenSigSendType" SG_ 901 CHA_Fahrer_Umschaltung 2;
BA_ "GenSigActiveRepetitions" SG_ 901 CHA_Fahrer_Umschaltung 5;
BA_ "GenSigSwitchedByIgnition" SG_ 901 CHA_Ziel_FahrPr_MO 0;
BA_ "GenSigSendType" SG_ 901 CHA_Ziel_FahrPr_MO 2;
BA_ "GenSigActiveRepetitions" SG_ 901 CHA_Ziel_FahrPr_MO 5;
BA_ "GenSigSwitchedByIgnition" SG_ 901 CHA_Ziel_FahrPr_GE 0;
BA_ "GenSigSendType" SG_ 901 CHA_Ziel_FahrPr_GE 2;
BA_ "GenSigActiveRepetitions" SG_ 901 CHA_Ziel_FahrPr_GE 5;
BA_ "GenSigSwitchedByIgnition" SG_ 901 CHA_Ziel_FahrPr_ST 0;
BA_ "GenSigSendType" SG_ 901 CHA_Ziel_FahrPr_ST 2;
BA_ "GenSigActiveRepetitions" SG_ 901 CHA_Ziel_FahrPr_ST 5;
BA_ "GenSigSwitchedByIgnition" SG_ 901 CHA_Ziel_FahrPr_SCU 0;
BA_ "GenSigSendType" SG_ 901 CHA_Ziel_FahrPr_SCU 2;
BA_ "GenSigActiveRepetitions" SG_ 901 CHA_Ziel_FahrPr_SCU 5;
BA_ "GenSigSwitchedByIgnition" SG_ 901 CHA_Ziel_FahrPr_DR 0;
BA_ "GenSigSendType" SG_ 901 CHA_Ziel_FahrPr_DR 2;
BA_ "GenSigActiveRepetitions" SG_ 901 CHA_Ziel_FahrPr_DR 5;
BA_ "GenSigSwitchedByIgnition" SG_ 901 CHA_Ziel_FahrPr_QS 0;
BA_ "GenSigSendType" SG_ 901 CHA_Ziel_FahrPr_QS 2;
BA_ "GenSigActiveRepetitions" SG_ 901 CHA_Ziel_FahrPr_QS 5;
BA_ "GenSigSwitchedByIgnition" SG_ 901 CHA_Ziel_FahrPr_AFS 0;
BA_ "GenSigSendType" SG_ 901 CHA_Ziel_FahrPr_AFS 2;
BA_ "GenSigActiveRepetitions" SG_ 901 CHA_Ziel_FahrPr_AFS 5;
BA_ "GenSigSwitchedByIgnition" SG_ 901 CHA_Ziel_FahrPr_RGS 0;
BA_ "GenSigSendType" SG_ 901 CHA_Ziel_FahrPr_RGS 2;
BA_ "GenSigActiveRepetitions" SG_ 901 CHA_Ziel_FahrPr_RGS 5;
BA_ "GenSigSwitchedByIgnition" SG_ 901 CHA_Ziel_FahrPr_EPS 0;
BA_ "GenSigSendType" SG_ 901 CHA_Ziel_FahrPr_EPS 2;
BA_ "GenSigActiveRepetitions" SG_ 901 CHA_Ziel_FahrPr_EPS 5;
BA_ "GenSigSwitchedByIgnition" SG_ 901 CHA_Ziel_FahrPr_ACC 0;
BA_ "GenSigSendType" SG_ 901 CHA_Ziel_FahrPr_ACC 2;
BA_ "GenSigActiveRepetitions" SG_ 901 CHA_Ziel_FahrPr_ACC 5;
BA_ "GenSigSwitchedByIgnition" SG_ 901 CHA_Ziel_FahrPr_SAK 0;
BA_ "GenSigSendType" SG_ 901 CHA_Ziel_FahrPr_SAK 2;
BA_ "GenSigActiveRepetitions" SG_ 901 CHA_Ziel_FahrPr_SAK 5;
BA_ "GenSigFuncType" SG_ 918 Daempfer_01_CHK 3;
BA_ "GenSigSendType" SG_ 918 Daempfer_01_CHK 0;
BA_ "GenSigFuncType" SG_ 918 Daempfer_01_BZ 1;
BA_ "GenSigSendType" SG_ 918 Daempfer_01_BZ 0;
BA_ "GenSigSendType" SG_ 918 DR_Systemstatus 0;
BA_ "GenSigSendType" SG_ 918 LF_Texte 0;
BA_ "GenSigSendType" SG_ 918 DR_Taster 0;
BA_ "GenSigSendType" SG_ 918 DR_Gelbe_Warnlampe 0;
BA_ "GenSigSendType" SG_ 918 DR_Daempferreg_Texte 0;
BA_ "GenSigSendType" SG_ 918 DR_Charisma_FahrPr 0;
BA_ "GenSigSendType" SG_ 918 DR_Charisma_Status 0;
BA_ "GenSigSendType" SG_ 918 DR_Charisma_Umschaltung 0;
BA_ "GenSigFuncType" SG_ 918 DR_Fahrzeugart 8;
BA_ "GenSigSendType" SG_ 918 DR_Fahrzeugart 0;
BA_ "GenSigSendType" SG_ 918 LF_Warnung_Prio1 0;
BA_ "GenSigSendType" SG_ 918 LF_Warnung_Prio2 0;
BA_ "GenSigSendType" SG_ 918 DR_DynAGL_Warnlampe 0;
BA_ "GenSigSendType" SG_ 918 DR_Rote_Warnlampe 0;
BA_ "Fehlerwert" SG_ 918 NI_Status 7;
BA_ "GenSigSendType" SG_ 918 NI_Status 0;
BA_ "GenSigSendType" SG_ 918 NR_Niveaufunktion_aktiv 0;
BA_ "GenSigSendType" SG_ 918 DR_KD_Fehler 0;
BA_ "GenSigSwitchedByIgnition" SG_ 945 DC_Verbrauch 0;
BA_ "GenSigSendType" SG_ 945 DC_Verbrauch 0;
BA_ "GenSigSwitchedByIgnition" SG_ 945 DC_Verbrauch_Ueberlauf 0;
BA_ "GenSigSendType" SG_ 945 DC_Verbrauch_Ueberlauf 0;
BA_ "Fehlerwert" SG_ 945 DC_HYB_iAktLV 1023;
BA_ "GenSigSwitchedByIgnition" SG_ 945 DC_HYB_iAktLV 0;
BA_ "GenSigStartValue" SG_ 945 DC_HYB_iAktLV 1022;
BA_ "GenSigSendType" SG_ 945 DC_HYB_iAktLV 0;
BA_ "Fehlerwert" SG_ 945 DC_HYB_iAktReserveLV 1023;
BA_ "GenSigSwitchedByIgnition" SG_ 945 DC_HYB_iAktReserveLV 0;
BA_ "GenSigStartValue" SG_ 945 DC_HYB_iAktReserveLV 1022;
BA_ "GenSigSendType" SG_ 945 DC_HYB_iAktReserveLV 0;
BA_ "Fehlerwert" SG_ 945 DC_HYB_uAktLV 255;
BA_ "GenSigSwitchedByIgnition" SG_ 945 DC_HYB_uAktLV 0;
BA_ "GenSigStartValue" SG_ 945 DC_HYB_uAktLV 254;
BA_ "GenSigSendType" SG_ 945 DC_HYB_uAktLV 0;
BA_ "GenSigSwitchedByIgnition" SG_ 945 DC_HYB_LangsRegelung 0;
BA_ "GenSigSendType" SG_ 945 DC_HYB_LangsRegelung 0;
BA_ "GenSigSwitchedByIgnition" SG_ 945 DC_HYB_Abregelung_Temperatur 0;
BA_ "GenSigSendType" SG_ 945 DC_HYB_Abregelung_Temperatur 0;
BA_ "GenSigSwitchedByIgnition" SG_ 945 DC_HYB_Fehler_RedLeistung 0;
BA_ "GenSigSendType" SG_ 945 DC_HYB_Fehler_RedLeistung 0;
BA_ "GenSigSwitchedByIgnition" SG_ 945 DC_HYB_Fehler_intern 0;
BA_ "GenSigSendType" SG_ 945 DC_HYB_Fehler_intern 0;
BA_ "GenSigSwitchedByIgnition" SG_ 945 DC_HYB_Fehler_Spannung 0;
BA_ "GenSigSendType" SG_ 945 DC_HYB_Fehler_Spannung 0;
BA_ "GenSigSwitchedByIgnition" SG_ 945 DC_TiefsetzBereit 0;
BA_ "GenSigSendType" SG_ 945 DC_TiefsetzBereit 0;
BA_ "Fehlerwert" SG_ 945 DC_HYB_Auslastungsgrad 255;
BA_ "GenSigStartValue" SG_ 945 DC_HYB_Auslastungsgrad 254;
BA_ "GenSigSendType" SG_ 945 DC_HYB_Auslastungsgrad 0;
BA_ "GenSigSwitchedByIgnition" SG_ 1714 DGN_Verlernzaehler 0;
BA_ "GenSigSendType" SG_ 1714 DGN_Verlernzaehler 0;
BA_ "Fehlerwert" SG_ 1714 KBI_Kilometerstand 1048575;
BA_ "GenSigSwitchedByIgnition" SG_ 1714 KBI_Kilometerstand 0;
BA_ "GenSigStartValue" SG_ 1714 KBI_Kilometerstand 1048574;
BA_ "GenSigSendType" SG_ 1714 KBI_Kilometerstand 0;
BA_ "GenSigSwitchedByIgnition" SG_ 1714 UH_Jahr 0;
BA_ "GenSigSendType" SG_ 1714 UH_Jahr 0;
BA_ "GenSigSwitchedByIgnition" SG_ 1714 UH_Monat 0;
BA_ "GenSigSendType" SG_ 1714 UH_Monat 0;
BA_ "GenSigSwitchedByIgnition" SG_ 1714 UH_Tag 0;
BA_ "GenSigSendType" SG_ 1714 UH_Tag 0;
BA_ "GenSigSwitchedByIgnition" SG_ 1714 UH_Stunde 0;
BA_ "GenSigSendType" SG_ 1714 UH_Stunde 0;
BA_ "GenSigSwitchedByIgnition" SG_ 1714 UH_Minute 0;
BA_ "GenSigSendType" SG_ 1714 UH_Minute 0;
BA_ "GenSigSwitchedByIgnition" SG_ 1714 UH_Sekunde 0;
BA_ "GenSigSendType" SG_ 1714 UH_Sekunde 0;
BA_ "GenSigSwitchedByIgnition" SG_ 1714 Kombi_02_alt 0;
BA_ "GenSigFuncType" SG_ 1714 Kombi_02_alt 5;
BA_ "GenSigStartValue" SG_ 1714 Kombi_02_alt 1;
BA_ "GenSigSendType" SG_ 1714 Kombi_02_alt 0;
BA_ "GenSigSwitchedByIgnition" SG_ 1714 Uhrzeit_01_alt 0;
BA_ "GenSigFuncType" SG_ 1714 Uhrzeit_01_alt 5;
BA_ "GenSigStartValue" SG_ 1714 Uhrzeit_01_alt 1;
BA_ "GenSigSendType" SG_ 1714 Uhrzeit_01_alt 0;
BA_ "GenSigMissingSourceValue" SG_ 1520 DI_KL_58d 255;
BA_ "Fehlerwert" SG_ 1520 DI_KL_58d 255;
BA_ "GenSigSwitchedByIgnition" SG_ 1520 DI_KL_58d 0;
BA_ "GenSigStartValue" SG_ 1520 DI_KL_58d 254;
BA_ "GenSigSendType" SG_ 1520 DI_KL_58d 3;
BA_ "Fehlerwert" SG_ 1520 DI_KL_58s 127;
BA_ "GenSigSwitchedByIgnition" SG_ 1520 DI_KL_58s 0;
BA_ "GenSigStartValue" SG_ 1520 DI_KL_58s 126;
BA_ "GenSigSendType" SG_ 1520 DI_KL_58s 3;
BA_ "Fehlerwert" SG_ 1520 DI_KL_58st 127;
BA_ "GenSigSwitchedByIgnition" SG_ 1520 DI_KL_58st 0;
BA_ "GenSigStartValue" SG_ 1520 DI_KL_58st 126;
BA_ "GenSigSendType" SG_ 1520 DI_KL_58st 3;
BA_ "GenSigSwitchedByIgnition" SG_ 1520 DI_Lichtsensorwert 0;
BA_ "GenSigSendType" SG_ 1520 DI_Lichtsensorwert 3;
BA_ "GenSigSwitchedByIgnition" SG_ 1603 KBI_Einheit_Datum 0;
BA_ "GenSigSendType" SG_ 1603 KBI_Einheit_Datum 0;
BA_ "GenSigSwitchedByIgnition" SG_ 1603 KBI_Einheit_Druck 0;
BA_ "GenSigSendType" SG_ 1603 KBI_Einheit_Druck 0;
BA_ "GenSigSwitchedByIgnition" SG_ 1603 KBI_Einheit_Streckenanz 0;
BA_ "GenSigSendType" SG_ 1603 KBI_Einheit_Streckenanz 0;
BA_ "GenSigSwitchedByIgnition" SG_ 1603 KBI_MFA_v_Einheit_02 0;
BA_ "GenSigSendType" SG_ 1603 KBI_MFA_v_Einheit_02 0;
BA_ "GenSigSwitchedByIgnition" SG_ 1603 KBI_Einheit_Temp 0;
BA_ "GenSigSendType" SG_ 1603 KBI_Einheit_Temp 0;
BA_ "GenSigSwitchedByIgnition" SG_ 1603 KBI_Einheit_Uhrzeit 0;
BA_ "GenSigSendType" SG_ 1603 KBI_Einheit_Uhrzeit 0;
BA_ "GenSigSwitchedByIgnition" SG_ 1603 KBI_Einheit_Verbrauch 0;
BA_ "GenSigSendType" SG_ 1603 KBI_Einheit_Verbrauch 0;
BA_ "GenSigSwitchedByIgnition" SG_ 1603 KBI_Einheit_Volumen 0;
BA_ "GenSigSendType" SG_ 1603 KBI_Einheit_Volumen 0;
BA_ "GenSigSwitchedByIgnition" SG_ 1603 KBI_Einheit_Verbrauch_elektr 0;
BA_ "GenSigSendType" SG_ 1603 KBI_Einheit_Verbrauch_elektr 0;
BA_ "GenSigSwitchedByIgnition" SG_ 1603 KBI_Einheit_Sprache 0;
BA_ "GenSigSendType" SG_ 1603 KBI_Einheit_Sprache 0;
BA_ "GenSigSwitchedByIgnition" SG_ 1627 EM_HYB_KD_Fehler 0;
BA_ "GenSigSendType" SG_ 1627 EM_HYB_KD_Fehler 0;
BA_ "GenSigSwitchedByIgnition" SG_ 260 EPB_01_CHK 0;
BA_ "GenSigFuncType" SG_ 260 EPB_01_CHK 3;
BA_ "GenSigSendType" SG_ 260 EPB_01_CHK 0;
BA_ "GenSigSwitchedByIgnition" SG_ 260 EPB_01_BZ 0;
BA_ "GenSigFuncType" SG_ 260 EPB_01_BZ 1;
BA_ "GenSigSendType" SG_ 260 EPB_01_BZ 0;
BA_ "GenSigSwitchedByIgnition" SG_ 260 EPB_QBit_Laengsbeschleunigung 0;
BA_ "GenSigStartValue" SG_ 260 EPB_QBit_Laengsbeschleunigung 1;
BA_ "GenSigSendType" SG_ 260 EPB_QBit_Laengsbeschleunigung 0;
BA_ "GenSigSwitchedByIgnition" SG_ 260 EPB_QBit_Pedalweg_Kuppl 0;
BA_ "GenSigStartValue" SG_ 260 EPB_QBit_Pedalweg_Kuppl 1;
BA_ "GenSigSendType" SG_ 260 EPB_QBit_Pedalweg_Kuppl 0;
BA_ "GenSigSwitchedByIgnition" SG_ 260 EPB_BCM2_Motor_Wakeup 0;
BA_ "GenSigSendType" SG_ 260 EPB_BCM2_Motor_Wakeup 0;
BA_ "GenSigSwitchedByIgnition" SG_ 260 EPB_Freig_Verzoeg_Anf 0;
BA_ "GenSigSendType" SG_ 260 EPB_Freig_Verzoeg_Anf 0;
BA_ "GenSigSwitchedByIgnition" SG_ 260 EPB_Verzoeg_Anf 0;
BA_ "GenSigStartValue" SG_ 260 EPB_Verzoeg_Anf 166;
BA_ "GenSigSendType" SG_ 260 EPB_Verzoeg_Anf 0;
BA_ "Fehlerwert" SG_ 260 EPB_Laengsbeschleunigung 255;
BA_ "GenSigSwitchedByIgnition" SG_ 260 EPB_Laengsbeschleunigung 0;
BA_ "GenSigSendType" SG_ 260 EPB_Laengsbeschleunigung 0;
BA_ "Fehlerwert" SG_ 260 EPB_Pedalweg_Kuppl 255;
BA_ "GenSigSwitchedByIgnition" SG_ 260 EPB_Pedalweg_Kuppl 0;
BA_ "GenSigSendType" SG_ 260 EPB_Pedalweg_Kuppl 0;
BA_ "GenSigSwitchedByIgnition" SG_ 260 HMS_Konsistenz_HVLM 0;
BA_ "GenSigSendType" SG_ 260 HMS_Konsistenz_HVLM 0;
BA_ "Fehlerwert" SG_ 260 HMS_Systemstatus 15;
BA_ "GenSigSwitchedByIgnition" SG_ 260 HMS_Systemstatus 0;
BA_ "GenSigStartValue" SG_ 260 HMS_Systemstatus 14;
BA_ "GenSigSendType" SG_ 260 HMS_Systemstatus 0;
BA_ "GenSigSwitchedByIgnition" SG_ 260 EPB_Anfahrwunsch_erkannt 0;
BA_ "GenSigSendType" SG_ 260 EPB_Anfahrwunsch_erkannt 0;
BA_ "GenSigSwitchedByIgnition" SG_ 260 EPB_DAA_Randbed_erf 0;
BA_ "GenSigSendType" SG_ 260 EPB_DAA_Randbed_erf 0;
BA_ "GenSigSwitchedByIgnition" SG_ 260 EPB_Fehlerstatus 0;
BA_ "GenSigSendType" SG_ 260 EPB_Fehlerstatus 0;
BA_ "Fehlerwert" SG_ 260 EPB_Schalterposition 3;
BA_ "GenSigSwitchedByIgnition" SG_ 260 EPB_Schalterposition 0;
BA_ "GenSigSendType" SG_ 260 EPB_Schalterposition 0;
BA_ "GenSigSwitchedByIgnition" SG_ 260 EPB_QBit_Schalterpos 0;
BA_ "GenSigStartValue" SG_ 260 EPB_QBit_Schalterpos 1;
BA_ "GenSigSendType" SG_ 260 EPB_QBit_Schalterpos 0;
BA_ "GenSigSwitchedByIgnition" SG_ 260 EPB_Konsistenz_ACC 0;
BA_ "GenSigSendType" SG_ 260 EPB_Konsistenz_ACC 0;
BA_ "Fehlerwert" SG_ 260 EPB_Spannkraft 31;
BA_ "GenSigSwitchedByIgnition" SG_ 260 EPB_Spannkraft 0;
BA_ "GenSigStartValue" SG_ 260 EPB_Spannkraft 30;
BA_ "GenSigSendType" SG_ 260 EPB_Spannkraft 0;
BA_ "GenSigSwitchedByIgnition" SG_ 260 EPB_Status 0;
BA_ "GenSigSendType" SG_ 260 EPB_Status 0;
BA_ "GenSigSwitchedByIgnition" SG_ 260 EPB_KD_Fehler 0;
BA_ "GenSigSendType" SG_ 260 EPB_KD_Fehler 0;
BA_ "GenSigSwitchedByIgnition" SG_ 781 EPB_Fehlerlampe_Gelb 0;
BA_ "GenSigSendType" SG_ 781 EPB_Fehlerlampe_Gelb 3;
BA_ "GenSigSwitchedByIgnition" SG_ 781 EPB_Fehlerlampe_BKL 0;
BA_ "GenSigSendType" SG_ 781 EPB_Fehlerlampe_BKL 3;
BA_ "GenSigSwitchedByIgnition" SG_ 781 EPB_Funktionslampe 0;
BA_ "GenSigSendType" SG_ 781 EPB_Funktionslampe 3;
BA_ "GenSigSwitchedByIgnition" SG_ 781 EPB_Texte 0;
BA_ "GenSigSendType" SG_ 781 EPB_Texte 3;
BA_ "GenSigSwitchedByIgnition" SG_ 781 EPB_Akustik 0;
BA_ "GenSigSendType" SG_ 781 EPB_Akustik 3;
BA_ "GenSigSwitchedByIgnition" SG_ 781 EPB_Autoholdlampe 0;
BA_ "GenSigSendType" SG_ 781 EPB_Autoholdlampe 3;
BA_ "GenSigSwitchedByIgnition" SG_ 781 EPB_Bremsbelag_Warn 0;
BA_ "GenSigSendType" SG_ 781 EPB_Bremsbelag_Warn 0;
BA_ "GenSigSwitchedByIgnition" SG_ 781 EPB_Fehlermeldungen 0;
BA_ "GenSigSendType" SG_ 781 EPB_Fehlermeldungen 0;
BA_ "GenSigSwitchedByIgnition" SG_ 256 ESP_01_CHK 0;
BA_ "GenSigFuncType" SG_ 256 ESP_01_CHK 4;
BA_ "GenSigSendType" SG_ 256 ESP_01_CHK 0;
BA_ "GenSigSwitchedByIgnition" SG_ 256 ESP_01_BZ 0;
BA_ "GenSigFuncType" SG_ 256 ESP_01_BZ 1;
BA_ "GenSigSendType" SG_ 256 ESP_01_BZ 0;
BA_ "Fehlerwert" SG_ 256 ASR_Moment_langsam 1023;
BA_ "GenSigSwitchedByIgnition" SG_ 256 ASR_Moment_langsam 0;
BA_ "GenSigStartValue" SG_ 256 ASR_Moment_langsam 1022;
BA_ "GenSigSendType" SG_ 256 ASR_Moment_langsam 0;
BA_ "Fehlerwert" SG_ 256 ASR_MSR_Moment_schnell 1023;
BA_ "GenSigSwitchedByIgnition" SG_ 256 ASR_MSR_Moment_schnell 0;
BA_ "GenSigStartValue" SG_ 256 ASR_MSR_Moment_schnell 1022;
BA_ "GenSigSendType" SG_ 256 ASR_MSR_Moment_schnell 0;
BA_ "GenSigMissingSourceValue" SG_ 256 ESP_v_Signal 65534;
BA_ "Fehlerwert" SG_ 256 ESP_v_Signal 65535;
BA_ "GenSigSwitchedByIgnition" SG_ 256 ESP_v_Signal 0;
BA_ "GenSigStartValue" SG_ 256 ESP_v_Signal 65534;
BA_ "GenSigSendType" SG_ 256 ESP_v_Signal 0;
BA_ "GenSigSwitchedByIgnition" SG_ 256 ASR_Tastung_passiv 0;
BA_ "GenSigSendType" SG_ 256 ASR_Tastung_passiv 0;
BA_ "GenSigSwitchedByIgnition" SG_ 256 ESP_Tastung_passiv 0;
BA_ "GenSigSendType" SG_ 256 ESP_Tastung_passiv 0;
BA_ "GenSigSwitchedByIgnition" SG_ 256 ESP_Systemstatus 0;
BA_ "GenSigSendType" SG_ 256 ESP_Systemstatus 0;
BA_ "GenSigSwitchedByIgnition" SG_ 256 ASR_Schalteingriff 0;
BA_ "GenSigSendType" SG_ 256 ASR_Schalteingriff 0;
BA_ "GenSigSwitchedByIgnition" SG_ 256 OBD_Schlechtweg 0;
BA_ "GenSigSendType" SG_ 256 OBD_Schlechtweg 0;
BA_ "GenSigSwitchedByIgnition" SG_ 256 OBD_QBit_Schlechtweg 0;
BA_ "GenSigStartValue" SG_ 256 OBD_QBit_Schlechtweg 1;
BA_ "GenSigSendType" SG_ 256 OBD_QBit_Schlechtweg 0;
BA_ "GenSigSwitchedByIgnition" SG_ 256 ESP_QBit_v_Signal 0;
BA_ "GenSigStartValue" SG_ 256 ESP_QBit_v_Signal 1;
BA_ "GenSigSendType" SG_ 256 ESP_QBit_v_Signal 0;
BA_ "GenSigSwitchedByIgnition" SG_ 256 ABS_Bremsung 0;
BA_ "GenSigSendType" SG_ 256 ABS_Bremsung 0;
BA_ "GenSigSwitchedByIgnition" SG_ 256 ASR_Anf 0;
BA_ "GenSigSendType" SG_ 256 ASR_Anf 0;
BA_ "GenSigSwitchedByIgnition" SG_ 256 MSR_Anf 0;
BA_ "GenSigSendType" SG_ 256 MSR_Anf 0;
BA_ "GenSigSwitchedByIgnition" SG_ 256 EBV_Eingriff 0;
BA_ "GenSigSendType" SG_ 256 EBV_Eingriff 0;
BA_ "GenSigSwitchedByIgnition" SG_ 256 EDS_Eingriff 0;
BA_ "GenSigSendType" SG_ 256 EDS_Eingriff 0;
BA_ "GenSigSwitchedByIgnition" SG_ 256 ESP_Eingriff 0;
BA_ "GenSigSendType" SG_ 256 ESP_Eingriff 0;
BA_ "GenSigSwitchedByIgnition" SG_ 256 ESP_ASP 0;
BA_ "GenSigSendType" SG_ 256 ESP_ASP 0;
BA_ "GenSigSwitchedByIgnition" SG_ 256 ESP_KD_Fehler 0;
BA_ "GenSigSendType" SG_ 256 ESP_KD_Fehler 0;
BA_ "GenSigSwitchedByIgnition" SG_ 257 ESP_02_CHK 0;
BA_ "GenSigFuncType" SG_ 257 ESP_02_CHK 4;
BA_ "GenSigSendType" SG_ 257 ESP_02_CHK 0;
BA_ "GenSigSwitchedByIgnition" SG_ 257 ESP_02_BZ 0;
BA_ "GenSigFuncType" SG_ 257 ESP_02_BZ 1;
BA_ "GenSigSendType" SG_ 257 ESP_02_BZ 0;
BA_ "GenSigSwitchedByIgnition" SG_ 257 ESP_QBit_Gierrate 0;
BA_ "GenSigStartValue" SG_ 257 ESP_QBit_Gierrate 1;
BA_ "GenSigSendType" SG_ 257 ESP_QBit_Gierrate 0;
BA_ "GenSigSwitchedByIgnition" SG_ 257 ESP_QBit_Laengsbeschl 0;
BA_ "GenSigStartValue" SG_ 257 ESP_QBit_Laengsbeschl 1;
BA_ "GenSigSendType" SG_ 257 ESP_QBit_Laengsbeschl 0;
BA_ "GenSigSwitchedByIgnition" SG_ 257 ESP_QBit_Querb 0;
BA_ "GenSigStartValue" SG_ 257 ESP_QBit_Querb 1;
BA_ "GenSigSendType" SG_ 257 ESP_QBit_Querb 0;
BA_ "GenSigSwitchedByIgnition" SG_ 257 ESP_Stillstandsflag 0;
BA_ "GenSigSendType" SG_ 257 ESP_Stillstandsflag 0;
BA_ "Fehlerwert" SG_ 257 ESP_Querbeschleunigung 255;
BA_ "GenSigSwitchedByIgnition" SG_ 257 ESP_Querbeschleunigung 0;
BA_ "GenSigStartValue" SG_ 257 ESP_Querbeschleunigung 127;
BA_ "GenSigSendType" SG_ 257 ESP_Querbeschleunigung 0;
BA_ "Fehlerwert" SG_ 257 ESP_Laengsbeschl 1023;
BA_ "GenSigSwitchedByIgnition" SG_ 257 ESP_Laengsbeschl 0;
BA_ "GenSigStartValue" SG_ 257 ESP_Laengsbeschl 512;
BA_ "GenSigSendType" SG_ 257 ESP_Laengsbeschl 0;
BA_ "Fehlerwert" SG_ 257 ESP_Verteil_Wankmom 31;
BA_ "GenSigSwitchedByIgnition" SG_ 257 ESP_Verteil_Wankmom 0;
BA_ "GenSigStartValue" SG_ 257 ESP_Verteil_Wankmom 30;
BA_ "GenSigSendType" SG_ 257 ESP_Verteil_Wankmom 0;
BA_ "GenSigSwitchedByIgnition" SG_ 257 ESP_QBit_Anf_Vert_Wank 0;
BA_ "GenSigStartValue" SG_ 257 ESP_QBit_Anf_Vert_Wank 1;
BA_ "GenSigSendType" SG_ 257 ESP_QBit_Anf_Vert_Wank 0;
BA_ "Fehlerwert" SG_ 257 ESP_Gierrate 16383;
BA_ "GenSigSwitchedByIgnition" SG_ 257 ESP_Gierrate 0;
BA_ "GenSigSendType" SG_ 257 ESP_Gierrate 0;
BA_ "GenSigSwitchedByIgnition" SG_ 257 ESP_VZ_Gierrate 0;
BA_ "GenSigSendType" SG_ 257 ESP_VZ_Gierrate 0;
BA_ "GenSigSwitchedByIgnition" SG_ 257 ESP_Notbremsanzeige 0;
BA_ "GenSigSendType" SG_ 257 ESP_Notbremsanzeige 0;
BA_ "GenSigSwitchedByIgnition" SG_ 257 ESP_SpannungsAnf 0;
BA_ "GenSigSendType" SG_ 257 ESP_SpannungsAnf 0;
BA_ "GenSigSwitchedByIgnition" SG_ 257 ESP_PLA_Abbruch 0;
BA_ "GenSigSendType" SG_ 257 ESP_PLA_Abbruch 0;
BA_ "GenSigSwitchedByIgnition" SG_ 257 ESP_Status_ESP_PLA 0;
BA_ "GenSigSendType" SG_ 257 ESP_Status_ESP_PLA 0;
BA_ "GenSigSwitchedByIgnition" SG_ 259 ESP_03_CHK 0;
BA_ "GenSigFuncType" SG_ 259 ESP_03_CHK 3;
BA_ "GenSigSendType" SG_ 259 ESP_03_CHK 0;
BA_ "GenSigSwitchedByIgnition" SG_ 259 ESP_03_BZ 0;
BA_ "GenSigFuncType" SG_ 259 ESP_03_BZ 1;
BA_ "GenSigSendType" SG_ 259 ESP_03_BZ 0;
BA_ "GenSigSwitchedByIgnition" SG_ 259 ESP_VL_FR 0;
BA_ "GenSigSendType" SG_ 259 ESP_VL_FR 0;
BA_ "GenSigSwitchedByIgnition" SG_ 259 ESP_VR_FR 0;
BA_ "GenSigSendType" SG_ 259 ESP_VR_FR 0;
BA_ "GenSigSwitchedByIgnition" SG_ 259 ESP_HL_FR 0;
BA_ "GenSigSendType" SG_ 259 ESP_HL_FR 0;
BA_ "GenSigSwitchedByIgnition" SG_ 259 ESP_HR_FR 0;
BA_ "GenSigSendType" SG_ 259 ESP_HR_FR 0;
BA_ "Fehlerwert" SG_ 259 ESP_VL_Radgeschw 4095;
BA_ "GenSigSwitchedByIgnition" SG_ 259 ESP_VL_Radgeschw 0;
BA_ "GenSigStartValue" SG_ 259 ESP_VL_Radgeschw 4094;
BA_ "GenSigSendType" SG_ 259 ESP_VL_Radgeschw 0;
BA_ "Fehlerwert" SG_ 259 ESP_VR_Radgeschw 4095;
BA_ "GenSigSwitchedByIgnition" SG_ 259 ESP_VR_Radgeschw 0;
BA_ "GenSigStartValue" SG_ 259 ESP_VR_Radgeschw 4094;
BA_ "GenSigSendType" SG_ 259 ESP_VR_Radgeschw 0;
BA_ "Fehlerwert" SG_ 259 ESP_HL_Radgeschw 4095;
BA_ "GenSigSwitchedByIgnition" SG_ 259 ESP_HL_Radgeschw 0;
BA_ "GenSigStartValue" SG_ 259 ESP_HL_Radgeschw 4094;
BA_ "GenSigSendType" SG_ 259 ESP_HL_Radgeschw 0;
BA_ "Fehlerwert" SG_ 259 ESP_HR_Radgeschw 4095;
BA_ "GenSigSwitchedByIgnition" SG_ 259 ESP_HR_Radgeschw 0;
BA_ "GenSigStartValue" SG_ 259 ESP_HR_Radgeschw 4094;
BA_ "GenSigSendType" SG_ 259 ESP_HR_Radgeschw 0;
BA_ "GenSigSwitchedByIgnition" SG_ 776 ESP_Meldungen 0;
BA_ "GenSigSendType" SG_ 776 ESP_Meldungen 0;
BA_ "GenSigSwitchedByIgnition" SG_ 776 ESP_HDC_FktLampe 0;
BA_ "GenSigSendType" SG_ 776 ESP_HDC_FktLampe 0;
BA_ "GenSigSwitchedByIgnition" SG_ 776 ESP_Lampe 0;
BA_ "GenSigStartValue" SG_ 776 ESP_Lampe 1;
BA_ "GenSigSendType" SG_ 776 ESP_Lampe 0;
BA_ "GenSigSwitchedByIgnition" SG_ 776 ABS_Lampe 0;
BA_ "GenSigStartValue" SG_ 776 ABS_Lampe 1;
BA_ "GenSigSendType" SG_ 776 ABS_Lampe 0;
BA_ "GenSigSwitchedByIgnition" SG_ 776 BK_Lampe 0;
BA_ "GenSigStartValue" SG_ 776 BK_Lampe 1;
BA_ "GenSigSendType" SG_ 776 BK_Lampe 0;
BA_ "GenSigSwitchedByIgnition" SG_ 776 ESP_Akustik 0;
BA_ "GenSigSendType" SG_ 776 ESP_Akustik 0;
BA_ "GenSigSwitchedByIgnition" SG_ 776 ESP_Diagnose 0;
BA_ "GenSigSendType" SG_ 776 ESP_Diagnose 0;
BA_ "GenSigSwitchedByIgnition" SG_ 776 ESP_Textanzeigen_02 0;
BA_ "GenSigSendType" SG_ 776 ESP_Textanzeigen_02 0;
BA_ "GenSigSwitchedByIgnition" SG_ 776 ESP_Off_Lampe 0;
BA_ "GenSigSendType" SG_ 776 ESP_Off_Lampe 0;
BA_ "Fehlerwert" SG_ 776 ESP_m_Raddrehz 32767;
BA_ "GenSigSwitchedByIgnition" SG_ 776 ESP_m_Raddrehz 0;
BA_ "GenSigStartValue" SG_ 776 ESP_m_Raddrehz 32766;
BA_ "GenSigSendType" SG_ 776 ESP_m_Raddrehz 0;
BA_ "GenSigSwitchedByIgnition" SG_ 776 ESP_ASR_Lampe 0;
BA_ "GenSigSendType" SG_ 776 ESP_ASR_Lampe 0;
BA_ "GenSigSwitchedByIgnition" SG_ 776 ESP_Wegimp_VA 0;
BA_ "GenSigSendType" SG_ 776 ESP_Wegimp_VA 0;
BA_ "GenSigSwitchedByIgnition" SG_ 776 ESP_Fehlerstatus_Wegimp 0;
BA_ "GenSigSendType" SG_ 776 ESP_Fehlerstatus_Wegimp 0;
BA_ "GenSigSwitchedByIgnition" SG_ 776 ESP_Wegimp_Ueberlauf 0;
BA_ "GenSigSendType" SG_ 776 ESP_Wegimp_Ueberlauf 0;
BA_ "GenSigSwitchedByIgnition" SG_ 776 ESP_QBit_Wegimp_VA 0;
BA_ "GenSigStartValue" SG_ 776 ESP_QBit_Wegimp_VA 1;
BA_ "GenSigSendType" SG_ 776 ESP_QBit_Wegimp_VA 0;
BA_ "GenSigSwitchedByIgnition" SG_ 776 ESP_Displaywarnungen 0;
BA_ "GenSigSendType" SG_ 776 ESP_Displaywarnungen 0;
BA_ "Fehlerwert" SG_ 776 ESP_HDC_Regelgeschw 127;
BA_ "GenSigSwitchedByIgnition" SG_ 776 ESP_HDC_Regelgeschw 0;
BA_ "GenSigStartValue" SG_ 776 ESP_HDC_Regelgeschw 126;
BA_ "GenSigSendType" SG_ 776 ESP_HDC_Regelgeschw 0;
BA_ "GenSigSwitchedByIgnition" SG_ 776 ESP_BKV_Warnung 0;
BA_ "GenSigSendType" SG_ 776 ESP_BKV_Warnung 0;
BA_ "GenSigSwitchedByIgnition" SG_ 776 ESP_Zaehnezahl 0;
BA_ "GenSigFuncType" SG_ 776 ESP_Zaehnezahl 8;
BA_ "GenSigSendType" SG_ 776 ESP_Zaehnezahl 0;
BA_ "GenSigSwitchedByIgnition" SG_ 262 ESP_05_CHK 0;
BA_ "GenSigFuncType" SG_ 262 ESP_05_CHK 3;
BA_ "GenSigSendType" SG_ 262 ESP_05_CHK 0;
BA_ "GenSigSwitchedByIgnition" SG_ 262 ESP_05_BZ 0;
BA_ "GenSigFuncType" SG_ 262 ESP_05_BZ 1;
BA_ "GenSigSendType" SG_ 262 ESP_05_BZ 0;
BA_ "GenSigSwitchedByIgnition" SG_ 262 ESP_QBit_Bremsdruck 0;
BA_ "GenSigStartValue" SG_ 262 ESP_QBit_Bremsdruck 1;
BA_ "GenSigSendType" SG_ 262 ESP_QBit_Bremsdruck 0;
BA_ "GenSigSwitchedByIgnition" SG_ 262 ESP_QBit_Fahrer_bremst 0;
BA_ "GenSigStartValue" SG_ 262 ESP_QBit_Fahrer_bremst 1;
BA_ "GenSigSendType" SG_ 262 ESP_QBit_Fahrer_bremst 0;
BA_ "GenSigSwitchedByIgnition" SG_ 262 ESP_Schwelle_Unterdruck 0;
BA_ "GenSigSendType" SG_ 262 ESP_Schwelle_Unterdruck 0;
BA_ "Fehlerwert" SG_ 262 ESP_Bremsdruck 1023;
BA_ "GenSigSwitchedByIgnition" SG_ 262 ESP_Bremsdruck 0;
BA_ "GenSigStartValue" SG_ 262 ESP_Bremsdruck 100;
BA_ "GenSigSendType" SG_ 262 ESP_Bremsdruck 0;
BA_ "GenSigSwitchedByIgnition" SG_ 262 ESP_Fahrer_bremst 0;
BA_ "GenSigSendType" SG_ 262 ESP_Fahrer_bremst 0;
BA_ "GenSigSwitchedByIgnition" SG_ 262 ESP_Verz_TSK_aktiv 0;
BA_ "GenSigSendType" SG_ 262 ESP_Verz_TSK_aktiv 0;
BA_ "GenSigSwitchedByIgnition" SG_ 262 ESP_Lenkeingriff_ADS 0;
BA_ "GenSigSendType" SG_ 262 ESP_Lenkeingriff_ADS 0;
BA_ "GenSigSwitchedByIgnition" SG_ 262 ESP_Konsistenz_TSK 0;
BA_ "GenSigSendType" SG_ 262 ESP_Konsistenz_TSK 0;
BA_ "GenSigSwitchedByIgnition" SG_ 262 ESP_Bremsruck_AWV2 0;
BA_ "GenSigSendType" SG_ 262 ESP_Bremsruck_AWV2 0;
BA_ "GenSigSwitchedByIgnition" SG_ 262 ESP_Konsistenz_AWV2 0;
BA_ "GenSigSendType" SG_ 262 ESP_Konsistenz_AWV2 0;
BA_ "GenSigSwitchedByIgnition" SG_ 262 ECD_Fehler 0;
BA_ "GenSigSendType" SG_ 262 ECD_Fehler 0;
BA_ "GenSigSwitchedByIgnition" SG_ 262 ECD_nicht_verfuegbar 0;
BA_ "GenSigStartValue" SG_ 262 ECD_nicht_verfuegbar 1;
BA_ "GenSigSendType" SG_ 262 ECD_nicht_verfuegbar 0;
BA_ "GenSigSwitchedByIgnition" SG_ 262 ESP_Status_Bremsentemp 0;
BA_ "GenSigSendType" SG_ 262 ESP_Status_Bremsentemp 0;
BA_ "GenSigSwitchedByIgnition" SG_ 262 ESP_Autohold_Standby 0;
BA_ "GenSigSendType" SG_ 262 ESP_Autohold_Standby 0;
BA_ "GenSigSwitchedByIgnition" SG_ 262 ESP_HDC_Standby 0;
BA_ "GenSigSendType" SG_ 262 ESP_HDC_Standby 0;
BA_ "GenSigSwitchedByIgnition" SG_ 262 ESP_HBA_aktiv 0;
BA_ "GenSigSendType" SG_ 262 ESP_HBA_aktiv 0;
BA_ "GenSigSwitchedByIgnition" SG_ 262 ESP_Prefill_ausgeloest 0;
BA_ "GenSigSendType" SG_ 262 ESP_Prefill_ausgeloest 0;
BA_ "GenSigSwitchedByIgnition" SG_ 262 ESP_Rueckwaertsfahrt_erkannt 0;
BA_ "GenSigSendType" SG_ 262 ESP_Rueckwaertsfahrt_erkannt 0;
BA_ "GenSigSwitchedByIgnition" SG_ 262 ESP_Status_Anfahrhilfe 0;
BA_ "GenSigSendType" SG_ 262 ESP_Status_Anfahrhilfe 0;
BA_ "GenSigSwitchedByIgnition" SG_ 262 ESP_HDC_aktiv 0;
BA_ "GenSigSendType" SG_ 262 ESP_HDC_aktiv 0;
BA_ "GenSigSwitchedByIgnition" SG_ 262 ESP_StartStopp_Info 0;
BA_ "GenSigSendType" SG_ 262 ESP_StartStopp_Info 0;
BA_ "GenSigSwitchedByIgnition" SG_ 262 ESP_Eingr_HL 0;
BA_ "GenSigSendType" SG_ 262 ESP_Eingr_HL 0;
BA_ "GenSigSwitchedByIgnition" SG_ 262 ESP_Eingr_HR 0;
BA_ "GenSigSendType" SG_ 262 ESP_Eingr_HR 0;
BA_ "GenSigSwitchedByIgnition" SG_ 262 ESP_Eingr_VL 0;
BA_ "GenSigSendType" SG_ 262 ESP_Eingr_VL 0;
BA_ "GenSigSwitchedByIgnition" SG_ 262 ESP_Eingr_VR 0;
BA_ "GenSigSendType" SG_ 262 ESP_Eingr_VR 0;
BA_ "Fehlerwert" SG_ 262 ESP_BKV_Unterdruck 255;
BA_ "GenSigSwitchedByIgnition" SG_ 262 ESP_BKV_Unterdruck 0;
BA_ "GenSigStartValue" SG_ 262 ESP_BKV_Unterdruck 254;
BA_ "GenSigSendType" SG_ 262 ESP_BKV_Unterdruck 0;
BA_ "GenSigSwitchedByIgnition" SG_ 262 ESP_Autohold_aktiv 0;
BA_ "GenSigSendType" SG_ 262 ESP_Autohold_aktiv 0;
BA_ "GenSigSwitchedByIgnition" SG_ 262 ESP_FStatus_Anfahrhilfe 0;
BA_ "GenSigSendType" SG_ 262 ESP_FStatus_Anfahrhilfe 0;
BA_ "GenSigSwitchedByIgnition" SG_ 262 ESP_Verz_EPB_aktiv 0;
BA_ "GenSigSendType" SG_ 262 ESP_Verz_EPB_aktiv 0;
BA_ "GenSigSwitchedByIgnition" SG_ 262 ECD_Bremslicht 0;
BA_ "GenSigSendType" SG_ 262 ECD_Bremslicht 0;
BA_ "GenSigSwitchedByIgnition" SG_ 262 ESP_Verzoeg_EPB_verf 0;
BA_ "GenSigSendType" SG_ 262 ESP_Verzoeg_EPB_verf 0;
BA_ "GenSigSwitchedByIgnition" SG_ 262 ESP_Status_Bremsdruck 0;
BA_ "GenSigSendType" SG_ 262 ESP_Status_Bremsdruck 0;
BA_ "GenSigSwitchedByIgnition" SG_ 262 ESP_Anforderung_EPB 0;
BA_ "GenSigSendType" SG_ 262 ESP_Anforderung_EPB 0;
BA_ "GenSigSwitchedByIgnition" SG_ 132 ESP_06_CHK 0;
BA_ "GenSigFuncType" SG_ 132 ESP_06_CHK 3;
BA_ "GenSigSendType" SG_ 132 ESP_06_CHK 0;
BA_ "GenSigSwitchedByIgnition" SG_ 132 ESP_06_BZ 0;
BA_ "GenSigFuncType" SG_ 132 ESP_06_BZ 1;
BA_ "GenSigSendType" SG_ 132 ESP_06_BZ 0;
BA_ "GenSigSwitchedByIgnition" SG_ 132 ESP_06_KD_Fehler 0;
BA_ "GenSigSendType" SG_ 132 ESP_06_KD_Fehler 0;
BA_ "GenSigSwitchedByIgnition" SG_ 132 ESP_Teilsollwinkel 0;
BA_ "GenSigSendType" SG_ 132 ESP_Teilsollwinkel 0;
BA_ "GenSigSwitchedByIgnition" SG_ 132 ESP_VZ_Teilsollwinkel 0;
BA_ "GenSigSendType" SG_ 132 ESP_VZ_Teilsollwinkel 0;
BA_ "GenSigSwitchedByIgnition" SG_ 132 ESP_Winkeleingriff 0;
BA_ "GenSigSendType" SG_ 132 ESP_Winkeleingriff 0;
BA_ "GenSigSwitchedByIgnition" SG_ 132 ESP_Status_ADS 0;
BA_ "GenSigStartValue" SG_ 132 ESP_Status_ADS 1;
BA_ "GenSigSendType" SG_ 132 ESP_Status_ADS 0;
BA_ "Fehlerwert" SG_ 132 ESP_v_ref 4095;
BA_ "GenSigSwitchedByIgnition" SG_ 132 ESP_v_ref 0;
BA_ "GenSigStartValue" SG_ 132 ESP_v_ref 4094;
BA_ "GenSigSendType" SG_ 132 ESP_v_ref 0;
BA_ "Fehlerwert" SG_ 132 ESP_Monitoring_Gierrate 7;
BA_ "GenSigSwitchedByIgnition" SG_ 132 ESP_Monitoring_Gierrate 0;
BA_ "GenSigStartValue" SG_ 132 ESP_Monitoring_Gierrate 6;
BA_ "GenSigSendType" SG_ 132 ESP_Monitoring_Gierrate 0;
BA_ "Fehlerwert" SG_ 132 ESP_Monitoring_Laengsb 7;
BA_ "GenSigSwitchedByIgnition" SG_ 132 ESP_Monitoring_Laengsb 0;
BA_ "GenSigStartValue" SG_ 132 ESP_Monitoring_Laengsb 6;
BA_ "GenSigSendType" SG_ 132 ESP_Monitoring_Laengsb 0;
BA_ "Fehlerwert" SG_ 132 ESP_Monitoring_Lenkwinkel 7;
BA_ "GenSigSwitchedByIgnition" SG_ 132 ESP_Monitoring_Lenkwinkel 0;
BA_ "GenSigStartValue" SG_ 132 ESP_Monitoring_Lenkwinkel 6;
BA_ "GenSigSendType" SG_ 132 ESP_Monitoring_Lenkwinkel 0;
BA_ "Fehlerwert" SG_ 132 ESP_Monitoring_Querb 7;
BA_ "GenSigSwitchedByIgnition" SG_ 132 ESP_Monitoring_Querb 0;
BA_ "GenSigStartValue" SG_ 132 ESP_Monitoring_Querb 6;
BA_ "GenSigSendType" SG_ 132 ESP_Monitoring_Querb 0;
BA_ "GenSigSwitchedByIgnition" SG_ 132 ESP_06_CRC 0;
BA_ "GenSigFuncType" SG_ 132 ESP_06_CRC 2;
BA_ "GenSigSendType" SG_ 132 ESP_06_CRC 0;
BA_ "GenSigSwitchedByIgnition" SG_ 914 ESP_07_CHK 0;
BA_ "GenSigFuncType" SG_ 914 ESP_07_CHK 3;
BA_ "GenSigSendType" SG_ 914 ESP_07_CHK 0;
BA_ "GenSigSwitchedByIgnition" SG_ 914 ESP_07_BZ 0;
BA_ "GenSigFuncType" SG_ 914 ESP_07_BZ 1;
BA_ "GenSigSendType" SG_ 914 ESP_07_BZ 0;
BA_ "GenSigSwitchedByIgnition" SG_ 914 ESP_ACC_LDE 0;
BA_ "GenSigSendType" SG_ 914 ESP_ACC_LDE 0;
BA_ "GenSigSwitchedByIgnition" SG_ 914 ESP_Quattro_Antrieb 0;
BA_ "GenSigFuncType" SG_ 914 ESP_Quattro_Antrieb 8;
BA_ "GenSigSendType" SG_ 914 ESP_Quattro_Antrieb 0;
BA_ "GenSigSwitchedByIgnition" SG_ 914 ESP_Codierung_ADS 0;
BA_ "GenSigFuncType" SG_ 914 ESP_Codierung_ADS 8;
BA_ "GenSigSendType" SG_ 914 ESP_Codierung_ADS 0;
BA_ "Fehlerwert" SG_ 914 ESP_RTA_HL 255;
BA_ "GenSigSwitchedByIgnition" SG_ 914 ESP_RTA_HL 0;
BA_ "GenSigStartValue" SG_ 914 ESP_RTA_HL 254;
BA_ "GenSigSendType" SG_ 914 ESP_RTA_HL 0;
BA_ "Fehlerwert" SG_ 914 ESP_RTA_HR 255;
BA_ "GenSigSwitchedByIgnition" SG_ 914 ESP_RTA_HR 0;
BA_ "GenSigStartValue" SG_ 914 ESP_RTA_HR 254;
BA_ "GenSigSendType" SG_ 914 ESP_RTA_HR 0;
BA_ "Fehlerwert" SG_ 914 ESP_RTA_VR 255;
BA_ "GenSigSwitchedByIgnition" SG_ 914 ESP_RTA_VR 0;
BA_ "GenSigStartValue" SG_ 914 ESP_RTA_VR 254;
BA_ "GenSigSendType" SG_ 914 ESP_RTA_VR 0;
BA_ "GenSigSwitchedByIgnition" SG_ 914 OBD_Fehler_Radsensor_HL 0;
BA_ "GenSigSendType" SG_ 914 OBD_Fehler_Radsensor_HL 0;
BA_ "GenSigSwitchedByIgnition" SG_ 914 OBD_Fehler_Radsensor_HR 0;
BA_ "GenSigSendType" SG_ 914 OBD_Fehler_Radsensor_HR 0;
BA_ "GenSigSwitchedByIgnition" SG_ 914 OBD_Fehler_Radsensor_VL 0;
BA_ "GenSigSendType" SG_ 914 OBD_Fehler_Radsensor_VL 0;
BA_ "GenSigSwitchedByIgnition" SG_ 914 OBD_Fehler_Radsensor_VR 0;
BA_ "GenSigSendType" SG_ 914 OBD_Fehler_Radsensor_VR 0;
BA_ "GenSigSwitchedByIgnition" SG_ 914 ESP_Qualifizierung_Antriebsart 0;
BA_ "GenSigFuncType" SG_ 914 ESP_Qualifizierung_Antriebsart 8;
BA_ "GenSigSendType" SG_ 914 ESP_Qualifizierung_Antriebsart 0;
BA_ "GenSigSwitchedByIgnition" SG_ 914 ESP_Offroad_Modus 0;
BA_ "GenSigSendType" SG_ 914 ESP_Offroad_Modus 0;
BA_ "GenSigSwitchedByIgnition" SG_ 914 ESP_MKB_ausloesbar 0;
BA_ "GenSigSendType" SG_ 914 ESP_MKB_ausloesbar 0;
BA_ "GenSigSwitchedByIgnition" SG_ 914 ESP_Stat_FallBack_eBKV 0;
BA_ "GenSigSendType" SG_ 914 ESP_Stat_FallBack_eBKV 0;
BA_ "GenSigSwitchedByIgnition" SG_ 914 ESP_CM_Variante 0;
BA_ "GenSigSendType" SG_ 914 ESP_CM_Variante 0;
BA_ "GenSigSwitchedByIgnition" SG_ 914 ESP_OBD_Status 0;
BA_ "GenSigSendType" SG_ 914 ESP_OBD_Status 0;
BA_ "GenSigSwitchedByIgnition" SG_ 914 ESP_Rollenmodus_Deaktivieren 0;
BA_ "GenSigSendType" SG_ 914 ESP_Rollenmodus_Deaktivieren 0;
BA_ "GenSigSwitchedByIgnition" SG_ 914 ESP_nachtr_Stopp_Anf 0;
BA_ "GenSigSendType" SG_ 914 ESP_nachtr_Stopp_Anf 0;
BA_ "GenSigSwitchedByIgnition" SG_ 169 ESP_16_CRC 0;
BA_ "GenSigFuncType" SG_ 169 ESP_16_CRC 2;
BA_ "GenSigSendType" SG_ 169 ESP_16_CRC 0;
BA_ "GenSigSwitchedByIgnition" SG_ 169 ESP_16_BZ 0;
BA_ "GenSigFuncType" SG_ 169 ESP_16_BZ 1;
BA_ "GenSigSendType" SG_ 169 ESP_16_BZ 0;
BA_ "Fehlerwert" SG_ 169 ESP_Eingriffsmoment 1023;
BA_ "GenSigSwitchedByIgnition" SG_ 169 ESP_Eingriffsmoment 0;
BA_ "GenSigStartValue" SG_ 169 ESP_Eingriffsmoment 1022;
BA_ "GenSigSendType" SG_ 169 ESP_Eingriffsmoment 0;
BA_ "GenSigSendType" SG_ 169 ESP_Antrieb_Anf 0;
BA_ "GenSigSwitchedByIgnition" SG_ 169 ESP_Reku_Anf 0;
BA_ "GenSigSendType" SG_ 169 ESP_Reku_Anf 0;
BA_ "Fehlerwert" SG_ 169 ESP_Bremspedalweg 255;
BA_ "GenSigSwitchedByIgnition" SG_ 169 ESP_Bremspedalweg 0;
BA_ "GenSigStartValue" SG_ 169 ESP_Bremspedalweg 254;
BA_ "GenSigSendType" SG_ 169 ESP_Bremspedalweg 0;
BA_ "Fehlerwert" SG_ 169 ESP_Reku_Index 255;
BA_ "GenSigSwitchedByIgnition" SG_ 169 ESP_Reku_Index 0;
BA_ "GenSigStartValue" SG_ 169 ESP_Reku_Index 254;
BA_ "GenSigSendType" SG_ 169 ESP_Reku_Index 0;
BA_ "Fehlerwert" SG_ 169 ESP_Reku_Limit 511;
BA_ "GenSigSwitchedByIgnition" SG_ 169 ESP_Reku_Limit 0;
BA_ "GenSigStartValue" SG_ 169 ESP_Reku_Limit 510;
BA_ "GenSigSendType" SG_ 169 ESP_Reku_Limit 0;
BA_ "GenSigSwitchedByIgnition" SG_ 169 ESP_Haltebestaetigung 0;
BA_ "GenSigSendType" SG_ 169 ESP_Haltebestaetigung 0;
BA_ "GenSigSwitchedByIgnition" SG_ 169 ESC_Motorstartverzoegerung 0;
BA_ "GenSigSendType" SG_ 169 ESC_Motorstartverzoegerung 0;
BA_ "GenSigSwitchedByIgnition" SG_ 169 ESP_KD_OBD_Readiness 0;
BA_ "GenSigSendType" SG_ 169 ESP_KD_OBD_Readiness 0;
BA_ "GenSigSwitchedByIgnition" SG_ 169 ESP_KD_OBD_Fehler 0;
BA_ "GenSigSendType" SG_ 169 ESP_KD_OBD_Fehler 0;
BA_ "GenSigFuncType" SG_ 1623 ESP_17_CRC 2;
BA_ "GenSigSendType" SG_ 1623 ESP_17_CRC 0;
BA_ "GenSigFuncType" SG_ 1623 ESP_17_BZ 1;
BA_ "GenSigSendType" SG_ 1623 ESP_17_BZ 0;
BA_ "Fehlerwert" SG_ 1623 ESP_BremsenTemp_hinten 7;
BA_ "GenSigStartValue" SG_ 1623 ESP_BremsenTemp_hinten 6;
BA_ "GenSigSendType" SG_ 1623 ESP_BremsenTemp_hinten 0;
BA_ "GenSigSwitchedByIgnition" SG_ 924 BCM1_02_alt 0;
BA_ "GenSigFuncType" SG_ 924 BCM1_02_alt 5;
BA_ "GenSigStartValue" SG_ 924 BCM1_02_alt 1;
BA_ "GenSigSendType" SG_ 924 BCM1_02_alt 0;
BA_ "GenSigSwitchedByIgnition" SG_ 924 Wischer_01_alt 0;
BA_ "GenSigFuncType" SG_ 924 Wischer_01_alt 5;
BA_ "GenSigStartValue" SG_ 924 Wischer_01_alt 1;
BA_ "GenSigSendType" SG_ 924 Wischer_01_alt 0;
BA_ "GenSigSwitchedByIgnition" SG_ 924 Klima_02_alt 0;
BA_ "GenSigFuncType" SG_ 924 Klima_02_alt 5;
BA_ "GenSigStartValue" SG_ 924 Klima_02_alt 1;
BA_ "GenSigSendType" SG_ 924 Klima_02_alt 0;
BA_ "GenSigSwitchedByIgnition" SG_ 924 BCM1_01_alt 0;
BA_ "GenSigFuncType" SG_ 924 BCM1_01_alt 5;
BA_ "GenSigStartValue" SG_ 924 BCM1_01_alt 1;
BA_ "GenSigSendType" SG_ 924 BCM1_01_alt 0;
BA_ "GenSigSwitchedByIgnition" SG_ 924 ESP_07_alt 0;
BA_ "GenSigFuncType" SG_ 924 ESP_07_alt 5;
BA_ "GenSigStartValue" SG_ 924 ESP_07_alt 1;
BA_ "GenSigSendType" SG_ 924 ESP_07_alt 0;
BA_ "GenSigSwitchedByIgnition" SG_ 924 TSG_BT_1_alt 0;
BA_ "GenSigFuncType" SG_ 924 TSG_BT_1_alt 5;
BA_ "GenSigStartValue" SG_ 924 TSG_BT_1_alt 1;
BA_ "GenSigSendType" SG_ 924 TSG_BT_1_alt 0;
BA_ "GenSigSwitchedByIgnition" SG_ 924 TSG_HL_1_alt 0;
BA_ "GenSigFuncType" SG_ 924 TSG_HL_1_alt 5;
BA_ "GenSigStartValue" SG_ 924 TSG_HL_1_alt 1;
BA_ "GenSigSendType" SG_ 924 TSG_HL_1_alt 0;
BA_ "GenSigSwitchedByIgnition" SG_ 924 TSG_HR_1_alt 0;
BA_ "GenSigFuncType" SG_ 924 TSG_HR_1_alt 5;
BA_ "GenSigStartValue" SG_ 924 TSG_HR_1_alt 1;
BA_ "GenSigSendType" SG_ 924 TSG_HR_1_alt 0;
BA_ "GenSigSwitchedByIgnition" SG_ 924 Motor_02_alt 0;
BA_ "GenSigFuncType" SG_ 924 Motor_02_alt 5;
BA_ "GenSigStartValue" SG_ 924 Motor_02_alt 1;
BA_ "GenSigSendType" SG_ 924 Motor_02_alt 0;
BA_ "GenSigSwitchedByIgnition" SG_ 924 Klima_Sensor_02_alt 0;
BA_ "GenSigFuncType" SG_ 924 Klima_Sensor_02_alt 5;
BA_ "GenSigStartValue" SG_ 924 Klima_Sensor_02_alt 1;
BA_ "GenSigSendType" SG_ 924 Klima_Sensor_02_alt 0;
BA_ "GenSigSwitchedByIgnition" SG_ 924 TSG_FT_1_alt 0;
BA_ "GenSigFuncType" SG_ 924 TSG_FT_1_alt 5;
BA_ "GenSigStartValue" SG_ 924 TSG_FT_1_alt 1;
BA_ "GenSigSendType" SG_ 924 TSG_FT_1_alt 0;
BA_ "GenSigSwitchedByIgnition" SG_ 924 Motor_05_alt 0;
BA_ "GenSigFuncType" SG_ 924 Motor_05_alt 5;
BA_ "GenSigStartValue" SG_ 924 Motor_05_alt 1;
BA_ "GenSigSendType" SG_ 924 Motor_05_alt 0;
BA_ "GenSigSwitchedByIgnition" SG_ 924 QSP_01_alt 0;
BA_ "GenSigFuncType" SG_ 924 QSP_01_alt 5;
BA_ "GenSigStartValue" SG_ 924 QSP_01_alt 1;
BA_ "GenSigSendType" SG_ 924 QSP_01_alt 0;
BA_ "GenSigSwitchedByIgnition" SG_ 924 Parkhilfe_01_alt 0;
BA_ "GenSigFuncType" SG_ 924 Parkhilfe_01_alt 5;
BA_ "GenSigStartValue" SG_ 924 Parkhilfe_01_alt 1;
BA_ "GenSigSendType" SG_ 924 Parkhilfe_01_alt 0;
BA_ "GenSigFuncType" SG_ 924 Fahrwerk_02_alt 5;
BA_ "GenSigStartValue" SG_ 924 Fahrwerk_02_alt 1;
BA_ "GenSigSendType" SG_ 924 Fahrwerk_02_alt 0;
BA_ "GenSigStartValue" SG_ 924 GW_05_va_27 1;
BA_ "GenSigSendType" SG_ 924 GW_05_va_27 0;
BA_ "GenSigSwitchedByIgnition" SG_ 924 BCM1_MH_WIV_Schalter 0;
BA_ "GenSigSendType" SG_ 924 BCM1_MH_WIV_Schalter 0;
BA_ "GenSigSwitchedByIgnition" SG_ 924 Wischer_vorne_aktiv 0;
BA_ "GenSigSendType" SG_ 924 Wischer_vorne_aktiv 0;
BA_ "GenSigSwitchedByIgnition" SG_ 924 BCM1_Rueckfahrlicht_Schalter 0;
BA_ "GenSigSendType" SG_ 924 BCM1_Rueckfahrlicht_Schalter 0;
BA_ "GenSigSwitchedByIgnition" SG_ 924 MO_Status_Normalbetrieb_01 0;
BA_ "GenSigSendType" SG_ 924 MO_Status_Normalbetrieb_01 3;
BA_ "GenSigSwitchedByIgnition" SG_ 924 KL_Zuheizer_Freigabe 0;
BA_ "GenSigSendType" SG_ 924 KL_Zuheizer_Freigabe 0;
BA_ "GenSigSwitchedByIgnition" SG_ 924 BCM1_Vorwaertsgang_eingelegt 0;
BA_ "GenSigSendType" SG_ 924 BCM1_Vorwaertsgang_eingelegt 0;
BA_ "GenSigSwitchedByIgnition" SG_ 924 ESP_Codierung_ADS 0;
BA_ "GenSigFuncType" SG_ 924 ESP_Codierung_ADS 8;
BA_ "GenSigSendType" SG_ 924 ESP_Codierung_ADS 0;
BA_ "GenSigSendType" SG_ 924 QSP_StartStopp_Info 0;
BA_ "GenSigSendType" SG_ 924 FA_StartStopp_Info 0;
BA_ "GenSigSendType" SG_ 924 PH_StartStopp_Info 0;
BA_ "GenSigSwitchedByIgnition" SG_ 924 KL_Beschlagsgefahr 0;
BA_ "GenSigSendType" SG_ 924 KL_Beschlagsgefahr 0;
BA_ "GenSigSwitchedByIgnition" SG_ 924 BCM1_GLW_Fernlicht_Anf 0;
BA_ "GenSigSendType" SG_ 924 BCM1_GLW_Fernlicht_Anf 3;
BA_ "GenSigSwitchedByIgnition" SG_ 924 BCM1_RFahrlicht_Fzg_Anf 0;
BA_ "GenSigSendType" SG_ 924 BCM1_RFahrlicht_Fzg_Anf 0;
BA_ "GenSigSwitchedByIgnition" SG_ 924 FT_Tuer_geoeffnet 0;
BA_ "GenSigSendType" SG_ 924 FT_Tuer_geoeffnet 0;
BA_ "GenSigSwitchedByIgnition" SG_ 924 MO_Handshake_STH 0;
BA_ "GenSigSendType" SG_ 924 MO_Handshake_STH 0;
BA_ "GenSigSwitchedByIgnition" SG_ 924 FT_Sperrklinke 0;
BA_ "GenSigSendType" SG_ 924 FT_Sperrklinke 0;
BA_ "GenSigSwitchedByIgnition" SG_ 924 BCM1_OBD_FStatus_ATemp 0;
BA_ "GenSigSendType" SG_ 924 BCM1_OBD_FStatus_ATemp 0;
BA_ "Fehlerwert" SG_ 924 BCM1_Aussen_Temp_ungef 255;
BA_ "GenSigSwitchedByIgnition" SG_ 924 BCM1_Aussen_Temp_ungef 0;
BA_ "GenSigStartValue" SG_ 924 BCM1_Aussen_Temp_ungef 254;
BA_ "GenSigSendType" SG_ 924 BCM1_Aussen_Temp_ungef 0;
BA_ "GenSigSwitchedByIgnition" SG_ 924 BCM1_Oeldruck_Schalter 0;
BA_ "GenSigSendType" SG_ 924 BCM1_Oeldruck_Schalter 0;
BA_ "GenSigSwitchedByIgnition" SG_ 924 BCM1_Oeldruck_Schalter_2 0;
BA_ "GenSigSendType" SG_ 924 BCM1_Oeldruck_Schalter_2 0;
BA_ "GenSigSwitchedByIgnition" SG_ 924 BT_Tuer_geoeffnet 0;
BA_ "GenSigSendType" SG_ 924 BT_Tuer_geoeffnet 0;
BA_ "GenSigSwitchedByIgnition" SG_ 924 HL_Tuer_geoeffnet 0;
BA_ "GenSigSendType" SG_ 924 HL_Tuer_geoeffnet 0;
BA_ "GenSigSwitchedByIgnition" SG_ 924 HR_Tuer_geoeffnet 0;
BA_ "GenSigSendType" SG_ 924 HR_Tuer_geoeffnet 0;
BA_ "GenSigSwitchedByIgnition" SG_ 924 BCM1_Adaptive_Lichtvert_Anf 0;
BA_ "GenSigSendType" SG_ 924 BCM1_Adaptive_Lichtvert_Anf 3;
BA_ "GenSigSwitchedByIgnition" SG_ 924 BCM1_Gleitende_Leuchtw_Anf 0;
BA_ "GenSigSendType" SG_ 924 BCM1_Gleitende_Leuchtw_Anf 3;
BA_ "GenSigSwitchedByIgnition" SG_ 924 BCM1_Schalter_StartStopp 0;
BA_ "GenSigStartValue" SG_ 924 BCM1_Schalter_StartStopp 1;
BA_ "GenSigSendType" SG_ 924 BCM1_Schalter_StartStopp 3;
BA_ "GenSigSwitchedByIgnition" SG_ 924 ESP_Offroad_Modus 0;
BA_ "GenSigSendType" SG_ 924 ESP_Offroad_Modus 0;
BA_ "GenSigSwitchedByIgnition" SG_ 924 MO_Freig_Reku 0;
BA_ "GenSigSendType" SG_ 924 MO_Freig_Reku 0;
BA_ "GenSigSwitchedByIgnition" SG_ 924 KL_HSH_ein_Soll 0;
BA_ "GenSigSendType" SG_ 924 KL_HSH_ein_Soll 3;
BA_ "GenSigSwitchedByIgnition" SG_ 924 FT_Tuerkontakt_Rohsignal 0;
BA_ "GenSigSendType" SG_ 924 FT_Tuerkontakt_Rohsignal 3;
BA_ "GenSigSwitchedByIgnition" SG_ 924 FT_TD_Taste 0;
BA_ "GenSigSendType" SG_ 924 FT_TD_Taste 3;
BA_ "GenSigSwitchedByIgnition" SG_ 924 FT_TD_Taste_Fehler 0;
BA_ "GenSigSendType" SG_ 924 FT_TD_Taste_Fehler 0;
BA_ "GenSigSendType" SG_ 924 PH_nachtr_Stopp_Anf 3;
BA_ "GenSigSwitchedByIgnition" SG_ 1604 SMLS_01_alt 0;
BA_ "GenSigFuncType" SG_ 1604 SMLS_01_alt 5;
BA_ "GenSigStartValue" SG_ 1604 SMLS_01_alt 1;
BA_ "GenSigSendType" SG_ 1604 SMLS_01_alt 0;
BA_ "GenSigSwitchedByIgnition" SG_ 1604 HUD_01_alt 0;
BA_ "GenSigFuncType" SG_ 1604 HUD_01_alt 5;
BA_ "GenSigStartValue" SG_ 1604 HUD_01_alt 1;
BA_ "GenSigSendType" SG_ 1604 HUD_01_alt 0;
BA_ "GenSigSwitchedByIgnition" SG_ 1604 BCM1_01_alt 0;
BA_ "GenSigFuncType" SG_ 1604 BCM1_01_alt 5;
BA_ "GenSigStartValue" SG_ 1604 BCM1_01_alt 1;
BA_ "GenSigSendType" SG_ 1604 BCM1_01_alt 0;
BA_ "GenSigSwitchedByIgnition" SG_ 1604 BCM1_02_alt 0;
BA_ "GenSigFuncType" SG_ 1604 BCM1_02_alt 5;
BA_ "GenSigStartValue" SG_ 1604 BCM1_02_alt 1;
BA_ "GenSigSendType" SG_ 1604 BCM1_02_alt 0;
BA_ "GenSigSwitchedByIgnition" SG_ 1604 BCM2_02_alt 0;
BA_ "GenSigFuncType" SG_ 1604 BCM2_02_alt 5;
BA_ "GenSigStartValue" SG_ 1604 BCM2_02_alt 1;
BA_ "GenSigSendType" SG_ 1604 BCM2_02_alt 0;
BA_ "GenSigSwitchedByIgnition" SG_ 1604 HYB_Anf_E_Mode_alt 0;
BA_ "GenSigFuncType" SG_ 1604 HYB_Anf_E_Mode_alt 5;
BA_ "GenSigStartValue" SG_ 1604 HYB_Anf_E_Mode_alt 1;
BA_ "GenSigSendType" SG_ 1604 HYB_Anf_E_Mode_alt 0;
BA_ "GenSigSwitchedByIgnition" SG_ 1604 BCM1_04_alt 0;
BA_ "GenSigFuncType" SG_ 1604 BCM1_04_alt 5;
BA_ "GenSigStartValue" SG_ 1604 BCM1_04_alt 1;
BA_ "GenSigSendType" SG_ 1604 BCM1_04_alt 0;
BA_ "GenSigSwitchedByIgnition" SG_ 1604 ESP_04_alt 0;
BA_ "GenSigFuncType" SG_ 1604 ESP_04_alt 5;
BA_ "GenSigStartValue" SG_ 1604 ESP_04_alt 1;
BA_ "GenSigSendType" SG_ 1604 ESP_04_alt 0;
BA_ "GenSigSwitchedByIgnition" SG_ 1604 Kessy_01_alt 0;
BA_ "GenSigFuncType" SG_ 1604 Kessy_01_alt 5;
BA_ "GenSigStartValue" SG_ 1604 Kessy_01_alt 1;
BA_ "GenSigSendType" SG_ 1604 Kessy_01_alt 0;
BA_ "GenSigFuncType" SG_ 1604 Lift_01_alt 5;
BA_ "GenSigStartValue" SG_ 1604 Lift_01_alt 1;
BA_ "GenSigSendType" SG_ 1604 Lift_01_alt 0;
BA_ "GenSigSwitchedByIgnition" SG_ 1604 GW_11_va_22 0;
BA_ "GenSigStartValue" SG_ 1604 GW_11_va_22 1;
BA_ "GenSigSendType" SG_ 1604 GW_11_va_22 0;
BA_ "GenSigSwitchedByIgnition" SG_ 1604 GW_11_va_23 0;
BA_ "GenSigStartValue" SG_ 1604 GW_11_va_23 1;
BA_ "GenSigSendType" SG_ 1604 GW_11_va_23 0;
BA_ "GenSigSwitchedByIgnition" SG_ 1604 GW_11_va_24 0;
BA_ "GenSigStartValue" SG_ 1604 GW_11_va_24 1;
BA_ "GenSigSendType" SG_ 1604 GW_11_va_24 0;
BA_ "GenSigSwitchedByIgnition" SG_ 1604 GW_11_va_25 0;
BA_ "GenSigStartValue" SG_ 1604 GW_11_va_25 1;
BA_ "GenSigSendType" SG_ 1604 GW_11_va_25 0;
BA_ "GenSigSwitchedByIgnition" SG_ 1604 GW_11_va_26 0;
BA_ "GenSigStartValue" SG_ 1604 GW_11_va_26 1;
BA_ "GenSigSendType" SG_ 1604 GW_11_va_26 0;
BA_ "GenSigSwitchedByIgnition" SG_ 1604 GW_11_va_27 0;
BA_ "GenSigStartValue" SG_ 1604 GW_11_va_27 1;
BA_ "GenSigSendType" SG_ 1604 GW_11_va_27 0;
BA_ "GenSigSwitchedByIgnition" SG_ 1604 BH_Blinker_li 0;
BA_ "GenSigSendType" SG_ 1604 BH_Blinker_li 3;
BA_ "GenSigSwitchedByIgnition" SG_ 1604 BH_Blinker_re 0;
BA_ "GenSigSendType" SG_ 1604 BH_Blinker_re 3;
BA_ "GenSigSendType" SG_ 1604 BM_Autobahn 0;
BA_ "GenSigSwitchedByIgnition" SG_ 1604 BH_Fernlicht 0;
BA_ "GenSigSendType" SG_ 1604 BH_Fernlicht 3;
BA_ "GenSigSwitchedByIgnition" SG_ 1604 BH_Lichthupe 0;
BA_ "GenSigSendType" SG_ 1604 BH_Lichthupe 3;
BA_ "GenSigSwitchedByIgnition" SG_ 1604 BCM1_MH_Schalter 0;
BA_ "GenSigSendType" SG_ 1604 BCM1_MH_Schalter 0;
BA_ "GenSigSwitchedByIgnition" SG_ 1604 HYB_Anf_E_Mode 0;
BA_ "GenSigSendType" SG_ 1604 HYB_Anf_E_Mode 3;
BA_ "GenSigSwitchedByIgnition" SG_ 1604 HUD_NV_in_Anzeige 0;
BA_ "GenSigSendType" SG_ 1604 HUD_NV_in_Anzeige 3;
BA_ "GenSigSwitchedByIgnition" SG_ 1604 BCM1_Touristen_Licht_Anf 0;
BA_ "GenSigSendType" SG_ 1604 BCM1_Touristen_Licht_Anf 0;
BA_ "GenSigSwitchedByIgnition" SG_ 1604 LV_Abblendlicht_li_def 0;
BA_ "GenSigSendType" SG_ 1604 LV_Abblendlicht_li_def 0;
BA_ "GenSigSwitchedByIgnition" SG_ 1604 LV_Abblendlicht_re_def 0;
BA_ "GenSigSendType" SG_ 1604 LV_Abblendlicht_re_def 0;
BA_ "GenSigSwitchedByIgnition" SG_ 1604 LV_Abblendlicht_Anzeige 0;
BA_ "GenSigSendType" SG_ 1604 LV_Abblendlicht_Anzeige 0;
BA_ "GenSigSwitchedByIgnition" SG_ 1604 LV_AFL_aktiv_Anzeige 0;
BA_ "GenSigSendType" SG_ 1604 LV_AFL_aktiv_Anzeige 3;
BA_ "GenSigSwitchedByIgnition" SG_ 1604 BCM1_Licht_Dunkelheit_aktiv 0;
BA_ "GenSigSendType" SG_ 1604 BCM1_Licht_Dunkelheit_aktiv 3;
BA_ "GenSigSwitchedByIgnition" SG_ 1604 LV_Nebelschlusslicht_Anzeige 0;
BA_ "GenSigSendType" SG_ 1604 LV_Nebelschlusslicht_Anzeige 0;
BA_ "GenSigSwitchedByIgnition" SG_ 1604 BCM1_Linksverkehr 0;
BA_ "GenSigSendType" SG_ 1604 BCM1_Linksverkehr 0;
BA_ "GenSigSwitchedByIgnition" SG_ 1604 BCM2_P_verriegelt 0;
BA_ "GenSigSendType" SG_ 1604 BCM2_P_verriegelt 0;
BA_ "Fehlerwert" SG_ 1604 BCM1_LDS_Stellung 7;
BA_ "GenSigSwitchedByIgnition" SG_ 1604 BCM1_LDS_Stellung 0;
BA_ "GenSigSendType" SG_ 1604 BCM1_LDS_Stellung 3;
BA_ "GenSigSwitchedByIgnition" SG_ 1604 BCM1_Allwetterlicht_Anf 0;
BA_ "GenSigSendType" SG_ 1604 BCM1_Allwetterlicht_Anf 3;
BA_ "GenSigSendType" SG_ 1604 HUD_Anzeigefehler_NV 0;
BA_ "GenSigSwitchedByIgnition" SG_ 1604 ESP_Diagnose 0;
BA_ "GenSigSendType" SG_ 1604 ESP_Diagnose 3;
BA_ "GenSigSwitchedByIgnition" SG_ 1604 BCM1_SRA_aktiv 0;
BA_ "GenSigSendType" SG_ 1604 BCM1_SRA_aktiv 0;
BA_ "GenSigSendType" SG_ 1604 FFB_Auf_Taste 0;
BA_ "GenSigSendType" SG_ 1604 FFB_CarFinder 0;
BA_ "GenSigSendType" SG_ 1604 ZV_verriegelt_extern_ist 0;
BA_ "GenSigSendType" SG_ 1604 BCM_Tankwunsch 0;
BA_ "GenSigSendType" SG_ 1604 ZV_Tankklappe_offen 0;
BA_ "GenSigSwitchedByIgnition" SG_ 130 Getriebe_01_CHK 0;
BA_ "GenSigFuncType" SG_ 130 Getriebe_01_CHK 3;
BA_ "GenSigSendType" SG_ 130 Getriebe_01_CHK 0;
BA_ "GenSigSwitchedByIgnition" SG_ 130 Getriebe_01_BZ 0;
BA_ "GenSigFuncType" SG_ 130 Getriebe_01_BZ 1;
BA_ "GenSigSendType" SG_ 130 Getriebe_01_BZ 0;
BA_ "GenSigSwitchedByIgnition" SG_ 130 GE_Schaltvorgang 0;
BA_ "GenSigSendType" SG_ 130 GE_Schaltvorgang 0;
BA_ "Fehlerwert" SG_ 130 GE_Status_Kupplung 3;
BA_ "GenSigSwitchedByIgnition" SG_ 130 GE_Status_Kupplung 0;
BA_ "GenSigSendType" SG_ 130 GE_Status_Kupplung 0;
BA_ "GenSigSwitchedByIgnition" SG_ 130 GE_Verbot_Ausblendung 0;
BA_ "GenSigSendType" SG_ 130 GE_Verbot_Ausblendung 0;
BA_ "Fehlerwert" SG_ 130 GE_MMom_Soll 1023;
BA_ "GenSigSwitchedByIgnition" SG_ 130 GE_MMom_Soll 0;
BA_ "GenSigStartValue" SG_ 130 GE_MMom_Soll 1022;
BA_ "GenSigSendType" SG_ 130 GE_MMom_Soll 0;
BA_ "GenSigSwitchedByIgnition" SG_ 130 GE_MMom_Status 0;
BA_ "GenSigSendType" SG_ 130 GE_MMom_Status 0;
BA_ "GenSigSwitchedByIgnition" SG_ 130 GE_Freig_Mmom_Soll 0;
BA_ "GenSigSendType" SG_ 130 GE_Freig_Mmom_Soll 0;
BA_ "GenSigSwitchedByIgnition" SG_ 130 GE_Status_Schaltablauf 0;
BA_ "GenSigSendType" SG_ 130 GE_Status_Schaltablauf 0;
BA_ "Fehlerwert" SG_ 130 GE_MMom_Vorhalt 1023;
BA_ "GenSigSwitchedByIgnition" SG_ 130 GE_MMom_Vorhalt 0;
BA_ "GenSigStartValue" SG_ 130 GE_MMom_Vorhalt 1022;
BA_ "GenSigSendType" SG_ 130 GE_MMom_Vorhalt 0;
BA_ "GenSigSwitchedByIgnition" SG_ 130 GE_Freig_MMom_Vorhalt 0;
BA_ "GenSigSendType" SG_ 130 GE_Freig_MMom_Vorhalt 0;
BA_ "GenSigSwitchedByIgnition" SG_ 130 GE_KD_Fehler 0;
BA_ "GenSigSendType" SG_ 130 GE_KD_Fehler 0;
BA_REL_ "GenSigTimeoutTime" BU_SG_REL_ Getriebe_DL382_MLB SG_ 901 CHA_01_CHK 1000;
BA_REL_ "GenSigTimeoutTime" BU_SG_REL_ Getriebe_DL382_MLB SG_ 901 CHA_Systemstatus 1000;
BA_REL_ "GenSigTimeoutTime" BU_SG_REL_ SAK SG_ 901 CHA_Systemstatus 1000;
BA_REL_ "GenSigTimeoutTime" BU_SG_REL_ Getriebe_DL382_MLB SG_ 901 CHA_Ziel_FahrPr_GE 1000;
BA_REL_ "GenSigTimeoutTime" BU_SG_REL_ SAK SG_ 901 CHA_Ziel_FahrPr_SAK 1000;
BA_REL_ "GenSigTimeoutTime" BU_SG_REL_ Gateway SG_ 918 DR_KD_Fehler 800;
BA_REL_ "GenSigTimeoutTime" BU_SG_REL_ SAK SG_ 1714 DGN_Verlernzaehler 5000;
BA_REL_ "GenSigTimeoutTime" BU_SG_REL_ Getriebe_DL382_MLB SG_ 1714 KBI_Kilometerstand 5000;
BA_REL_ "GenSigTimeoutTime" BU_SG_REL_ SAK SG_ 1714 KBI_Kilometerstand 5000;
BA_REL_ "GenSigTimeoutTime" BU_SG_REL_ Getriebe_DL382_MLB SG_ 1714 UH_Jahr 5000;
BA_REL_ "GenSigTimeoutTime" BU_SG_REL_ SAK SG_ 1714 UH_Jahr 5000;
BA_REL_ "GenSigTimeoutTime" BU_SG_REL_ Getriebe_DL382_MLB SG_ 1714 UH_Monat 5000;
BA_REL_ "GenSigTimeoutTime" BU_SG_REL_ SAK SG_ 1714 UH_Monat 5000;
BA_REL_ "GenSigTimeoutTime" BU_SG_REL_ Getriebe_DL382_MLB SG_ 1714 UH_Tag 5000;
BA_REL_ "GenSigTimeoutTime" BU_SG_REL_ SAK SG_ 1714 UH_Tag 5000;
BA_REL_ "GenSigTimeoutTime" BU_SG_REL_ Getriebe_DL382_MLB SG_ 1714 UH_Stunde 5000;
BA_REL_ "GenSigTimeoutTime" BU_SG_REL_ SAK SG_ 1714 UH_Stunde 5000;
BA_REL_ "GenSigTimeoutTime" BU_SG_REL_ Getriebe_DL382_MLB SG_ 1714 UH_Minute 5000;
BA_REL_ "GenSigTimeoutTime" BU_SG_REL_ SAK SG_ 1714 UH_Minute 5000;
BA_REL_ "GenSigTimeoutTime" BU_SG_REL_ Getriebe_DL382_MLB SG_ 1714 UH_Sekunde 5000;
BA_REL_ "GenSigTimeoutTime" BU_SG_REL_ SAK SG_ 1714 UH_Sekunde 5000;
BA_REL_ "GenSigTimeoutTime" BU_SG_REL_ Getriebe_DL382_MLB SG_ 1714 Kombi_02_alt 5000;
BA_REL_ "GenSigTimeoutTime" BU_SG_REL_ Getriebe_DL382_MLB SG_ 1714 Uhrzeit_01_alt 5000;
BA_REL_ "GenSigTimeoutTime" BU_SG_REL_ Gateway SG_ 1627 EM_HYB_KD_Fehler 5000;
BA_REL_ "GenSigTimeoutTime" BU_SG_REL_ Getriebe_DL382_MLB SG_ 260 EPB_Spannkraft 500;
BA_REL_ "GenSigTimeoutTime" BU_SG_REL_ Getriebe_DL382_MLB SG_ 260 EPB_Status 500;
BA_REL_ "GenSigTimeoutTime" BU_SG_REL_ Gateway SG_ 260 EPB_KD_Fehler 500;
BA_REL_ "GenSigTimeoutTime" BU_SG_REL_ Getriebe_DL382_MLB SG_ 256 ESP_01_CHK 500;
BA_REL_ "GenSigTimeoutTime" BU_SG_REL_ Getriebe_DL382_MLB SG_ 256 ESP_01_BZ 500;
BA_REL_ "GenSigTimeoutTime" BU_SG_REL_ Getriebe_DL382_MLB SG_ 256 ASR_Moment_langsam 500;
BA_REL_ "GenSigTimeoutTime" BU_SG_REL_ Getriebe_DL382_MLB SG_ 256 ASR_MSR_Moment_schnell 500;
BA_REL_ "GenSigTimeoutTime" BU_SG_REL_ Getriebe_DL382_MLB SG_ 256 ESP_v_Signal 500;
BA_REL_ "GenSigTimeoutTime" BU_SG_REL_ SAK SG_ 256 ESP_v_Signal 500;
BA_REL_ "GenSigTimeoutTime" BU_SG_REL_ Getriebe_DL382_MLB SG_ 256 ASR_Tastung_passiv 500;
BA_REL_ "GenSigTimeoutTime" BU_SG_REL_ Getriebe_DL382_MLB SG_ 256 ESP_Tastung_passiv 500;
BA_REL_ "GenSigTimeoutTime" BU_SG_REL_ Getriebe_DL382_MLB SG_ 256 ESP_Systemstatus 500;
BA_REL_ "GenSigTimeoutTime" BU_SG_REL_ Getriebe_DL382_MLB SG_ 256 ASR_Schalteingriff 500;
BA_REL_ "GenSigTimeoutTime" BU_SG_REL_ Getriebe_DL382_MLB SG_ 256 ESP_QBit_v_Signal 500;
BA_REL_ "GenSigTimeoutTime" BU_SG_REL_ Getriebe_DL382_MLB SG_ 256 ABS_Bremsung 500;
BA_REL_ "GenSigTimeoutTime" BU_SG_REL_ Getriebe_DL382_MLB SG_ 256 ASR_Anf 500;
BA_REL_ "GenSigTimeoutTime" BU_SG_REL_ Getriebe_DL382_MLB SG_ 256 MSR_Anf 500;
BA_REL_ "GenSigTimeoutTime" BU_SG_REL_ Getriebe_DL382_MLB SG_ 256 EBV_Eingriff 500;
BA_REL_ "GenSigTimeoutTime" BU_SG_REL_ Getriebe_DL382_MLB SG_ 256 EDS_Eingriff 500;
BA_REL_ "GenSigTimeoutTime" BU_SG_REL_ Getriebe_DL382_MLB SG_ 256 EDS_Eingriff 500;
BA_REL_ "GenSigTimeoutTime" BU_SG_REL_ Getriebe_DL382_MLB SG_ 256 EDS_Eingriff 500;
BA_REL_ "GenSigTimeoutTime" BU_SG_REL_ Getriebe_DL382_MLB SG_ 256 ESP_Eingriff 500;
BA_REL_ "GenSigTimeoutTime" BU_SG_REL_ Getriebe_DL382_MLB SG_ 257 ESP_02_CHK 500;
BA_REL_ "GenSigTimeoutTime" BU_SG_REL_ Getriebe_DL382_MLB SG_ 257 ESP_02_CHK 500;
BA_REL_ "GenSigTimeoutTime" BU_SG_REL_ Getriebe_DL382_MLB SG_ 257 ESP_02_BZ 500;
BA_REL_ "GenSigTimeoutTime" BU_SG_REL_ Getriebe_DL382_MLB SG_ 257 ESP_02_BZ 500;
BA_REL_ "GenSigTimeoutTime" BU_SG_REL_ Getriebe_DL382_MLB SG_ 257 ESP_QBit_Laengsbeschl 500;
BA_REL_ "GenSigTimeoutTime" BU_SG_REL_ Getriebe_DL382_MLB SG_ 257 ESP_QBit_Querb 500;
BA_REL_ "GenSigTimeoutTime" BU_SG_REL_ Getriebe_DL382_MLB SG_ 257 ESP_Stillstandsflag 500;
BA_REL_ "GenSigTimeoutTime" BU_SG_REL_ Getriebe_DL382_MLB SG_ 257 ESP_Querbeschleunigung 500;
BA_REL_ "GenSigTimeoutTime" BU_SG_REL_ Getriebe_DL382_MLB SG_ 257 ESP_Laengsbeschl 500;
BA_REL_ "GenSigTimeoutTime" BU_SG_REL_ Getriebe_DL382_MLB SG_ 259 ESP_03_CHK 500;
BA_REL_ "GenSigTimeoutTime" BU_SG_REL_ Getriebe_DL382_MLB SG_ 259 ESP_03_BZ 500;
BA_REL_ "GenSigTimeoutTime" BU_SG_REL_ Getriebe_DL382_MLB SG_ 259 ESP_VL_FR 500;
BA_REL_ "GenSigTimeoutTime" BU_SG_REL_ Getriebe_DL382_MLB SG_ 259 ESP_VR_FR 500;
BA_REL_ "GenSigTimeoutTime" BU_SG_REL_ Getriebe_DL382_MLB SG_ 259 ESP_HL_FR 500;
BA_REL_ "GenSigTimeoutTime" BU_SG_REL_ Getriebe_DL382_MLB SG_ 259 ESP_HR_FR 500;
BA_REL_ "GenSigTimeoutTime" BU_SG_REL_ Getriebe_DL382_MLB SG_ 259 ESP_VL_Radgeschw 500;
BA_REL_ "GenSigTimeoutTime" BU_SG_REL_ Getriebe_DL382_MLB SG_ 259 ESP_VR_Radgeschw 500;
BA_REL_ "GenSigTimeoutTime" BU_SG_REL_ Getriebe_DL382_MLB SG_ 259 ESP_HL_Radgeschw 500;
BA_REL_ "GenSigTimeoutTime" BU_SG_REL_ Getriebe_DL382_MLB SG_ 259 ESP_HR_Radgeschw 500;
BA_REL_ "GenSigTimeoutTime" BU_SG_REL_ Getriebe_DL382_MLB SG_ 262 ESP_05_CHK 500;
BA_REL_ "GenSigTimeoutTime" BU_SG_REL_ Getriebe_DL382_MLB SG_ 262 ESP_05_BZ 500;
BA_REL_ "GenSigTimeoutTime" BU_SG_REL_ Getriebe_DL382_MLB SG_ 262 ESP_QBit_Bremsdruck 500;
BA_REL_ "GenSigTimeoutTime" BU_SG_REL_ Getriebe_DL382_MLB SG_ 262 ESP_Bremsdruck 500;
BA_REL_ "GenSigTimeoutTime" BU_SG_REL_ Getriebe_DL382_MLB SG_ 262 ESP_Autohold_aktiv 500;
BA_REL_ "GenSigTimeoutTime" BU_SG_REL_ Getriebe_DL382_MLB SG_ 262 ESP_Autohold_aktiv 500;
BA_REL_ "GenSigTimeoutTime" BU_SG_REL_ Getriebe_DL382_MLB SG_ 262 ESP_Status_Bremsdruck 500;
BA_REL_ "GenSigTimeoutTime" BU_SG_REL_ SCU SG_ 132 ESP_06_CHK 40;
BA_REL_ "GenSigTimeoutTime" BU_SG_REL_ SCU SG_ 132 ESP_06_BZ 40;
BA_REL_ "GenSigTimeoutTime" BU_SG_REL_ Gateway SG_ 132 ESP_06_KD_Fehler 500;
BA_REL_ "GenSigTimeoutTime" BU_SG_REL_ SCU SG_ 132 ESP_Teilsollwinkel 40;
BA_REL_ "GenSigTimeoutTime" BU_SG_REL_ SCU SG_ 132 ESP_VZ_Teilsollwinkel 40;
BA_REL_ "GenSigTimeoutTime" BU_SG_REL_ SCU SG_ 132 ESP_Winkeleingriff 40;
BA_REL_ "GenSigTimeoutTime" BU_SG_REL_ SCU SG_ 132 ESP_Status_ADS 40;
BA_REL_ "GenSigTimeoutTime" BU_SG_REL_ SCU SG_ 132 ESP_06_CRC 40;
BA_REL_ "GenSigTimeoutTime" BU_SG_REL_ Getriebe_DL382_MLB SG_ 924 BCM1_Schalter_StartStopp 1000;
BA_REL_ "GenSigTimeoutTime" BU_SG_REL_ Gateway SG_ 130 GE_KD_Fehler 500;
VAL_ 901 CHA_Systemstatus 0 "Status in Ordnung" 1 "reserviert" 2 "reserviert" 3 "reserviert" ;
VAL_ 901 CHA_Fahrer_Umschaltung 0 "keine_oder_automatische_Umschaltung" 1 "manuelle_Umschaltung" ;
VAL_ 901 CHA_Ziel_FahrPr_MO 0 "nicht_belegt" 1 "Programm_1" 2 "Programm_2" 3 "Programm_3" 4 "Programm_4" 5 "Programm_5" 6 "Programm_6" 7 "Programm_7" ;
VAL_ 901 CHA_Ziel_FahrPr_GE 0 "nicht_belegt" 1 "Programm_1" 2 "Programm_2" 3 "Programm_3" 4 "Programm_4" 5 "Programm_5" 6 "Programm_6" 7 "Programm_7" ;
VAL_ 901 CHA_Ziel_FahrPr_ST 0 "nicht_belegt" 1 "Programm_1" 2 "Programm_2" 3 "Programm_3" 4 "Programm_4" 5 "Programm_5" 6 "Programm_6" 7 "Programm_7" ;
VAL_ 901 CHA_Ziel_FahrPr_SCU 0 "nicht_belegt" 1 "Programm_1" 2 "Programm_2" 3 "Programm_3" 4 "Programm_4" 5 "Programm_5" 6 "Programm_6" 7 "Programm_7" ;
VAL_ 901 CHA_Ziel_FahrPr_DR 0 "nicht_belegt" 1 "Programm_1" 2 "Programm_2" 3 "Programm_3" 4 "Programm_4" 5 "Programm_5" 6 "Programm_6" 7 "Programm_7" ;
VAL_ 901 CHA_Ziel_FahrPr_QS 0 "nicht_belegt" 1 "Programm_1" 2 "Programm_2" 3 "Programm_3" 4 "Programm_4" 5 "Programm_5" 6 "Programm_6" 7 "Programm_7" ;
VAL_ 901 CHA_Ziel_FahrPr_AFS 0 "nicht_belegt" 1 "Programm_1" 2 "Programm_2" 3 "Programm_3" 4 "Programm_4" 5 "Programm_5" 6 "Programm_6" 7 "Programm_7" ;
VAL_ 901 CHA_Ziel_FahrPr_RGS 0 "nicht_belegt" 1 "Programm_1" 2 "Programm_2" 3 "Programm_3" 4 "Programm_4" 5 "Programm_5" 6 "Programm_6" 7 "Programm_7" ;
VAL_ 901 CHA_Ziel_FahrPr_EPS 0 "nicht_belegt" 1 "Programm_1" 2 "Programm_2" 3 "Programm_3" 4 "Programm_4" 5 "Programm_5" 6 "Programm_6" 7 "Programm_7" ;
VAL_ 901 CHA_Ziel_FahrPr_ACC 0 "nicht_belegt" 1 "Programm_1" 2 "Programm_2" 3 "Programm_3" 4 "Programm_4" 5 "Programm_5" 6 "Programm_6" 7 "Programm_7" ;
VAL_ 901 CHA_Ziel_FahrPr_SAK 0 "nicht_belegt" 1 "Programm_1" 2 "Programm_2" 3 "Programm_3" 4 "Programm_4" 5 "Programm_5" 6 "Programm_6" 7 "Programm_7" ;
VAL_ 918 DR_Systemstatus 0 "Init oder kein Wert verfuegbar" 1 "Komfortabel" 2 "Normal" 3 "Sport 1" 4 "Sport 2" 5 "nicht funktionsfähig" 6 "Funktionseinschränkung aktiv" 7 "Notfahrfunktion" ;
VAL_ 918 LF_Texte 0 "keine_Anzeige" 1 "Text_Fahrzeug_momentan_zu_tief_Regelung_laeuft" 2 "Text_Fahrzeug_momentan_zu_hoch_Regelung_laeuft" 3 "Text_Niveauregelung_abgeschaltet" ;
VAL_ 918 DR_Taster 0 "Taster nicht gedrückt" 1 "Taster gedrückt" ;
VAL_ 918 DR_Gelbe_Warnlampe 0 "Warnlampe aus" 1 "Warnlampe ein (Aufprüfen)" 2 "Warnlampe an (Warnung)" 3 "reserviert" ;
VAL_ 918 DR_Daempferreg_Texte 0 "kein Text" 1 "Daempfer_Sport" 2 "Daempfer_Basis" 3 "Daempfer_Comfort" 15 "Verlademodus" ;
VAL_ 918 DR_Charisma_FahrPr 0 "nicht_belegt" 1 "Programm_1" 2 "Programm_2" 3 "Programm_3" 4 "Programm_4" 5 "Programm_5" 6 "Programm_6" 7 "Programm_7" ;
VAL_ 918 DR_Charisma_Status 0 "Init" 1 "verfuegbar" 2 "nicht_verfuegbar" 3 "asynchron_durch_Fahrerwunsch" ;
VAL_ 918 DR_Charisma_Umschaltung 0 "Idle" 1 "Erkennung_Umschaltaufforderung" 2 "Steuerbotschaft_nicht_definiert" 3 "Umschaltung_verzoegert" ;
VAL_ 918 DR_Fahrzeugart 0 "Stahl + PASM" 1 "Luftfederung + PASM" 2 "Stahl + PASM + PADM  " 3 "Stahl + PADM " ;
VAL_ 918 LF_Warnung_Prio1 0 "keine_Anzeige" 1 "Text_Servicemodus" 2 "Text_Fehler_Luftfeder_Geschwindigkeit_1" 3 "Text_Fehler_Luftfeder_Geschwindigkeit_2" ;
VAL_ 918 LF_Warnung_Prio2 0 "keine_Anzeige" 1 "Text_Fahrzeug_zu_tief_Bodenfreiheit_eingeschraenkt" 2 "Text_Fehler_Luftfeder" 3 "tbd" ;
VAL_ 918 DR_DynAGL_Warnlampe 0 "Warnlampe aus" 1 "Warnlampe ein" ;
VAL_ 918 DR_Rote_Warnlampe 0 "Warnlampe aus" 1 "Warnlampe ein (Aufprüfen)" 2 "Warnlampe an (Warnung)" 3 "reserviert" ;
VAL_ 918 NI_Status 0 "Eingefahren" 1 "Ausgefahren" 2 "heben" 3 "senken" 4 "blockiert" 5 "gesperrt" 7 "Fehler" ;
VAL_ 918 NR_Niveaufunktion_aktiv 0 "keine_Umschaltung_erfolgt" 3 "lift_aktiv" ;
VAL_ 918 DR_KD_Fehler 0 "kein_KD_Fehler" 1 "KD_Fehler" ;
VAL_ 945 DC_Verbrauch_Ueberlauf 0 "kein_Ueberlauf" 1 "Ueberlauf" ;
VAL_ 945 DC_HYB_iAktLV 1022 "Init" 1023 "Fehler" ;
VAL_ 945 DC_HYB_iAktReserveLV 1022 "Init" 1023 "Fehler" ;
VAL_ 945 DC_HYB_uAktLV 254 "Init" 255 "Fehler" ;
VAL_ 945 DC_HYB_LangsRegelung 0 "normale_Regelung" 1 "langsame_Regelung" ;
VAL_ 945 DC_HYB_Abregelung_Temperatur 0 "keine_Begrenzung" 1 "Abregelung_Temperatur" ;
VAL_ 945 DC_HYB_Fehler_RedLeistung 0 "kein_Fehler" 1 "Fehler_RedLeistung" ;
VAL_ 945 DC_HYB_Fehler_intern 0 "kein_Fehler" 1 "Fehler_intern" ;
VAL_ 945 DC_HYB_Fehler_Spannung 0 "kein_Fehler" 1 "Fehler_Spannung" ;
VAL_ 945 DC_TiefsetzBereit 0 "Standby" 1 "Tiefsetzbereit" ;
VAL_ 945 DC_HYB_Auslastungsgrad 255 "Fehler" ;
VAL_ 1714 DGN_Verlernzaehler 255 "ungültiger Zählerstand oder kein gültiger Fahrzyklus" ;
VAL_ 1714 KBI_Kilometerstand 1048574 "Init" 1048575 "Fehler" ;
VAL_ 1714 UH_Monat 0 "Init" 14 "reserviert" 15 "Fehler" ;
VAL_ 1714 UH_Tag 0 "Init" ;
VAL_ 1714 Kombi_02_alt 0 "aktuell" 1 "veraltet" ;
VAL_ 1714 Uhrzeit_01_alt 0 "aktuell" 1 "veraltet" ;
VAL_ 1520 DI_KL_58d 254 "Init" 255 "Fehler" ;
VAL_ 1520 DI_KL_58s 126 "Init" 127 "Fehler" ;
VAL_ 1520 DI_KL_58st 126 "Init" 127 "Fehler" ;
VAL_ 1603 KBI_Einheit_Datum 0 "Tag/Monat/Jahr" 1 "Monat/Tag/Jahr" 2 "Jahr/Monat/Tag" 3 "reserviert" ;
VAL_ 1603 KBI_Einheit_Druck 0 "Druckangabe in bar" 1 "Druckangabe in psi" 2 "Druckangabe in kPa" 3 "tbd." ;
VAL_ 1603 KBI_Einheit_Streckenanz 0 "Kilometer" 1 "Meilen" ;
VAL_ 1603 KBI_MFA_v_Einheit_02 0 "kmh" 1 "mph" ;
VAL_ 1603 KBI_Einheit_Temp 0 "Grad Celsius °C" 1 "Grad Fahrenheit °F" ;
VAL_ 1603 KBI_Einheit_Uhrzeit 0 "24h" 1 " 12h AM/PM" ;
VAL_ 1603 KBI_Einheit_Verbrauch 0 "mpg UK" 1 "mpg USA" 2 "Liter/100km" 3 "km/Liter" ;
VAL_ 1603 KBI_Einheit_Volumen 0 "Liter" 1 "Gallonen UK" 2 "Gallonen USA" 3 "reserviert" ;
VAL_ 1603 KBI_Einheit_Verbrauch_elektr 0 "kWh_pro_100km" 1 "kWh_pro_100mls" 2 "km_pro_kWh" 3 "mls_pro_kWh" 4 "MPGe" ;
VAL_ 1627 EM_HYB_KD_Fehler 0 "kein_KD_Fehler" 1 "KD_Fehler" ;
VAL_ 260 EPB_QBit_Laengsbeschleunigung 0 "gültiger Wert" 1 "Ersatz-, Init- oder Fehlerwert" ;
VAL_ 260 EPB_QBit_Pedalweg_Kuppl 0 "gültiger Wert" 1 "Ersatz-, Init- oder Fehlerwert" ;
VAL_ 260 EPB_BCM2_Motor_Wakeup 0 "keine Anforderung" 1 "Anforderung an BCM2 Wakeupleitung zum Motor hochzuziehen aufgrund von Car-Wakeup" ;
VAL_ 260 EPB_Freig_Verzoeg_Anf 0 "nicht freigegeben" 1 "freigegeben" ;
VAL_ 260 EPB_Laengsbeschleunigung 255 "Fehler" ;
VAL_ 260 EPB_Pedalweg_Kuppl 0 "Init" 255 "Fehler" ;
VAL_ 260 HMS_Konsistenz_HVLM 0 "kein_Fehler_erkannt" 1 "Fehler_erkannt" ;
VAL_ 260 HMS_Systemstatus 0 "keine_Funktion_aktiv" 1 "Halten_aktiv" 2 "Parken_angefordert" 3 "Parken_aktiv" 4 "Parken_beibehalten_aktiv" 5 "Anfahren_aktiv" 6 "Loeseanforderung_aktiv" 7 "Loeseanforderung_durch_Fahrer" 8 "Abrutschen_erkannt" 9 "Halten_Standby_aktiv" 10 "Anfahren_Standby_aktiv" 14 "Init" 15 "Fehler" ;
VAL_ 260 EPB_Anfahrwunsch_erkannt 0 "kein Anfahrwunsch erkannt" 1 "Anfahrwunsch erkannt" ;
VAL_ 260 EPB_DAA_Randbed_erf 0 "Randbed_nicht_erfuellt" 1 "Randbed_erfuellt" ;
VAL_ 260 EPB_Fehlerstatus 0 "kein_Fehler_in_EPB__AVH_darf_von_ESP_ausgefuehrt_werden" 1 "temporaer_nicht_verfuegbar_Grund_1" 2 "temporaer_nicht_verfuegbar_Grund_2" 3 "Fehler_in_EPB__AVH_darf_von_ESP_nicht_ausgefuehrt_werden" ;
VAL_ 260 EPB_Schalterposition 0 "keine Fahreranforderung" 1 "Fahreranforderung Öffnen" 2 "Fahreranforderung Schließen" 3 "Fehler" ;
VAL_ 260 EPB_QBit_Schalterpos 0 "gültiger Wert (volle Funktion)" 1 " Ersatz-, Init- oder Fehlerwert (Schalter ausser Funktion)" ;
VAL_ 260 EPB_Konsistenz_ACC 0 "kein Fehler erkannt" 1 "Fehler erkannt" ;
VAL_ 260 EPB_Spannkraft 30 "Init" 31 "Fehler" ;
VAL_ 260 EPB_Status 0 "offen" 1 "Bremse_geschl_(Spannkraft_voll/reduziert)" 2 "Aktuator_im_Lauf" 3 "Fehler_oder_unbekannt" ;
VAL_ 260 EPB_KD_Fehler 0 "kein_KD_Fehler" 1 "KD_Fehler" ;
VAL_ 781 EPB_Fehlerlampe_Gelb 0 "Aus" 1 "Ein" ;
VAL_ 781 EPB_Fehlerlampe_BKL 0 "BKL aus" 1 "BKL an" ;
VAL_ 781 EPB_Funktionslampe 0 "Aus" 1 "Ein" ;
VAL_ 781 EPB_Texte 0 "keine_Anzeige" 1 "Neigungswinkel_zu_gross" 2 "Parkbremse_von_Hand_oeffnen" 3 "HU_Modus_oder_EPB_in_Diagnose" 4 "Bremspedal_betaetigen" 5 "tbd" 6 "tbd" 7 "Stoerung_Anfahrassistent" 8 "Abschleppschutz_blockiert" 9 "Feststellbremse_nicht_automatisch_geschlossen" 10 "Parkbremse_loesen_nicht_moeglich_Ladekabel_gesteckt" 11 "Notbremsung_ueber_EPB_Taster" 12 "Parkbremse_angezogen" ;
VAL_ 781 EPB_Akustik 0 "Warnton aus" 1 "Warnton an" ;
VAL_ 781 EPB_Autoholdlampe 0 "Lampe aus (Autohold inaktiv)" 1 "Lampe ein (Autohold aktiv)" ;
VAL_ 781 EPB_Bremsbelag_Warn 0 "Bremsbelag_ok" 1 "Bremsbelag_unter_Minimum" ;
VAL_ 781 EPB_Fehlermeldungen 0 "keine_Anzeige" 1 "Systemstoerung_Kl15an" 2 "Systemstoerung_Kl15aus" 3 "Parkbremse_betaetigen" 4 "Systemstoerung_Hanghaltefaehigkeit" 5 "Funktionseinschraenkung_Kl15an" 6 "Funktionseinschraenkung_Kl15aus" 7 "HU_Modus_aktiv" 8 "Transportmodus" 9 "Produktionsmodus" ;
VAL_ 256 ASR_Moment_langsam 1022 "Init" 1023 "Fehler" ;
VAL_ 256 ASR_MSR_Moment_schnell 1022 "Init" 1023 "Fehler" ;
VAL_ 256 ESP_v_Signal 65533 "Unterspannung" 65534 "Init" 65535 "Fehler" ;
VAL_ 256 ASR_Tastung_passiv 0 "ASR_aktiviert" 1 "ASR_passiv_getastet_oder_Schwellen_geaendert" ;
VAL_ 256 ESP_Tastung_passiv 0 "ESP_aktiviert" 1 "ESP_passiv_getastet_oder_Schwellen_geaendert" ;
VAL_ 256 ESP_Systemstatus 0 "iO" 1 "Fehler" ;
VAL_ 256 ASR_Schalteingriff 0 "keine_Anforderung" 1 "ASR_Schaltkennfeld" 2 "Rueckschaltung" 3 "Schaltverbot" ;
VAL_ 256 OBD_Schlechtweg 0 "kein_Schlechtweg_erkannt" 1 "Schlechtweg_erkannt" ;
VAL_ 256 OBD_QBit_Schlechtweg 0 "gueltiger_Wert" 1 "Ersatz_Init_oder_Fehlerwert" ;
VAL_ 256 ESP_QBit_v_Signal 0 "gueltiger_Wert" 1 "Ersatz_Init_oder_Fehlerwert" ;
VAL_ 256 ABS_Bremsung 0 "keine_ABS_Regelung" 1 "ABS_Regelung_aktiv" ;
VAL_ 256 ASR_Anf 0 "keine_Anforderung" 1 "ASR_Anforderung" ;
VAL_ 256 MSR_Anf 0 "keine Anfoderung" 1 "MSR-Anforderung" ;
VAL_ 256 EBV_Eingriff 0 "kein_EBV_Eingriff" 1 "EBV_Eingriff" ;
VAL_ 256 EDS_Eingriff 0 "kein_EDS_Eingriff" 1 "EDS_Eingriff" ;
VAL_ 256 ESP_Eingriff 0 "kein_ESP_Eingriff" 1 "ESP_Eingriff_aktiv" ;
VAL_ 256 ESP_ASP 0 "inaktiv" 1 "aktiv" ;
VAL_ 256 ESP_KD_Fehler 0 "kein_KD_Fehler" 1 "KD_Fehler" ;
VAL_ 257 ESP_QBit_Gierrate 0 "gueltiger_Wert" 1 "Ersatz_Init_oder_Fehlerwert" ;
VAL_ 257 ESP_QBit_Laengsbeschl 0 "gueltiger_Wert" 1 "Ersatz_Init_oder_Fehlerwert" ;
VAL_ 257 ESP_QBit_Querb 0 "gueltiger_Wert" 1 "Ersatz_Init_oder_Fehlerwert" ;
VAL_ 257 ESP_Stillstandsflag 0 "kein_Stillstand_erkannt" 1 "Stillstand_erkannt" ;
VAL_ 257 ESP_Querbeschleunigung 255 "Fehler" ;
VAL_ 257 ESP_Laengsbeschl 1022 "Signal_nicht_vorhanden" 1023 "Fehler" ;
VAL_ 257 ESP_Verteil_Wankmom 30 "Init" 31 "Fehler" ;
VAL_ 257 ESP_QBit_Anf_Vert_Wank 0 "gueltiger_Wert" 1 "Ersatz_Init_oder_Fehlerwert" ;
VAL_ 257 ESP_Gierrate 16383 "Fehler" ;
VAL_ 257 ESP_VZ_Gierrate 0 "positiv" 1 "negativ" ;
VAL_ 257 ESP_Notbremsanzeige 0 "keine_Notbremsung_erkannt" 1 "Notbremsung_erkannt" ;
VAL_ 257 ESP_SpannungsAnf 0 "keine_Anforderung" 1 "Anforderung_Spannungswert_1" ;
VAL_ 257 ESP_PLA_Abbruch 0 "Init" 1 "Geschwindigkeitsueberschreitung" 2 "Falscher_PLA_Status" 3 "Deaktivierung_durch_Abbruch_Lenkung" 4 "PLA_Bremsanforderung_nach_Stillstand" 5 "Abbruch_durch_Kl15_aus" 6 "Abbruch_durch_FT_offen" ;
VAL_ 257 ESP_Status_ESP_PLA 0 "ESP_PLA_deaktiv" 1 "ESP_PLA_Init" 2 "ESP_PLA_Fehler" 4 "ESP_PLA_aktivierbar" 6 "ESP_PLA_Bremse_aktiv" 8 "ESP_PLA_funktionsbereit" 9 "ESP_PLA_Neustart" 10 "ESP_PLA_Abbruch" ;
VAL_ 259 ESP_VL_FR 0 "Vorwaerts" 1 "Rueckwaerts" ;
VAL_ 259 ESP_VR_FR 0 "Vorwaerts" 1 "Rueckwaerts" ;
VAL_ 259 ESP_HL_FR 0 "Vorwaerts" 1 "Rueckwaerts" ;
VAL_ 259 ESP_HR_FR 0 "Vorwaerts" 1 "Rueckwaerts" ;
VAL_ 259 ESP_VL_Radgeschw 4093 "Unterspannung" 4094 "Init" 4095 "Fehler" ;
VAL_ 259 ESP_VR_Radgeschw 4093 "Unterspannung" 4094 "Init" 4095 "Fehler" ;
VAL_ 259 ESP_HL_Radgeschw 4093 "Unterspannung" 4094 "Init" 4095 "Fehler" ;
VAL_ 259 ESP_HR_Radgeschw 4093 "Unterspannung" 4094 "Init" 4095 "Fehler" ;
VAL_ 776 ESP_Meldungen 0 "keine_Anzeige_kein_Gong" 1 "Autohold_Hinweis_1_und_kein_Gong" 2 "Stoerung_Autohold_und_1x_Gong" 3 "Stoerung_Hillholder_und_1x_Gong" 4 "Uebernehmen_und_1x_Gong" ;
VAL_ 776 ESP_HDC_FktLampe 0 "Aus" 1 "Ein" ;
VAL_ 776 ESP_Lampe 0 "Aus" 1 "Ein" ;
VAL_ 776 ABS_Lampe 0 "Aus" 1 "Ein" ;
VAL_ 776 BK_Lampe 0 "Aus" 1 "Ein" ;
VAL_ 776 ESP_Akustik 0 "keine_Akustik" 1 "1x_Beep" ;
VAL_ 776 ESP_Diagnose 0 "ESP_nicht_in_Diagnose" 1 "ESP_in_Diagnose" ;
VAL_ 776 ESP_Textanzeigen_02 0 "kein_Text" 1 "ESP_Stoerung" 2 "ABS_Stoerung" 3 "ESP_ABS_Stoerung" 4 "Werkstatt_Bremse" 5 "ASR_Stoerung" 6 "ESP_switched_off" 7 "ASR_off" 8 "ESP_ASR_on" 9 "Stoerung_Hillholder" 10 "keine_Bremskraftverstaerkung" 11 "ASR_aktiviert" 12 "ABS_ASR_Stoerung" 13 "bitte_Reifen_pruefen" 14 "Stoerung_Autohold" 15 "ESP_offroad" 16 "Autohold_Hinweis_1" 17 "ESP_sport" 18 "ESP_Zwangsaktivierung" 19 "ESP_Taster_Info" 20 "reserviert_fuer_TC_aktiv" 21 "Verlassenswarnung" 22 "reserviert_fuer_TC_switched_off" 23 "Verlwarn_akt_Rollsicherung_inakt" ;
VAL_ 776 ESP_Off_Lampe 0 "Lampe_aus" 1 "Lampe_ein" ;
VAL_ 776 ESP_m_Raddrehz 32765 "Unterspannung" 32766 "Init" 32767 "Fehler" ;
VAL_ 776 ESP_ASR_Lampe 0 "ESP_ASR_Lampe_aus" 1 "ESP_ASR_Lampe_an" ;
VAL_ 776 ESP_Fehlerstatus_Wegimp 0 "Wegimpulse_iO" 1 "Fehler" ;
VAL_ 776 ESP_Wegimp_Ueberlauf 0 "Reset_und_kein_Ueberlauf" 1 "mindestens_1x_Ueberlauf" ;
VAL_ 776 ESP_QBit_Wegimp_VA 0 "gueltiger_Wert" 1 "Ersatz_Init_oder_Fehlerwert" ;
VAL_ 776 ESP_Displaywarnungen 0 "keine_Warnung" 1 "BKL_Display_Warnung" 2 "Verlassenswarnung" 3 "Verlwarn_akt_Rollsicherung_inakt" ;
VAL_ 776 ESP_HDC_Regelgeschw 0 "nicht_verbaut" 125 "HDC_Standby" 126 "Init" 127 "Fehler" ;
VAL_ 776 ESP_BKV_Warnung 0 "keine_Anzeige" 1 "keine_Bremskraftverstaerkung" ;
VAL_ 262 ESP_QBit_Bremsdruck 0 "gueltiger_Wert" 1 "Ersatz_Init_oder_Fehlerwert" ;
VAL_ 262 ESP_QBit_Fahrer_bremst 0 "gueltiger_Wert" 1 "Ersatz_Init_oder_Fehlerwert" ;
VAL_ 262 ESP_Schwelle_Unterdruck 0 "kein_Signal" 1 "Unterdruck_kleiner_gleich_450_mbar" 2 "Unterdruck_groesser_450_mbar" 3 "Fehler_Unterdrucksensor" ;
VAL_ 262 ESP_Bremsdruck 1023 "Fehler" ;
VAL_ 262 ESP_Fahrer_bremst 0 "Bremsdruckschwelle_nicht_ueberschritten" 1 "Bremsdruckschwelle_ueberschritten" ;
VAL_ 262 ESP_Verz_TSK_aktiv 0 "TSK_Verzoegerung_inaktiv" 1 "TSK_Verzoegerung_aktiv" ;
VAL_ 262 ESP_Lenkeingriff_ADS 0 "kein_Lenkeingriff" 1 "stabilisierender_Lenkeingriff" ;
VAL_ 262 ESP_Konsistenz_TSK 0 "Botschaft_fuer_Verzoegerungsanforderung_konsistent" 1 "Botschaft_fuer_Verzoegerungsanforderung_nicht_konsistent" ;
VAL_ 262 ESP_Bremsruck_AWV2 0 "kein_Bremsruck_ausgefuehrt" 1 "Bremsruck_ausgefuehrt" ;
VAL_ 262 ESP_Konsistenz_AWV2 0 "Botschaft_fuer_AWV2_konsistent" 1 "Botschaft_fuer_AWV2_nicht_konsistent" ;
VAL_ 262 ECD_Fehler 0 "ECD_iO" 1 "ECD_Fehler" ;
VAL_ 262 ECD_nicht_verfuegbar 0 "ECD_Funktion_verfuegbar" 1 "ECD_Funktion_nicht_verfuegbar" ;
VAL_ 262 ESP_Status_Bremsentemp 0 "Bremse_nicht_ueberhitzt" 1 "Bremse_ueberhitzt" ;
VAL_ 262 ESP_Autohold_Standby 0 "Autohold_nicht_im_Standby" 1 "Autohold_im_Standby" ;
VAL_ 262 ESP_HDC_Standby 0 "HDC_Funktion_nicht_im_Standby" 1 "HDC_Funktion_im_Standby" ;
VAL_ 262 ESP_HBA_aktiv 0 "HBA_nicht_aktiv" 1 "HBA_aktiv" ;
VAL_ 262 ESP_Prefill_ausgeloest 0 "nicht_ausgeloest" 1 "Prefill_ausgeloest" ;
VAL_ 262 ESP_Rueckwaertsfahrt_erkannt 0 "keine_Rueckwaetsfahrt" 1 "Rueckwaertsfahrt_sicher_erkannt" ;
VAL_ 262 ESP_Status_Anfahrhilfe 0 "Aus" 1 "Ein" ;
VAL_ 262 ESP_HDC_aktiv 0 "inaktiv" 1 "aktiv" ;
VAL_ 262 ESP_StartStopp_Info 0 "Motorlauf_nicht_notwendig_(Stoppfreigabe)" 1 "Motoranlauf_nicht_zwingend_notwendig_(Stoppverbot,keine_Startanforderung)" 2 "Motoranlauf_zwingend_notwendig_(Startanforderung)" 3 "Systemfehler" ;
VAL_ 262 ESP_Eingr_HL 0 "kein_Eingriff" 1 "ESP_Eingriff_HL" ;
VAL_ 262 ESP_Eingr_HR 0 "kein_Eingriff" 1 "ESP_Eingriff_HR" ;
VAL_ 262 ESP_Eingr_VL 0 "kein_Eingriff" 1 "ESP_Eingriff_VL" ;
VAL_ 262 ESP_Eingr_VR 0 "kein_Eingriff" 1 "ESP_Eingriff_VR" ;
VAL_ 262 ESP_BKV_Unterdruck 0 "nicht_verbaut_oder_nicht_kodiert" 254 "Init" 255 "Fehler" ;
VAL_ 262 ESP_Autohold_aktiv 0 "Autohold_inaktiv" 1 "Autohold_aktiv" ;
VAL_ 262 ESP_FStatus_Anfahrhilfe 0 "kein_Fehler" 1 "Fehler" ;
VAL_ 262 ESP_Verz_EPB_aktiv 0 "nicht_aktiviert" 1 "aktiviert" ;
VAL_ 262 ECD_Bremslicht 0 "Aus" 1 "Ein" ;
VAL_ 262 ESP_Verzoeg_EPB_verf 0 "nicht_verfuegbar" 1 "System_verfuegbar" ;
VAL_ 262 ESP_Status_Bremsdruck 0 "Bremse_drucklos" 1 "mit_Bremsdruck" ;
VAL_ 262 ESP_Anforderung_EPB 0 "keine_Anforderung" 1 "Anforderung_Oeffnen" 2 "Anforderung_Schliessen" 3 "reserviert" ;
VAL_ 132 ESP_06_KD_Fehler 0 "kein_KD_Fehler" 1 "KD_Fehler" ;
VAL_ 132 ESP_VZ_Teilsollwinkel 0 "positiv" 1 "negativ" ;
VAL_ 132 ESP_Winkeleingriff 0 "kein Eingriff" 1 "Eingriff mit langsamer Rückführung" 2 "Eingriff mit mittlerer Rückführung" 3 "Eingriff mit schneller Rückführung" ;
VAL_ 132 ESP_Status_ADS 0 "ADS iO" 1 "ADS noch nicht verfügbar" 2 "ADS temporär nicht verfügbar" ;
VAL_ 132 ESP_v_ref 4093 "Unterspannung" 4094 "Init" 4095 "Fehler" ;
VAL_ 132 ESP_Monitoring_Gierrate 0 "nicht_kalibriert" 1 "Level_0" 2 "Level_1" 3 "Level_2" 4 "Level_3" 5 "Level_4" 6 "Init" 7 "Fehler" ;
VAL_ 132 ESP_Monitoring_Laengsb 0 "nicht_kalibriert" 1 "Level_0" 2 "Level_1" 3 "Level_2" 4 "Level_3" 5 "Level_4" 6 "Init" 7 "Fehler" ;
VAL_ 132 ESP_Monitoring_Lenkwinkel 0 "nicht_kalibriert" 1 "Level_0" 2 "Level_1" 3 "Level_2" 4 "Level_3" 5 "Level_4" 6 "Init" 7 "Fehler" ;
VAL_ 132 ESP_Monitoring_Querb 0 "nicht_kalibriert" 1 "Level_0" 2 "Level_1" 3 "Level_2" 4 "Level_3" 5 "Level_4" 6 "Init" 7 "Fehler" ;
VAL_ 914 ESP_ACC_LDE 0 "Lebensdauerende_nicht_erreicht" 1 "Lebensdauerende_erreicht" ;
VAL_ 914 ESP_Quattro_Antrieb 0 "Front" 1 "Allrad" ;
VAL_ 914 ESP_Codierung_ADS 0 "Init" 1 "ESP_nicht_ADS_codiert" 2 "ADS_codiert" 3 "tbd" ;
VAL_ 914 ESP_RTA_HL 254 "Abgleich_nocht_nicht_genuegend_konvergent" 255 "Fehler" ;
VAL_ 914 ESP_RTA_HR 254 "Abgleich_nocht_nicht_genuegend_konvergent" 255 "Fehler" ;
VAL_ 914 ESP_RTA_VR 254 "Abgleich_nocht_nicht_genuegend_konvergent" 255 "Fehler" ;
VAL_ 914 OBD_Fehler_Radsensor_HL 0 "kein Fehler / Init / nicht verbaut" 1 "KS- (Kurzschluss nach minus)" 2 "KS+ (Kurzschluss nach plus)" 3 "OC (Leitungsunterbrechung)" 4 "OOR+ (Signal zu gross)" 5 "OOR- (Signal zu klein)" 6 "RC+ (Signal unplausibel zu gross)" 7 "RC- (Signal unplausibel zu klein)" 8 "KS+/OC (Kurzschluss nach plus/Unterbrechung)" 9 "KS-/OC  (Kurzschluss nach minus/Unterbrechung)" 10 "KS-/KS+  (Kurzschluss nach minus/plus)" 11 "KS-/KS+/OC (Kurzschluss nach minus/plus/Unterbrechung)" 12 "frei" 13 "frei" 14 "frei" 15 "frei" ;
VAL_ 914 OBD_Fehler_Radsensor_HR 0 "kein Fehler / Init / nicht verbaut" 1 "KS- (Kurzschluss nach minus)" 2 "KS+ (Kurzschluss nach plus)" 3 "OC (Leitungsunterbrechung)" 4 "OOR+ (Signal zu gross)" 5 "OOR- (Signal zu klein)" 6 "RC+ (Signal unplausibel zu gross)" 7 "RC- (Signal unplausibel zu klein)" 8 "KS+/OC (Kurzschluss nach plus/Unterbrechung)" 9 "KS-/OC  (Kurzschluss nach minus/Unterbrechung)" 10 "KS-/KS+  (Kurzschluss nach minus/plus)" 11 "KS-/KS+/OC (Kurzschluss nach minus/plus/Unterbrechung)" 12 "frei" 13 "frei" 14 "frei" 15 "frei" ;
VAL_ 914 OBD_Fehler_Radsensor_VL 0 "kein Fehler / Init / nicht verbaut" 1 "KS- (Kurzschluss nach minus)" 2 "KS+ (Kurzschluss nach plus)" 3 "OC (Leitungsunterbrechung)" 4 "OOR+ (Signal zu gross)" 5 "OOR- (Signal zu klein)" 6 "RC+ (Signal unplausibel zu gross)" 7 "RC- (Signal unplausibel zu klein)" 8 "KS+/OC (Kurzschluss nach plus/Unterbrechung)" 9 "KS-/OC  (Kurzschluss nach minus/Unterbrechung)" 10 "KS-/KS+  (Kurzschluss nach minus/plus)" 11 "KS-/KS+/OC (Kurzschluss nach minus/plus/Unterbrechung)" 12 "frei" 13 "frei" 14 "frei" 15 "frei" ;
VAL_ 914 OBD_Fehler_Radsensor_VR 0 "kein Fehler / Init / nicht verbaut" 1 "KS- (Kurzschluss nach minus)" 2 "KS+ (Kurzschluss nach plus)" 3 "OC (Leitungsunterbrechung)" 4 "OOR+ (Signal zu gross)" 5 "OOR- (Signal zu klein)" 6 "RC+ (Signal unplausibel zu gross)" 7 "RC- (Signal unplausibel zu klein)" 8 "KS+/OC (Kurzschluss nach plus/Unterbrechung)" 9 "KS-/OC  (Kurzschluss nach minus/Unterbrechung)" 10 "KS-/KS+  (Kurzschluss nach minus/plus)" 11 "KS-/KS+/OC (Kurzschluss nach minus/plus/Unterbrechung)" 12 "frei" 13 "frei" 14 "frei" 15 "frei" ;
VAL_ 914 ESP_Qualifizierung_Antriebsart 0 "alte_Bedeutung_Bit_ESP_Allrad_Antrieb" 1 "neue_Bedeutung_Bit_ESP_Allrad_Antrieb" ;
VAL_ 914 ESP_Offroad_Modus 0 "kein_ESP_Offroadmodus" 1 "ESP_Offroadmodus" ;
VAL_ 914 ESP_MKB_ausloesbar 0 "Multikollisionsbremsung_nicht_freigeschaltet" 1 "Multikollisionsbremsung_freigeschaltet" ;
VAL_ 914 ESP_Stat_FallBack_eBKV 0 "Rueckfallebene_nicht_vorhanden" 1 "Rueckfallebene_vorhanden" ;
VAL_ 914 ESP_CM_Variante 0 "Standard" 1 "Erweitert" ;
VAL_ 914 ESP_OBD_Status 0 "MIL_aus" 1 "MIL_ein" ;
VAL_ 914 ESP_Rollenmodus_Deaktivieren 0 "keine_Aenderung" 1 "Abbruch" ;
VAL_ 914 ESP_nachtr_Stopp_Anf 0 "nicht_angefordert" 1 "angefordert" ;
VAL_ 169 ESP_Eingriffsmoment 1022 "Init" 1023 "Fehler" ;
VAL_ 169 ESP_Antrieb_Anf 0 "keine_Anforderung" 1 "Nachbildung_konv_Antrieb" ;
VAL_ 169 ESP_Reku_Anf 0 "keine_Reku_Anforderung" 1 "Reku_Anforderung" ;
VAL_ 169 ESP_Bremspedalweg 0 "Sensor_nicht_verbaut" 252 "reserviert" 253 "reserviert" 254 "Init" 255 "Fehler" ;
VAL_ 169 ESP_Reku_Index 0 "Rekuperation_verboten" 253 "Rekuperation_erlaubt" 254 "Init" 255 "Fehler" ;
VAL_ 169 ESP_Reku_Limit 510 "Init" 511 "Fehler" ;
VAL_ 169 ESP_Haltebestaetigung 0 "kein_sicheres_Halten" 1 "sicheres_Halten" ;
VAL_ 169 ESC_Motorstartverzoegerung 0 "Startfreigabe" 1 "Anforderung_Startverzoegerung" ;
VAL_ 169 ESP_KD_OBD_Readiness 0 "Diagnoseergebnis im aktuellen driving cycle ermittelt" 1 "KEIN Diagnoseergebnis im aktuellen driving cycle ermittelt" ;
VAL_ 169 ESP_KD_OBD_Fehler 0 "Summenfehler_passiv_letzte_Diagnoseergebnis_PASS" 1 "Summenfehler_aktiv_letzte_Diagnoseergebnis_FAIL" ;
VAL_ 1623 ESP_BremsenTemp_hinten 0 "Temp_kleiner_99GradC" 1 "Temp_zwischen_100-199GradC" 2 "Temp_zwischen_200-299GradC" 3 "Temp_zwischen_300-399GradC" 4 "Temp_zwischen_400-499GradC" 5 "Temp_zwischen_500-599GradC" 6 "Temp_groesser_599GradC" 7 "Fehler" ;
VAL_ 924 BCM1_02_alt 0 "aktuell" 1 "veraltet" ;
VAL_ 924 Wischer_01_alt 0 "aktuell" 1 "veraltet" ;
VAL_ 924 Klima_02_alt 0 "aktuell" 1 "veraltet" ;
VAL_ 924 BCM1_01_alt 0 "aktuell" 1 "veraltet" ;
VAL_ 924 ESP_07_alt 0 "aktuell" 1 "veraltet" ;
VAL_ 924 TSG_BT_1_alt 0 "aktuell" 1 "veraltet" ;
VAL_ 924 TSG_HL_1_alt 0 "aktuell" 1 "veraltet" ;
VAL_ 924 TSG_HR_1_alt 0 "aktuell" 1 "veraltet" ;
VAL_ 924 Motor_02_alt 0 "aktuell" 1 "veraltet" ;
VAL_ 924 Klima_Sensor_02_alt 0 "aktuell" 1 "veraltet" ;
VAL_ 924 TSG_FT_1_alt 0 "aktuell" 1 "veraltet" ;
VAL_ 924 Motor_05_alt 0 "aktuell" 1 "veraltet" ;
VAL_ 924 QSP_01_alt 0 "aktuell" 1 "veraltet" ;
VAL_ 924 Parkhilfe_01_alt 0 "aktuell" 1 "veraltet" ;
VAL_ 924 Fahrwerk_02_alt 0 "aktuell" 1 "veraltet" ;
VAL_ 924 BCM1_MH_WIV_Schalter 0 "MH_geschlossen" 1 "MH_offen" ;
VAL_ 924 Wischer_vorne_aktiv 1 "Wischer vorne läuft" ;
VAL_ 924 BCM1_Rueckfahrlicht_Schalter 0 "nicht_betaetigt" 1 "betaetigt" ;
VAL_ 924 MO_Status_Normalbetrieb_01 0 "kein_Normalbetrieb" 1 "Normalbetrieb_erreicht" ;
VAL_ 924 KL_Zuheizer_Freigabe 0 "keine_Freigabe_Zuheizer" 1 "Zuheizerfreigabe" ;
VAL_ 924 BCM1_Vorwaertsgang_eingelegt 0 "Rueckwaertsgang bzw. restliche Gaenge eingelegt" 1 "Erster oder zweiter Gang eingelegt" ;
VAL_ 924 ESP_Codierung_ADS 0 "Init" 1 "ESP_nicht_ADS_codiert" 2 "ADS_codiert" 3 "tbd" ;
VAL_ 924 QSP_StartStopp_Info 0 "Motorlauf_nicht_notwendig_(Stoppfreigabe)" 1 "Motoranlauf_nicht_zwingend_notwendig_(Stoppverbot,keine_Startanforderung)" 2 "Motoranlauf_zwingend_notwendig_(Startanforderung)" 3 "Systemfehler" ;
VAL_ 924 FA_StartStopp_Info 0 "Motorlauf_nicht_notwendig_(Stoppfreigabe)" 1 "Motoranlauf_nicht_zwingend_notwendig_(Stoppverbot,keine_Startanforderung)" 2 "Motoranlauf_zwingend_notwendig_(Startanforderung)" 3 "Systemfehler" ;
VAL_ 924 PH_StartStopp_Info 0 "Motorlauf_nicht_notwendig_(Stoppfreigabe)" 1 "Motoranlauf_nicht_zwingend_notwendig_(Stoppverbot,keine_Startanforderung)" 2 "Motoranlauf_zwingend_notwendig_(Startanforderung)" 3 "Systemfehler" ;
VAL_ 924 KL_Beschlagsgefahr 0 "keine_Beschlagsgefahr" 1 "Beschlagsgefahr" ;
VAL_ 924 BCM1_GLW_Fernlicht_Anf 0 "Aus" 1 "Ein" ;
VAL_ 924 BCM1_RFahrlicht_Fzg_Anf 0 "Licht_nicht_angefordert" 1 "Licht ist einzuschalten" ;
VAL_ 924 FT_Tuer_geoeffnet 1 "Tuer offen" ;
VAL_ 924 MO_Handshake_STH 0 "keine EKP-Ansteuerung durch STH-Anforderung" 1 "EKP-Ansteuerung durch STH-Anforderung" ;
VAL_ 924 FT_Sperrklinke 0 "Schloss_in_Vorraste_und_Hauptraste" 1 "Tuer_auf_oder_Tuer_Position_zwischen_Vor_und_Hauptraste" ;
VAL_ 924 BCM1_OBD_FStatus_ATemp 0 "kein Fehler / Init / nicht verbaut" 1 "KS- (Kurzschluss nach minus)" 2 "KS+ (Kurzschluss nach plus)" 3 "OC (Leitungsunterbrechung)" 4 "OOR+ (Signal zu gross)" 5 "OOR- (Signal zu klein)" 6 "RC+ (Signal unplausibel zu gross)" 7 "RC- (Signal unplausibel zu klein)" 8 "KS+/OC (Kurzschluss nach plus/Unterbrechung)" 9 "KS-/OC  (Kurzschluss nach minus/Unterbrechung)" 10 "KS-/KS+  (Kurzschluss nach minus/plus)" 11 "KS-/KS+/OC (Kurzschluss nach minus/plus/Unterbrechung)" 12 "frei" 13 "frei" 14 "frei" 15 "frei" ;
VAL_ 924 BCM1_Aussen_Temp_ungef 253 "nicht_verbaut" 254 "Initwert" 255 "Fehler" ;
VAL_ 924 BCM1_Oeldruck_Schalter 0 "offen" 1 "geschlossen (p > p soll)" ;
VAL_ 924 BCM1_Oeldruck_Schalter_2 0 "offen" 1 "geschlossen" ;
VAL_ 924 BT_Tuer_geoeffnet 1 "Tuer_offen" ;
VAL_ 924 HL_Tuer_geoeffnet 1 "Tuer geoeffnet" ;
VAL_ 924 HR_Tuer_geoeffnet 1 "Tuer offen" ;
VAL_ 924 BCM1_Adaptive_Lichtvert_Anf 0 "Aus" 1 "Ein" ;
VAL_ 924 BCM1_Gleitende_Leuchtw_Anf 0 "Aus" 1 "Ein" ;
VAL_ 924 BCM1_Schalter_StartStopp 0 "Start_Stopp_ueber_Hauptschalter_deaktiviert" 1 "Start_Stopp_ueber_Hauptschalter_aktiviert" ;
VAL_ 924 ESP_Offroad_Modus 0 "kein_ESP_Offroadmodus" 1 "ESP_Offroadmodus" ;
VAL_ 924 MO_Freig_Reku 0 "Rekuperations-Modus aus" 1 "Empfehlung Spannungsanhebung" 2 "Empfehlung Spannungsabsenkung" 3 "Rekuperationsmodus aktiv, Spannungsvariation nicht notwendig" ;
VAL_ 924 KL_HSH_ein_Soll 0 "Fahrerwunsch_HSH_aus" 1 "Fahrerwunsch_HSH_ein" ;
VAL_ 924 FT_Tuerkontakt_Rohsignal 0 "Schalter_geschlossen_Tuer_auf" 1 "Schalter_offen_Tuer_zu" ;
VAL_ 924 FT_TD_Taste 1 "Tankdeckelentriegelungs Taster gedrückt" ;
VAL_ 924 FT_TD_Taste_Fehler 0 "iO" 1 "defekt" ;
VAL_ 924 PH_nachtr_Stopp_Anf 0 "nicht_angefordert" 1 "angefordert" ;
VAL_ 1604 SMLS_01_alt 0 "aktuell" 1 "veraltet" ;
VAL_ 1604 BCM1_01_alt 0 "aktuell" 1 "veraltet" ;
VAL_ 1604 BCM1_02_alt 0 "aktuell" 1 "veraltet" ;
VAL_ 1604 BCM2_02_alt 0 "aktuell" 1 "veraltet" ;
VAL_ 1604 HYB_Anf_E_Mode_alt 0 "aktuell" 1 "veraltet" ;
VAL_ 1604 BCM1_04_alt 0 "aktuell" 1 "veraltet" ;
VAL_ 1604 ESP_04_alt 0 "aktuell" 1 "veraltet" ;
VAL_ 1604 Kessy_01_alt 0 "aktuell" 1 "veraltet" ;
VAL_ 1604 Lift_01_alt 0 "aktuell" 1 "veraltet" ;
VAL_ 1604 BH_Blinker_li 0 "nicht_betaetigt" 1 "Blinkerhebel_Richtung_links_betaetigt" ;
VAL_ 1604 BH_Blinker_re 0 "nicht_betaetigt" 1 "Blinkerhebel_Richtung_rechts_betaetigt" ;
VAL_ 1604 BM_Autobahn 0 "inaktiv" 1 "aktiv" ;
VAL_ 1604 BH_Fernlicht 0 "nicht_betaetigt" 1 "Blinkerhebel_in_Richtung_Fernlicht_betaetigt" ;
VAL_ 1604 BH_Lichthupe 0 "nicht_betaetigt" 1 "Blinkerhebel in Richtung Lichthupe betaetigt" ;
VAL_ 1604 BCM1_MH_Schalter 0 "MH_geschlossen" 1 "MH_offen" ;
VAL_ 1604 HYB_Anf_E_Mode 0 "Taster_nicht_betaetigt" 1 "Taster_betaetigt" ;
VAL_ 1604 HUD_NV_in_Anzeige 0 "NV_nicht_in_Anzeige" 1 "NV_in_Anzeige" ;
VAL_ 1604 BCM1_Touristen_Licht_Anf 0 "Licht_nicht_angefordert" 1 "Anforderung von Touristenlicht" ;
VAL_ 1604 LV_Abblendlicht_li_def 0 "OK" 1 "defekt" ;
VAL_ 1604 LV_Abblendlicht_re_def 0 "OK" 1 "defekt" ;
VAL_ 1604 LV_Abblendlicht_Anzeige 0 "nicht aktiv" 1 "aktiv" ;
VAL_ 1604 LV_AFL_aktiv_Anzeige 0 "nicht aktiv" 1 "aktiv" ;
VAL_ 1604 BCM1_Licht_Dunkelheit_aktiv 1 "Licht wegen Dunkelheit aktiv, nicht bei Autobahnlicht, Tagfahrlicht oder Regenlicht" ;
VAL_ 1604 LV_Nebelschlusslicht_Anzeige 0 "nicht aktiv" 1 "aktiv" ;
VAL_ 1604 BCM1_Linksverkehr 0 "Rechtsverkehr" 1 "Linksverkehr" ;
VAL_ 1604 BCM2_P_verriegelt 0 "WH nicht in Stellung P" 1 "WH in Stellung P" ;
VAL_ 1604 BCM1_LDS_Stellung 0 "Init" 1 "Stellung_0" 2 "Auto" 3 "Standlicht" 4 "Abblendlicht" 7 "Fehler" ;
VAL_ 1604 BCM1_Allwetterlicht_Anf 0 "Licht_nicht_angefordert" 1 "Licht_ist_einzuschalten" ;
VAL_ 1604 HUD_Anzeigefehler_NV 0 "kein_Fehler" 1 "Anzeigefehler" ;
VAL_ 1604 ESP_Diagnose 0 "ESP_nicht_in_Diagnose" 1 "ESP_in_Diagnose" ;
VAL_ 1604 BCM1_SRA_aktiv 0 "nicht aktiv" 1 "aktiv" ;
VAL_ 1604 FFB_Auf_Taste 0 "Taste_nicht_betaetigt" 1 "Oeffnentaste_betaetigt" ;
VAL_ 1604 FFB_CarFinder 0 "nicht aktiv" 1 "aktiv" ;
VAL_ 1604 ZV_verriegelt_extern_ist 1 "Fahrzeug_aussen_verriegelt_Istzustand" ;
VAL_ 1604 BCM_Tankwunsch 0 "Fehler_keine_Drucktankfunktionalitaet" 1 "keine_Betankung_erwuenscht" 2 "Betankung_erwuenscht" ;
VAL_ 1604 ZV_Tankklappe_offen 0 "Tankklappe_geschlossen" 1 "Tankklappe_offen" ;
VAL_ 130 GE_Schaltvorgang 0 "keine Schaltung" 1 "Schaltung aktiv" ;
VAL_ 130 GE_Status_Kupplung 0 "Kupplung geöffnet" 1 "Kupplung geregelt" 2 "Kupplung geschlossen" 3 "Fehler" ;
VAL_ 130 GE_Verbot_Ausblendung 0 "kein_Verbot" 1 "Verbot" ;
VAL_ 130 GE_MMom_Soll 1022 "kein Eingriff" 1023 "Fehler" ;
VAL_ 130 GE_MMom_Status 0 "keine Anforderung" 1 "reduzierender Getriebeeingriff" 2 "erhöhender Getriebeeingriff" 3 "Änderung mit Sprung" ;
VAL_ 130 GE_Status_Schaltablauf 0 "nicht_aktiv" 1 "Motorfuehrung_1" 2 "Motorfuehrung_2" 3 "Motorfuehrung_3" 4 "Motorfuehrung_4" 5 "Motorfuehrung_5" 6 "Motorfuehrung_6" 7 "Motorfuehrung_7" ;
VAL_ 130 GE_MMom_Vorhalt 1022 "keine_Anforderung" 1023 "Fehler" ;
VAL_ 130 GE_Freig_MMom_Vorhalt 0 "nicht_freigegeben" 1 "freigegeben" ;
VAL_ 130 GE_KD_Fehler 0 "kein_KD_Fehler" 1 "KD_Fehler" ;
